VERSION ""

NS_ :

BS_:

BU_: ETH

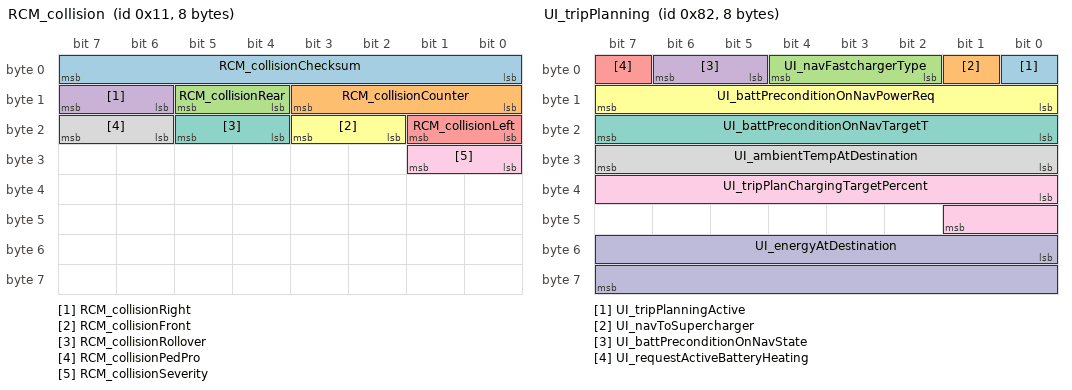
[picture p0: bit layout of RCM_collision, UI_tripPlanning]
BO_ 17 RCM_collision: 8 Vector__XXX
 SG_ RCM_collisionChecksum : 0|8@1+ (1,0) [0|0] "" Vector__XXX
 SG_ RCM_collisionCounter : 8|4@1+ (1,0) [0|0] "" Vector__XXX
 SG_ RCM_collisionRear : 12|2@1+ (1,0) [0|0] "" Vector__XXX
 SG_ RCM_collisionRight : 14|2@1+ (1,0) [0|0] "" Vector__XXX
 SG_ RCM_collisionLeft : 16|2@1+ (1,0) [0|0] "" Vector__XXX
 SG_ RCM_collisionFront : 18|2@1+ (1,0) [0|0] "" Vector__XXX
 SG_ RCM_collisionRollover : 20|2@1+ (1,0) [0|0] "" Vector__XXX
 SG_ RCM_collisionPedPro : 22|2@1+ (1,0) [0|0] "" Vector__XXX
 SG_ RCM_collisionSeverity : 24|2@1+ (1,0) [0|0] "" Vector__XXX

BO_ 79 UI_locationStatus: 8 Vector__XXX
 SG_ UI_latitude : 0|28@1- (1e-06,0) [0|0] "" Vector__XXX
 SG_ UI_longitude : 28|29@1- (1e-06,0) [0|0] "" Vector__XXX
 SG_ UI_gpsAccuracy : 57|7@1+ (0.2,0) [0|0] "" Vector__XXX

BO_ 130 UI_tripPlanning: 8 Vector__XXX
 SG_ UI_tripPlanningActive : 0|1@1+ (1,0) [0|0] "" Vector__XXX
 SG_ UI_navToSupercharger : 1|1@1+ (1,0) [0|0] "" Vector__XXX
 SG_ UI_navFastchargerType : 2|3@1+ (1,0) [0|0] "" Vector__XXX
 SG_ UI_battPreconditionOnNavState : 5|2@1+ (1,0) [0|0] "" Vector__XXX
 SG_ UI_requestActiveBatteryHeating : 7|1@1+ (1,0) [0|0] "" Vector__XXX
 SG_ UI_battPreconditionOnNavPowerReq : 8|8@1- (125,0) [0|0] "" Vector__XXX
 SG_ UI_battPreconditionOnNavTargetT : 16|8@1+ (0.25,0) [0|0] "" Vector__XXX
 SG_ UI_ambientTempAtDestination : 24|8@1- (0.5,0) [0|0] "" Vector__XXX
 SG_ UI_tripPlanChargingTargetPercent : 32|10@1+ (0.1,0) [0|0] "" Vector__XXX
 SG_ UI_energyAtDestination : 48|16@1- (0.01,0) [0|0] "" Vector__XXX

BO_ 258 VCLEFT_doorStatus: 8 Vector__XXX
 SG_ VCLEFT_doorClosureStatusFront : 0|4@1+ (1,0) [0|0] "" Vector__XXX
 SG_ VCLEFT_doorClosureStatusRear : 4|4@1+ (1,0) [0|0] "" Vector__XXX
 SG_ VCLEFT_frontLatchSwitch : 8|1@1+ (1,0) [0|0] "" Vector__XXX
 SG_ VCLEFT_rearLatchSwitch : 9|1@1+ (1,0) [0|0] "" Vector__XXX
 SG_ VCLEFT_frontHandlePulled : 10|1@1+ (1,0) [0|0] "" Vector__XXX
 SG_ VCLEFT_rearHandlePulled : 11|1@1+ (1,0) [0|0] "" Vector__XXX
 SG_ VCLEFT_frontRelActuatorSwitch : 12|1@1+ (1,0) [0|0] "" Vector__XXX
 SG_ VCLEFT_rearRelActuatorSwitch : 13|1@1+ (1,0) [0|0] "" Vector__XXX
 SG_ VCLEFT_frontLatchStatus : 14|4@1+ (1,0) [0|0] "" Vector__XXX
 SG_ VCLEFT_rearLatchStatus : 18|4@1+ (1,0) [0|0] "" Vector__XXX
 SG_ VCLEFT_lastDoorReqSourceFront : 22|3@1+ (1,0) [0|0] "" Vector__XXX
 SG_ VCLEFT_lastDoorReqSourceRear : 25|3@1+ (1,0) [0|0] "" Vector__XXX
 SG_ VCLEFT_frontIntSwitchFaulted : 28|1@1+ (1,0) [0|0] "" Vector__XXX
 SG_ VCLEFT_rearIntSwitchFaulted : 29|1@1+ (1,0) [0|0] "" Vector__XXX
 SG_ VCLEFT_frontIntSwitchPressed : 31|1@1+ (1,0) [0|0] "" Vector__XXX
 SG_ VCLEFT_rearIntSwitchPressed : 32|1@1+ (1,0) [0|0] "" Vector__XXX
 SG_ VCLEFT_mirrorTiltXPosition : 33|8@1+ (0.02,0) [0|0] "" Vector__XXX
 SG_ VCLEFT_mirrorTiltYPosition : 41|8@1+ (0.02,0) [0|0] "" Vector__XXX
 SG_ VCLEFT_mirrorState : 49|3@1+ (1,0) [0|0] "" Vector__XXX
 SG_ VCLEFT_mirrorFoldState : 52|3@1+ (1,0) [0|0] "" Vector__XXX
 SG_ VCLEFT_mirrorRecallState : 55|3@1+ (1,0) [0|0] "" Vector__XXX
 SG_ VCLEFT_mirrorHeatState : 58|3@1+ (1,0) [0|0] "" Vector__XXX
 SG_ VCLEFT_rearHandlePulledPersist : 61|1@1+ (1,0) [0|0] "" Vector__XXX
 SG_ VCLEFT_frontHandlePulledPersist : 62|1@1+ (1,0) [0|0] "" Vector__XXX
 SG_ VCLEFT_mirrorDipped : 63|1@1+ (1,0) [0|0] "" Vector__XXX

BO_ 259 VCRIGHT_doorStatus: 8 Vector__XXX
 SG_ VCRIGHT_doorClosureStatusFront : 0|4@1+ (1,0) [0|0] "" Vector__XXX
 SG_ VCRIGHT_doorClosureStatusRear : 4|4@1+ (1,0) [0|0] "" Vector__XXX
 SG_ VCRIGHT_frontLatchSwitch : 8|1@1+ (1,0) [0|0] "" Vector__XXX
 SG_ VCRIGHT_rearLatchSwitch : 9|1@1+ (1,0) [0|0] "" Vector__XXX
 SG_ VCRIGHT_frontHandlePulled : 10|1@1+ (1,0) [0|0] "" Vector__XXX
 SG_ VCRIGHT_rearHandlePulled : 11|1@1+ (1,0) [0|0] "" Vector__XXX
 SG_ VCRIGHT_frontRelActuatorSwitch : 12|1@1+ (1,0) [0|0] "" Vector__XXX
 SG_ VCRIGHT_rearRelActuatorSwitch : 13|1@1+ (1,0) [0|0] "" Vector__XXX
 SG_ VCRIGHT_frontLatchStatus : 14|4@1+ (1,0) [0|0] "" Vector__XXX
 SG_ VCRIGHT_rearLatchStatus : 18|4@1+ (1,0) [0|0] "" Vector__XXX
 SG_ VCRIGHT_lastDoorReqSourceFront : 22|3@1+ (1,0) [0|0] "" Vector__XXX
 SG_ VCRIGHT_lastDoorReqSourceRear : 25|3@1+ (1,0) [0|0] "" Vector__XXX
 SG_ VCRIGHT_frontIntSwitchFaulted : 28|1@1+ (1,0) [0|0] "" Vector__XXX
 SG_ VCRIGHT_rearIntSwitchFaulted : 29|1@1+ (1,0) [0|0] "" Vector__XXX
 SG_ VCRIGHT_frontHandlePulledPersist : 30|1@1+ (1,0) [0|0] "" Vector__XXX
 SG_ VCRIGHT_frontIntSwitchPressed : 31|1@1+ (1,0) [0|0] "" Vector__XXX
 SG_ VCRIGHT_rearIntSwitchPressed : 32|1@1+ (1,0) [0|0] "" Vector__XXX
 SG_ VCRIGHT_mirrorTiltXPosition : 33|8@1+ (0.02,0) [0|0] "" Vector__XXX
 SG_ VCRIGHT_mirrorTiltYPosition : 41|8@1+ (0.02,0) [0|0] "" Vector__XXX
 SG_ VCRIGHT_mirrorState : 49|3@1+ (1,0) [0|0] "" Vector__XXX
 SG_ VCRIGHT_mirrorFoldState : 52|3@1+ (1,0) [0|0] "" Vector__XXX
 SG_ VCRIGHT_mirrorDipped : 55|1@1+ (1,0) [0|0] "" Vector__XXX
 SG_ VCRIGHT_trunkLatchStatus : 56|4@1+ (1,0) [0|0] "" Vector__XXX
 SG_ VCRIGHT_mirrorRecallState : 60|3@1+ (1,0) [0|0] "" Vector__XXX
 SG_ VCRIGHT_rearHandlePulledPersist : 63|1@1+ (1,0) [0|0] "" Vector__XXX

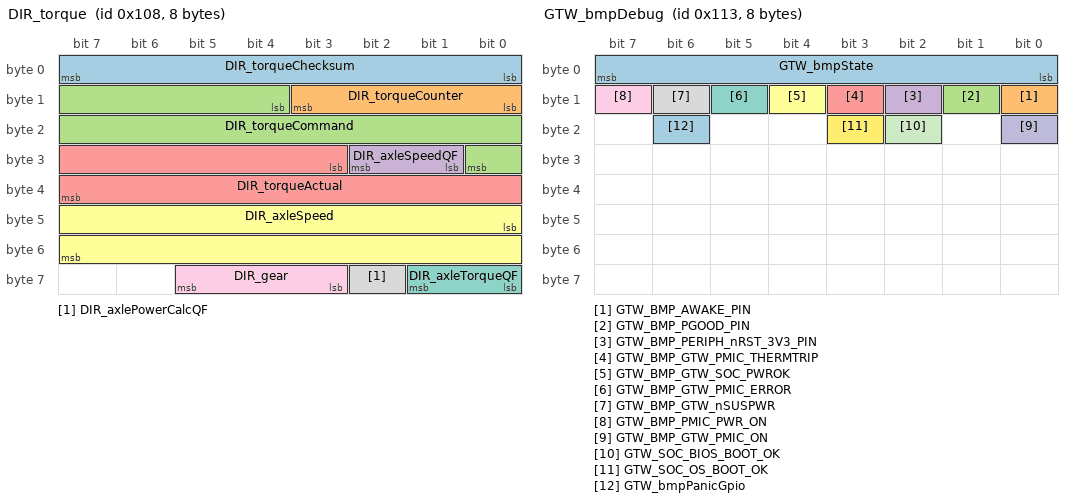
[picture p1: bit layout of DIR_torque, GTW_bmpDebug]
BO_ 264 DIR_torque: 8 Vector__XXX
 SG_ DIR_torqueChecksum : 0|8@1+ (1,0) [0|0] "" Vector__XXX
 SG_ DIR_torqueCounter : 8|4@1+ (1,0) [0|0] "" Vector__XXX
 SG_ DIR_torqueCommand : 12|13@1- (2,0) [0|0] "" Vector__XXX
 SG_ DIR_axleSpeedQF : 25|2@1+ (1,0) [0|0] "" Vector__XXX
 SG_ DIR_torqueActual : 27|13@1- (2,0) [0|0] "" Vector__XXX
 SG_ DIR_axleSpeed : 40|16@1- (0.1,0) [0|0] "" Vector__XXX
 SG_ DIR_axleTorqueQF : 56|2@1+ (1,0) [0|0] "" Vector__XXX
 SG_ DIR_axlePowerCalcQF : 58|1@1+ (1,0) [0|0] "" Vector__XXX
 SG_ DIR_gear : 59|3@1+ (1,0) [0|0] "" Vector__XXX

BO_ 275 GTW_bmpDebug: 8 Vector__XXX
 SG_ GTW_bmpState : 7|8@0+ (1,0) [0|0] "" Vector__XXX
 SG_ GTW_BMP_AWAKE_PIN : 8|1@1+ (1,0) [0|0] "" Vector__XXX
 SG_ GTW_BMP_PGOOD_PIN : 9|1@1+ (1,0) [0|0] "" Vector__XXX
 SG_ GTW_BMP_PERIPH_nRST_3V3_PIN : 10|1@1+ (1,0) [0|0] "" Vector__XXX
 SG_ GTW_BMP_GTW_PMIC_THERMTRIP : 11|1@1+ (1,0) [0|0] "" Vector__XXX
 SG_ GTW_BMP_GTW_SOC_PWROK : 12|1@1+ (1,0) [0|0] "" Vector__XXX
 SG_ GTW_BMP_GTW_PMIC_ERROR : 13|1@1+ (1,0) [0|0] "" Vector__XXX
 SG_ GTW_BMP_GTW_nSUSPWR : 14|1@1+ (1,0) [0|0] "" Vector__XXX
 SG_ GTW_BMP_PMIC_PWR_ON : 15|1@1+ (1,0) [0|0] "" Vector__XXX
 SG_ GTW_BMP_GTW_PMIC_ON : 16|1@1+ (1,0) [0|0] "" Vector__XXX
 SG_ GTW_SOC_BIOS_BOOT_OK : 18|1@1+ (1,0) [0|0] "" Vector__XXX
 SG_ GTW_SOC_OS_BOOT_OK : 19|1@1+ (1,0) [0|0] "" Vector__XXX
 SG_ GTW_bmpPanicGpio : 22|1@0+ (1,0) [0|0] "" Vector__XXX

BO_ 280 DI_systemStatus: 8 Vector__XXX
 SG_ DI_systemStatusChecksum : 0|8@1+ (1,0) [0|0] "" Vector__XXX
 SG_ DI_systemStatusCounter : 8|4@1+ (1,0) [0|0] "" Vector__XXX
 SG_ DI_immobilizerState : 13|3@1+ (1,0) [0|0] "" Vector__XXX
 SG_ DI_systemState : 16|3@1+ (1,0) [0|0] "" Vector__XXX
 SG_ DI_brakePedalState : 19|2@1+ (1,0) [0|0] "" Vector__XXX
 SG_ DI_gear : 21|3@1+ (1,0) [0|0] "" Vector__XXX
 SG_ DI_driveBlocked : 24|3@1+ (1,0) [0|0] "" Vector__XXX
 SG_ DI_hvilSystemStatus : 27|2@1+ (1,0) [0|0] "" Vector__XXX
 SG_ DI_accelPedalPos : 32|8@1+ (0.4,0) [0|0] "" Vector__XXX
 SG_ DI_tractionControlMode : 40|3@1+ (1,0) [0|0] "" Vector__XXX
 SG_ DI_dynoModeAvailable : 43|1@1+ (1,0) [0|0] "" Vector__XXX
 SG_ DI_epbRequest : 44|2@1+ (1,0) [0|0] "" Vector__XXX
 SG_ DI_eepDeliveryBitStatus : 46|1@1+ (1,0) [0|0] "" Vector__XXX
 SG_ DI_keepDrivePowerStateRequest : 47|1@1+ (1,0) [0|0] "" Vector__XXX
 SG_ DI_trackModeState : 48|2@1+ (1,0) [0|0] "" Vector__XXX
 SG_ DI_manualDrivingProhibited : 50|1@1+ (1,0) [0|0] "" Vector__XXX
 SG_ DI_regenLight : 51|1@1+ (1,0) [0|0] "" Vector__XXX
 SG_ DI_vehicleAcceleration : 52|12@1- (0.01,0) [0|0] "" Vector__XXX

BO_ 281 VCSEC_requests2: 8 Vector__XXX
 SG_ VCSEC_hvacRunScreenProtectOnly : 15|1@1+ (1,0) [0|0] "" Vector__XXX
 SG_ VCSEC_chargeHandleRequestModel : 16|4@1+ (1,0) [0|0] "" Vector__XXX
 SG_ VCSEC_recoveryModeRequested : 21|1@1+ (1,0) [0|0] "" Vector__XXX
 SG_ VCSEC_infotainmentResetRequested : 22|1@1+ (1,0) [0|0] "" Vector__XXX
 SG_ VCSEC_mobileToAPRequest : 23|3@1+ (1,0) [0|0] "" Vector__XXX
 SG_ VCSEC_riderKeyPresent : 26|1@1+ (1,0) [0|0] "" Vector__XXX

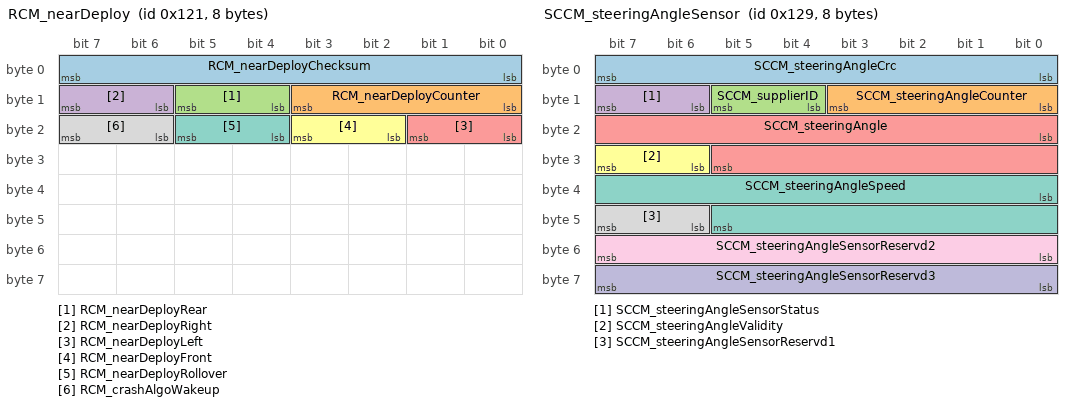
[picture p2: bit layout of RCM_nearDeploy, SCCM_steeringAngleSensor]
BO_ 289 RCM_nearDeploy: 8 Vector__XXX
 SG_ RCM_nearDeployChecksum : 0|8@1+ (1,0) [0|0] "" Vector__XXX
 SG_ RCM_nearDeployCounter : 8|4@1+ (1,0) [0|0] "" Vector__XXX
 SG_ RCM_nearDeployRear : 12|2@1+ (1,0) [0|0] "" Vector__XXX
 SG_ RCM_nearDeployRight : 14|2@1+ (1,0) [0|0] "" Vector__XXX
 SG_ RCM_nearDeployLeft : 16|2@1+ (1,0) [0|0] "" Vector__XXX
 SG_ RCM_nearDeployFront : 18|2@1+ (1,0) [0|0] "" Vector__XXX
 SG_ RCM_nearDeployRollover : 20|2@1+ (1,0) [0|0] "" Vector__XXX
 SG_ RCM_crashAlgoWakeup : 22|2@1+ (1,0) [0|0] "" Vector__XXX

BO_ 290 VCLEFT_doorStatus2: 8 Vector__XXX
 SG_ VCLEFT_doorStatus2Index M : 0|1@1+ (1,0) [0|0] "" Vector__XXX
 SG_ VCLEFT_frontLatchRelDuty m1 : 8|8@1+ (1,0) [0|0] "" Vector__XXX
 SG_ VCLEFT_rearLatchRelDuty m0 : 8|8@1+ (1,0) [0|0] "" Vector__XXX
 SG_ VCLEFT_BPillarCameraHeaterState m1 : 16|3@1+ (1,0) [0|0] "" Vector__XXX
 SG_ VCLEFT_vehicleInMotion m0 : 16|1@1+ (1,0) [0|0] "" Vector__XXX
 SG_ VCLEFT_frontDoorState m0 : 17|3@1+ (1,0) [0|0] "" Vector__XXX
 SG_ VCLEFT_rearDoorState m0 : 20|3@1+ (1,0) [0|0] "" Vector__XXX
 SG_ VCLEFT_frontHandleRawStatus m0 : 24|3@1+ (1,0) [0|0] "" Vector__XXX
 SG_ VCLEFT_rearHandleRawStatus m0 : 27|3@1+ (1,0) [0|0] "" Vector__XXX
 SG_ VCLEFT_mirrorFoldType m0 : 30|2@1+ (1,0) [0|0] "" Vector__XXX
 SG_ VCLEFT_frontHandleDebounceStatus m0 : 32|3@1+ (1,0) [0|0] "" Vector__XXX
 SG_ VCLEFT_rearHandleDebounceStatus m0 : 35|3@1+ (1,0) [0|0] "" Vector__XXX
 SG_ VCLEFT_frontHandle5vEnable m0 : 38|1@1+ (1,0) [0|0] "" Vector__XXX
 SG_ VCLEFT_rearHandle5vEnable m0 : 39|1@1+ (1,0) [0|0] "" Vector__XXX
 SG_ VCLEFT_BPillarCameraHeaterCurrent m1 : 40|6@1+ (0.02,0) [0|0] "" Vector__XXX
 SG_ VCLEFT_mirrorFoldCurrent m0 : 40|7@1- (0.05,0) [0|0] "" Vector__XXX
 SG_ VCLEFT_mirrorDimmed m0 : 47|1@1+ (1,0) [0|0] "" Vector__XXX
 SG_ VCLEFT_frontHandlePWM m0 : 48|7@1+ (1,0) [0|0] "" Vector__XXX
 SG_ VCLEFT_mirrorTiltXOffset m1 : 48|8@1- (0.02,0) [0|0] "" Vector__XXX
 SG_ VCLEFT_mirrorTiltYOffset m1 : 56|8@1- (0.02,0) [0|0] "" Vector__XXX
 SG_ VCLEFT_rearHandlePWM m0 : 56|7@1+ (1,0) [0|0] "" Vector__XXX

BO_ 291 VCRIGHT_doorStatus2: 8 Vector__XXX
 SG_ VCRIGHT_doorStatus2Index M : 0|1@1+ (1,0) [0|0] "" Vector__XXX
 SG_ VCRIGHT_frontLatchRelDuty m1 : 8|8@1+ (1,0) [0|0] "" Vector__XXX
 SG_ VCRIGHT_rearLatchRelDuty m0 : 8|8@1+ (1,0) [0|0] "" Vector__XXX
 SG_ VCRIGHT_BPillarCameraHeaterState m1 : 16|3@1+ (1,0) [0|0] "" Vector__XXX
 SG_ VCRIGHT_vehicleInMotion m0 : 16|1@1+ (1,0) [0|0] "" Vector__XXX
 SG_ VCRIGHT_frontDoorState m0 : 17|3@1+ (1,0) [0|0] "" Vector__XXX
 SG_ VCRIGHT_rearDoorState m0 : 20|3@1+ (1,0) [0|0] "" Vector__XXX
 SG_ VCRIGHT_mirrorDimmed m0 : 23|1@1+ (1,0) [0|0] "" Vector__XXX
 SG_ VCRIGHT_frontHandleRawStatus m0 : 24|3@1+ (1,0) [0|0] "" Vector__XXX
 SG_ VCRIGHT_rearHandleRawStatus m0 : 27|3@1+ (1,0) [0|0] "" Vector__XXX
 SG_ VCRIGHT_mirrorFoldType m0 : 30|2@1+ (1,0) [0|0] "" Vector__XXX
 SG_ VCRIGHT_frontHandleDebounceStatus m0 : 32|3@1+ (1,0) [0|0] "" Vector__XXX
 SG_ VCRIGHT_rearHandleDebounceStatus m0 : 35|3@1+ (1,0) [0|0] "" Vector__XXX
 SG_ VCRIGHT_frontHandle5vEnable m0 : 38|1@1+ (1,0) [0|0] "" Vector__XXX
 SG_ VCRIGHT_rearHandle5vEnable m0 : 39|1@1+ (1,0) [0|0] "" Vector__XXX
 SG_ VCRIGHT_BPillarCameraHeaterCurrent m1 : 40|6@1+ (0.02,0) [0|0] "" Vector__XXX
 SG_ VCRIGHT_mirrorFoldCurrent m0 : 40|7@1- (0.05,0) [0|0] "" Vector__XXX
 SG_ VCRIGHT_gloveboxOutput m0 : 47|1@1+ (1,0) [0|0] "" Vector__XXX
 SG_ VCRIGHT_mirrorTiltXOffset m1 : 48|8@1- (0.02,0) [0|0] "" Vector__XXX
 SG_ VCRIGHT_rearDefrostCurrentFiltered m0 : 48|7@1+ (1,0) [0|0] "" Vector__XXX
 SG_ VCRIGHT_mirrorTiltYOffset m1 : 56|8@1- (0.02,0) [0|0] "" Vector__XXX
 SG_ VCRIGHT_trunkRatchetSwitch m0 : 61|1@1+ (1,0) [0|0] "" Vector__XXX
 SG_ VCRIGHT_trunkPawlSwitch m0 : 62|1@1+ (1,0) [0|0] "" Vector__XXX
 SG_ VCRIGHT_trunkHomeSwitch m0 : 63|1@1+ (1,0) [0|0] "" Vector__XXX

BO_ 294 DIR_motorStatus: 8 Vector__XXX
 SG_ DIR_motorCurrent : 0|11@1+ (1,0) [0|0] "" Vector__XXX
 SG_ DIR_switchingFrequency : 11|11@1+ (0.01,0) [0|0] "" Vector__XXX
 SG_ DIR_targetFluxMode : 22|2@1+ (1,0) [0|0] "" Vector__XXX
 SG_ DIR_switchShortTestRetryCount : 24|2@1+ (1,0) [0|0] "" Vector__XXX
 SG_ DIR_keepAliveRequest : 26|1@1+ (1,0) [0|0] "" Vector__XXX
 SG_ DIR_motorStatusCounter : 27|4@1+ (1,0) [0|0] "" Vector__XXX
 SG_ DIR_motorStatusChecksum : 32|8@1+ (1,0) [0|0] "" Vector__XXX

BO_ 296 DI_systemLimits: 8 Vector__XXX
 SG_ DI_limitRegenPower : 0|1@1+ (1,0) [0|0] "" Vector__XXX
 SG_ DI_limitIBat : 1|1@1+ (1,0) [0|0] "" Vector__XXX
 SG_ DI_limitVBatLow : 2|1@1+ (1,0) [0|0] "" Vector__XXX
 SG_ DI_limitVBatHigh : 3|1@1+ (1,0) [0|0] "" Vector__XXX
 SG_ DI_limitObstacleDetection : 4|1@1+ (1,0) [0|0] "" Vector__XXX
 SG_ DI_limitSystemLimp : 5|1@1+ (1,0) [0|0] "" Vector__XXX
 SG_ DI_limitSystemGPO : 6|1@1+ (1,0) [0|0] "" Vector__XXX
 SG_ DI_limitShift : 7|1@1+ (1,0) [0|0] "" Vector__XXX
 SG_ DI_limitDriveTorque : 8|1@1+ (1,0) [0|0] "" Vector__XXX
 SG_ DI_limitRegenTorque : 9|1@1+ (1,0) [0|0] "" Vector__XXX
 SG_ DI_limitVehicleSpeed : 10|1@1+ (1,0) [0|0] "" Vector__XXX
 SG_ DI_limitBmsMiaFreeze : 11|1@1+ (1,0) [0|0] "" Vector__XXX
 SG_ DI_limitSystemSpinDownLearning : 12|1@1+ (1,0) [0|0] "" Vector__XXX
 SG_ DI_limitCdp : 13|1@1+ (1,0) [0|0] "" Vector__XXX
 SG_ DI_vehicleSpeedLimitType : 14|2@1+ (1,0) [0|0] "" Vector__XXX
 SG_ DI_vehicleSpeedLimit : 16|9@1+ (1,0) [0|0] "" Vector__XXX
 SG_ DI_vehicleSpeedLimitReason : 25|4@1+ (1,0) [0|0] "" Vector__XXX
 SG_ DI_limitClosureNotClosed : 29|1@1+ (1,0) [0|0] "" Vector__XXX
 SG_ DI_proximity : 30|1@1+ (1,0) [0|0] "" Vector__XXX
 SG_ DI_undersideAbuse : 31|1@1+ (1,0) [0|0] "" Vector__XXX

BO_ 297 SCCM_steeringAngleSensor: 8 Vector__XXX
 SG_ SCCM_steeringAngleCrc : 0|8@1+ (1,0) [0|0] "" Vector__XXX
 SG_ SCCM_steeringAngleCounter : 8|4@1+ (1,0) [0|0] "" Vector__XXX
 SG_ SCCM_supplierID : 12|2@1+ (1,0) [0|0] "" Vector__XXX
 SG_ SCCM_steeringAngleSensorStatus : 14|2@1+ (1,0) [0|0] "" Vector__XXX
 SG_ SCCM_steeringAngle : 16|14@1+ (0.1,-819.2) [0|0] "" Vector__XXX
 SG_ SCCM_steeringAngleValidity : 30|2@1+ (1,0) [0|0] "" Vector__XXX
 SG_ SCCM_steeringAngleSpeed : 32|14@1+ (0.5,-4096) [0|0] "" Vector__XXX
 SG_ SCCM_steeringAngleSensorReservd1 : 46|2@1+ (1,0) [0|0] "" Vector__XXX
 SG_ SCCM_steeringAngleSensorReservd2 : 48|8@1+ (1,0) [0|0] "" Vector__XXX
 SG_ SCCM_steeringAngleSensorReservd3 : 56|8@1+ (1,0) [0|0] "" Vector__XXX

BO_ 306 BMS_hvBusStatus: 8 Vector__XXX
 SG_ BMS_dcLinkVoltage : 0|16@1+ (0.01,0) [0|0] "" Vector__XXX
 SG_ BMS_packCurrent : 16|16@1- (0.1,0) [0|0] "" Vector__XXX
 SG_ BMS_currentUnfiltered : 32|16@1- (0.05,-822) [0|0] "" Vector__XXX

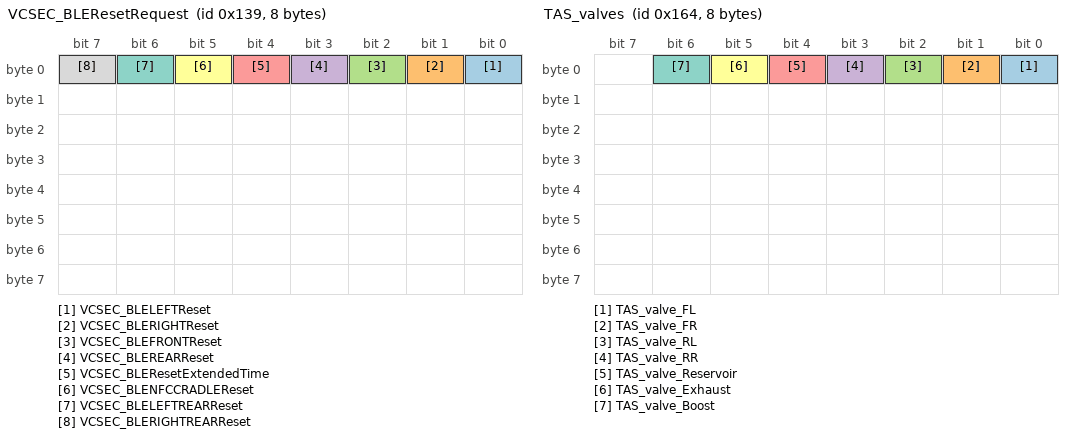
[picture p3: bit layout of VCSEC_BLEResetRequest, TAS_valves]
BO_ 313 VCSEC_BLEResetRequest: 8 Vector__XXX
 SG_ VCSEC_BLELEFTReset : 0|1@1+ (1,0) [0|0] "" Vector__XXX
 SG_ VCSEC_BLERIGHTReset : 1|1@1+ (1,0) [0|0] "" Vector__XXX
 SG_ VCSEC_BLEFRONTReset : 2|1@1+ (1,0) [0|0] "" Vector__XXX
 SG_ VCSEC_BLEREARReset : 3|1@1+ (1,0) [0|0] "" Vector__XXX
 SG_ VCSEC_BLEResetExtendedTime : 4|1@1+ (1,0) [0|0] "" Vector__XXX
 SG_ VCSEC_BLENFCCRADLEReset : 5|1@1+ (1,0) [0|0] "" Vector__XXX
 SG_ VCSEC_BLELEFTREARReset : 6|1@1+ (1,0) [0|0] "" Vector__XXX
 SG_ VCSEC_BLERIGHTREARReset : 7|1@1+ (1,0) [0|0] "" Vector__XXX

BO_ 322 VCLEFT_liftgateStatus: 8 Vector__XXX
 SG_ VCLEFT_liftgateStatusIndex M : 0|2@1+ (1,0) [0|0] "" Vector__XXX
 SG_ VCLEFT_liftgateState m0 : 3|4@1+ (1,0) [0|0] "" Vector__XXX
 SG_ VCLEFT_liftgateStrutDutyCycle m1 : 3|8@1- (1,0) [0|0] "" Vector__XXX
 SG_ VCLEFT_liftgateStoppingCondition m0 : 10|4@1+ (1,0) [0|0] "" Vector__XXX
 SG_ VCLEFT_liftgateStrutCurrent m1 : 11|10@1- (0.1,0) [0|0] "" Vector__XXX
 SG_ VCLEFT_liftgateMvmntNotAllowedCondition m0 : 14|3@1+ (1,0) [0|0] "" Vector__XXX
 SG_ VCLEFT_liftgatePositionCalibrated m0 : 17|1@1+ (1,0) [0|0] "" Vector__XXX
 SG_ VCLEFT_liftgateUIChimeRequest m0 : 18|3@1+ (1,0) [0|0] "" Vector__XXX
 SG_ VCLEFT_liftgatePhysicalChimeRequest m0 : 21|3@1+ (1,0) [0|0] "" Vector__XXX
 SG_ VCLEFT_liftgatePosition m1 : 21|7@1- (1,46) [0|0] "" Vector__XXX
 SG_ VCLEFT_liftgateEstimatedStrutTemp m0 : 24|8@1+ (1,-60) [0|0] "" Vector__XXX
 SG_ VCLEFT_liftgateSpeed m1 : 28|10@1- (0.1,0) [0|0] "" Vector__XXX
 SG_ VCLEFT_liftgateStaticStrutMode m0 : 32|3@1+ (1,0) [0|0] "" Vector__XXX
 SG_ VCLEFT_liftgateRequestSource m0 : 35|4@1+ (1,0) [0|0] "" Vector__XXX
 SG_ VCLEFT_liftgateHeight m1 : 38|8@1+ (1,0) [0|0] "" Vector__XXX
 SG_ VCLEFT_liftgateNewHeightNudge m0 : 39|1@1+ (1,0) [0|0] "" Vector__XXX
 SG_ VCLEFT_liftgateNewSaveHeight m0 : 40|8@1+ (1,0) [0|0] "" Vector__XXX
 SG_ VCLEFT_liftgateGeofenceState m0 : 48|2@1+ (1,0) [0|0] "" Vector__XXX
 SG_ VCLEFT_liftgateAboveCrossoverAngle m0 : 59|1@1+ (1,0) [0|0] "" Vector__XXX
 SG_ VCLEFT_liftgateLatchRequest m0 : 61|3@1+ (1,0) [0|0] "" Vector__XXX

BO_ 356 TAS_valves: 8 Vector__XXX
 SG_ TAS_valve_FL : 0|1@1+ (1,0) [0|0] "" Vector__XXX
 SG_ TAS_valve_FR : 1|1@1+ (1,0) [0|0] "" Vector__XXX
 SG_ TAS_valve_RL : 2|1@1+ (1,0) [0|0] "" Vector__XXX
 SG_ TAS_valve_RR : 3|1@1+ (1,0) [0|0] "" Vector__XXX
 SG_ TAS_valve_Reservoir : 4|1@1+ (1,0) [0|0] "" Vector__XXX
 SG_ TAS_valve_Exhaust : 5|1@1+ (1,0) [0|0] "" Vector__XXX
 SG_ TAS_valve_Boost : 6|1@1+ (1,0) [0|0] "" Vector__XXX

BO_ 357 TAS_voltages: 8 Vector__XXX
 SG_ TAS_12V_supply : 0|8@1+ (0.075,0) [0|0] "" Vector__XXX
 SG_ TAS_12V_switched : 8|8@1+ (0.075,0) [0|0] "" Vector__XXX
 SG_ TAS_5V_heightSensors : 16|8@1+ (0.025,0) [0|0] "" Vector__XXX
 SG_ TAS_5V_analogSensors : 24|8@1+ (0.025,0) [0|0] "" Vector__XXX
 SG_ TAS_5V_onboard : 32|8@1+ (0.025,0) [0|0] "" Vector__XXX

BO_ 358 TAS_temperatures: 8 Vector__XXX
 SG_ TAS_tempIndex M : 0|2@1+ (1,0) [0|0] "" Vector__XXX
 SG_ TAS_temp_FL_C m0 : 8|8@1+ (1,-40) [0|0] "" Vector__XXX
 SG_ TAS_temp_K_HSD m2 : 8|8@1+ (1,-40) [0|0] "" Vector__XXX
 SG_ TAS_temp_RL_C m1 : 8|8@1+ (1,-40) [0|0] "" Vector__XXX
 SG_ TAS_temp_FL_R m0 : 16|8@1+ (1,-40) [0|0] "" Vector__XXX
 SG_ TAS_temp_RL_R m1 : 16|8@1+ (1,-40) [0|0] "" Vector__XXX
 SG_ TAS_temp_VBAT_SW m2 : 16|8@1+ (1,-40) [0|0] "" Vector__XXX
 SG_ TAS_temp_FL_K m0 : 24|8@1+ (1,-40) [0|0] "" Vector__XXX
 SG_ TAS_temp_RL_K m1 : 24|8@1+ (1,-40) [0|0] "" Vector__XXX
 SG_ TAS_temp_FR_C m0 : 32|8@1+ (1,-40) [0|0] "" Vector__XXX
 SG_ TAS_temp_RR_C m1 : 32|8@1+ (1,-40) [0|0] "" Vector__XXX
 SG_ TAS_temp_FR_R m0 : 40|8@1+ (1,-40) [0|0] "" Vector__XXX
 SG_ TAS_temp_RR_R m1 : 40|8@1+ (1,-40) [0|0] "" Vector__XXX
 SG_ TAS_temp_FR_K m0 : 48|8@1+ (1,-40) [0|0] "" Vector__XXX
 SG_ TAS_temp_RR_K m1 : 48|8@1+ (1,-40) [0|0] "" Vector__XXX
 SG_ TAS_temp_F_CR_HSD m0 : 56|8@1+ (1,-40) [0|0] "" Vector__XXX
 SG_ TAS_temp_R_CR_HSD m1 : 56|8@1+ (1,-40) [0|0] "" Vector__XXX

BO_ 359 TAS_currentsSpring: 8 Vector__XXX
 SG_ TAS_current_FL_K : 0|8@1+ (0.01,0) [0|0] "" Vector__XXX
 SG_ TAS_current_FR_K : 8|8@1+ (0.01,0) [0|0] "" Vector__XXX
 SG_ TAS_current_RL_K : 16|8@1+ (0.01,0) [0|0] "" Vector__XXX
 SG_ TAS_current_RR_K : 24|8@1+ (0.01,0) [0|0] "" Vector__XXX

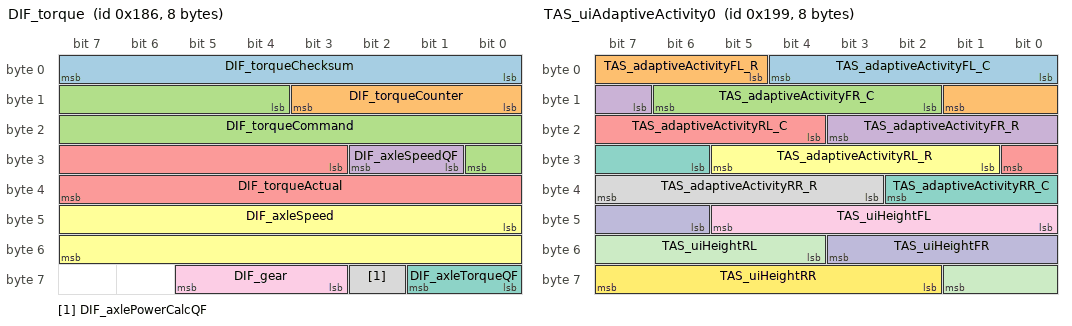
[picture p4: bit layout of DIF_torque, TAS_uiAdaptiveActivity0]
BO_ 390 DIF_torque: 8 Vector__XXX
 SG_ DIF_torqueChecksum : 0|8@1+ (1,0) [0|0] "" Vector__XXX
 SG_ DIF_torqueCounter : 8|4@1+ (1,0) [0|0] "" Vector__XXX
 SG_ DIF_torqueCommand : 12|13@1- (2,0) [0|0] "" Vector__XXX
 SG_ DIF_axleSpeedQF : 25|2@1+ (1,0) [0|0] "" Vector__XXX
 SG_ DIF_torqueActual : 27|13@1- (2,0) [0|0] "" Vector__XXX
 SG_ DIF_axleSpeed : 40|16@1- (0.1,0) [0|0] "" Vector__XXX
 SG_ DIF_axleTorqueQF : 56|2@1+ (1,0) [0|0] "" Vector__XXX
 SG_ DIF_axlePowerCalcQF : 58|1@1+ (1,0) [0|0] "" Vector__XXX
 SG_ DIF_gear : 59|3@1+ (1,0) [0|0] "" Vector__XXX

BO_ 405 DIF_limits: 8 Vector__XXX
 SG_ DIF_limitPCBTemp : 0|1@1+ (1,0) [0|0] "" Vector__XXX
 SG_ DIF_limitInverterTemp : 1|1@1+ (1,0) [0|0] "" Vector__XXX
 SG_ DIF_limitStatorTemp : 2|1@1+ (1,0) [0|0] "" Vector__XXX
 SG_ DIF_limitPoleTemp : 3|1@1+ (1,0) [0|0] "" Vector__XXX
 SG_ DIF_limitUnitLimp : 4|1@1+ (1,0) [0|0] "" Vector__XXX
 SG_ DIF_limitDeltaFluidTemp : 5|1@1+ (1,0) [0|0] "" Vector__XXX
 SG_ DIF_limitDischargePower : 6|1@1+ (1,0) [0|0] "" Vector__XXX
 SG_ DIF_limitMotorCurrent : 7|1@1+ (1,0) [0|0] "" Vector__XXX
 SG_ DIF_limitMotorVoltage : 8|1@1+ (1,0) [0|0] "" Vector__XXX
 SG_ DIF_limitTCDrive : 9|1@1+ (1,0) [0|0] "" Vector__XXX
 SG_ DIF_limitTCRegen : 10|1@1+ (1,0) [0|0] "" Vector__XXX
 SG_ DIF_limitBaseSpeed : 11|1@1+ (1,0) [0|0] "" Vector__XXX
 SG_ DIF_limitDcCapTemp : 12|1@1+ (1,0) [0|0] "" Vector__XXX
 SG_ DIF_limitMotorSpeed : 13|1@1+ (1,0) [0|0] "" Vector__XXX
 SG_ DIF_limitDiff : 14|1@1+ (1,0) [0|0] "" Vector__XXX
 SG_ DIF_limitUnitGPO : 15|1@1+ (1,0) [0|0] "" Vector__XXX
 SG_ DIF_limitShockTorque : 16|1@1+ (1,0) [0|0] "" Vector__XXX
 SG_ DIF_limitOilPumpFluidTemp : 17|1@1+ (1,0) [0|0] "" Vector__XXX
 SG_ DIF_limitStatorFrequency : 18|1@1+ (1,0) [0|0] "" Vector__XXX
 SG_ DIF_limitClutch : 19|1@1+ (1,0) [0|0] "" Vector__XXX
 SG_ DIF_limitphaseOutBusbarTemp : 20|1@1+ (1,0) [0|0] "" Vector__XXX
 SG_ DIF_limitphaseOutBusBarWeldTemp : 21|1@1+ (1,0) [0|0] "" Vector__XXX
 SG_ DIF_limitphaseOutLugTemp : 22|1@1+ (1,0) [0|0] "" Vector__XXX
 SG_ DIF_limitdcLinkCapTemp : 23|1@1+ (1,0) [0|0] "" Vector__XXX
 SG_ DIF_limitnegDcBusbarTemp : 24|1@1+ (1,0) [0|0] "" Vector__XXX
 SG_ DIF_limitposDcBusbarTemp : 25|1@1+ (1,0) [0|0] "" Vector__XXX
 SG_ DIF_limitRotorTemp : 26|1@1+ (1,0) [0|0] "" Vector__XXX
 SG_ DIF_limithvDcCableTemp : 27|1@1+ (1,0) [0|0] "" Vector__XXX
 SG_ DIF_limitUnitSpinDownLearning : 28|1@1+ (1,0) [0|0] "" Vector__XXX
 SG_ DIF_limitStatorHousingTemp : 29|1@1+ (1,0) [0|0] "" Vector__XXX
 SG_ DIF_statorTempFromResist : 30|8@1+ (1,-40) [0|0] "" Vector__XXX
 SG_ DIF_magnetFluxError : 38|8@1- (8e-05,0) [0|0] "" Vector__XXX
 SG_ DIF_currentLimit : 46|16@1+ (0.1,0) [0|0] "" Vector__XXX
 SG_ DIF_pstgDisableHW3PS : 62|1@1+ (1,0) [0|0] "" Vector__XXX
 SG_ DIF_pstgDisableSW3PS : 63|1@1+ (1,0) [0|0] "" Vector__XXX

BO_ 409 TAS_uiAdaptiveActivity0: 8 Vector__XXX
 SG_ TAS_adaptiveActivityFL_C : 0|5@1+ (0.04,0) [0|0] "" Vector__XXX
 SG_ TAS_adaptiveActivityFL_R : 5|5@1+ (0.04,0) [0|0] "" Vector__XXX
 SG_ TAS_adaptiveActivityFR_C : 10|5@1+ (0.04,0) [0|0] "" Vector__XXX
 SG_ TAS_adaptiveActivityFR_R : 15|5@1+ (0.04,0) [0|0] "" Vector__XXX
 SG_ TAS_adaptiveActivityRL_C : 20|5@1+ (0.04,0) [0|0] "" Vector__XXX
 SG_ TAS_adaptiveActivityRL_R : 25|5@1+ (0.04,0) [0|0] "" Vector__XXX
 SG_ TAS_adaptiveActivityRR_C : 30|5@1+ (0.04,0) [0|0] "" Vector__XXX
 SG_ TAS_adaptiveActivityRR_R : 35|5@1+ (0.04,0) [0|0] "" Vector__XXX
 SG_ TAS_uiHeightFL : 40|6@1+ (4,-128) [0|0] "" Vector__XXX
 SG_ TAS_uiHeightFR : 46|6@1+ (4,-128) [0|0] "" Vector__XXX
 SG_ TAS_uiHeightRL : 52|6@1+ (4,-128) [0|0] "" Vector__XXX
 SG_ TAS_uiHeightRR : 58|6@1+ (4,-128) [0|0] "" Vector__XXX

BO_ 410 TAS_uiAdaptiveActivity1: 8 Vector__XXX
 SG_ TAS_bodyAccelFL : 0|8@1+ (0.05,-5) [0|0] "" Vector__XXX
 SG_ TAS_bodyAccelFR : 8|8@1+ (0.05,-5) [0|0] "" Vector__XXX
 SG_ TAS_bodyAccelRL : 16|8@1+ (0.05,-5) [0|0] "" Vector__XXX
 SG_ TAS_bodyAccelRR : 24|8@1+ (0.05,-5) [0|0] "" Vector__XXX

BO_ 421 DIF_motorStatus: 8 Vector__XXX
 SG_ DIF_motorCurrent : 0|11@1+ (1,0) [0|0] "" Vector__XXX
 SG_ DIF_switchingFrequency : 11|11@1+ (0.01,0) [0|0] "" Vector__XXX
 SG_ DIF_targetFluxMode : 22|2@1+ (1,0) [0|0] "" Vector__XXX
 SG_ DIF_switchShortTestRetryCount : 24|2@1+ (1,0) [0|0] "" Vector__XXX
 SG_ DIF_keepAliveRequest : 26|1@1+ (1,0) [0|0] "" Vector__XXX
 SG_ DIF_motorStatusCounter : 27|4@1+ (1,0) [0|0] "" Vector__XXX
 SG_ DIF_motorStatusChecksum : 32|8@1+ (1,0) [0|0] "" Vector__XXX

BO_ 443 UI_peripheralPowerRequests: 8 Vector__XXX
 SG_ UI_usbFrontHubPowerStateRequest : 0|2@1+ (1,0) [0|0] "" Vector__XXX

BO_ 455 TASDBG_currentsDamper: 8 Vector__XXX
 SG_ TASDBG_current_FL_C : 0|8@1+ (0.0075,0) [0|0] "" Vector__XXX
 SG_ TASDBG_current_FL_R : 8|8@1+ (0.0075,0) [0|0] "" Vector__XXX
 SG_ TASDBG_current_FR_C : 16|8@1+ (0.0075,0) [0|0] "" Vector__XXX
 SG_ TASDBG_current_FR_R : 24|8@1+ (0.0075,0) [0|0] "" Vector__XXX
 SG_ TASDBG_current_RL_C : 32|8@1+ (0.0075,0) [0|0] "" Vector__XXX
 SG_ TASDBG_current_RL_R : 40|8@1+ (0.0075,0) [0|0] "" Vector__XXX
 SG_ TASDBG_current_RR_C : 48|8@1+ (0.0075,0) [0|0] "" Vector__XXX
 SG_ TASDBG_current_RR_R : 56|8@1+ (0.0075,0) [0|0] "" Vector__XXX

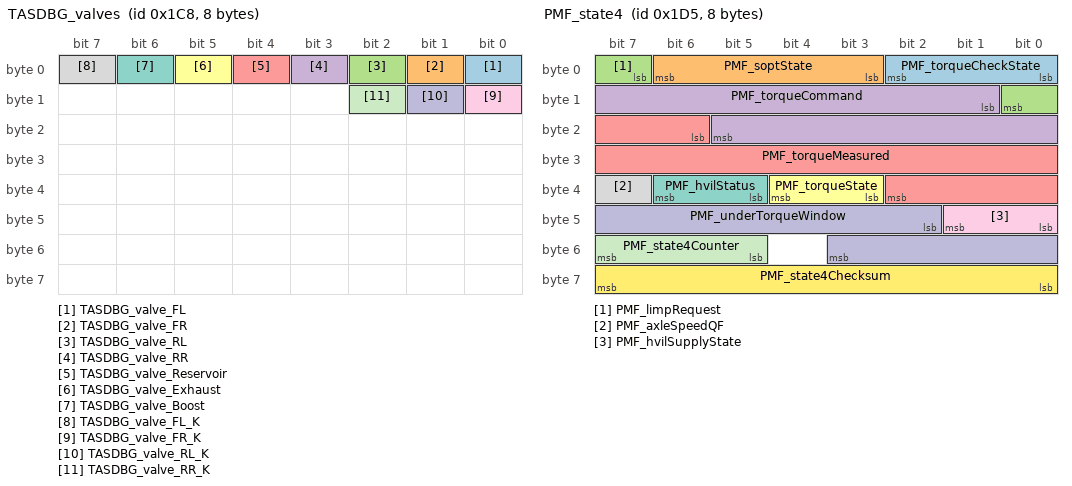
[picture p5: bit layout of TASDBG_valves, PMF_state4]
BO_ 456 TASDBG_valves: 8 Vector__XXX
 SG_ TASDBG_valve_FL : 0|1@1+ (1,0) [0|0] "" Vector__XXX
 SG_ TASDBG_valve_FR : 1|1@1+ (1,0) [0|0] "" Vector__XXX
 SG_ TASDBG_valve_RL : 2|1@1+ (1,0) [0|0] "" Vector__XXX
 SG_ TASDBG_valve_RR : 3|1@1+ (1,0) [0|0] "" Vector__XXX
 SG_ TASDBG_valve_Reservoir : 4|1@1+ (1,0) [0|0] "" Vector__XXX
 SG_ TASDBG_valve_Exhaust : 5|1@1+ (1,0) [0|0] "" Vector__XXX
 SG_ TASDBG_valve_Boost : 6|1@1+ (1,0) [0|0] "" Vector__XXX
 SG_ TASDBG_valve_FL_K : 7|1@1+ (1,0) [0|0] "" Vector__XXX
 SG_ TASDBG_valve_FR_K : 8|1@1+ (1,0) [0|0] "" Vector__XXX
 SG_ TASDBG_valve_RL_K : 9|1@1+ (1,0) [0|0] "" Vector__XXX
 SG_ TASDBG_valve_RR_K : 10|1@1+ (1,0) [0|0] "" Vector__XXX

BO_ 469 PMF_state4: 8 Vector__XXX
 SG_ PMF_torqueCheckState : 0|3@1+ (1,0) [0|0] "" Vector__XXX
 SG_ PMF_soptState : 3|4@1+ (1,0) [0|0] "" Vector__XXX
 SG_ PMF_limpRequest : 7|2@1+ (1,0) [0|0] "" Vector__XXX
 SG_ PMF_torqueCommand : 9|13@1- (2,0) [0|0] "" Vector__XXX
 SG_ PMF_torqueMeasured : 22|13@1- (2,0) [0|0] "" Vector__XXX
 SG_ PMF_torqueState : 35|2@1+ (1,0) [0|0] "" Vector__XXX
 SG_ PMF_hvilStatus : 37|2@1+ (1,0) [0|0] "" Vector__XXX
 SG_ PMF_axleSpeedQF : 39|1@1+ (1,0) [0|0] "" Vector__XXX
 SG_ PMF_hvilSupplyState : 40|2@1+ (1,0) [0|0] "" Vector__XXX
 SG_ PMF_underTorqueWindow : 42|10@1+ (0.005,0) [0|0] "" Vector__XXX
 SG_ PMF_state4Counter : 53|3@1+ (1,0) [0|0] "" Vector__XXX
 SG_ PMF_state4Checksum : 56|8@1+ (1,0) [0|0] "" Vector__XXX

BO_ 470 DIR_limits: 8 Vector__XXX
 SG_ DIR_limitPCBTemp : 0|1@1+ (1,0) [0|0] "" Vector__XXX
 SG_ DIR_limitInverterTemp : 1|1@1+ (1,0) [0|0] "" Vector__XXX
 SG_ DIR_limitStatorTemp : 2|1@1+ (1,0) [0|0] "" Vector__XXX
 SG_ DIR_limitPoleTemp : 3|1@1+ (1,0) [0|0] "" Vector__XXX
 SG_ DIR_limitUnitLimp : 4|1@1+ (1,0) [0|0] "" Vector__XXX
 SG_ DIR_limitDeltaFluidTemp : 5|1@1+ (1,0) [0|0] "" Vector__XXX
 SG_ DIR_limitDischargePower : 6|1@1+ (1,0) [0|0] "" Vector__XXX
 SG_ DIR_limitMotorCurrent : 7|1@1+ (1,0) [0|0] "" Vector__XXX
 SG_ DIR_limitMotorVoltage : 8|1@1+ (1,0) [0|0] "" Vector__XXX
 SG_ DIR_limitTCDrive : 9|1@1+ (1,0) [0|0] "" Vector__XXX
 SG_ DIR_limitTCRegen : 10|1@1+ (1,0) [0|0] "" Vector__XXX
 SG_ DIR_limitBaseSpeed : 11|1@1+ (1,0) [0|0] "" Vector__XXX
 SG_ DIR_limitDcCapTemp : 12|1@1+ (1,0) [0|0] "" Vector__XXX
 SG_ DIR_limitMotorSpeed : 13|1@1+ (1,0) [0|0] "" Vector__XXX
 SG_ DIR_limitDiff : 14|1@1+ (1,0) [0|0] "" Vector__XXX
 SG_ DIR_limitUnitGPO : 15|1@1+ (1,0) [0|0] "" Vector__XXX
 SG_ DIR_limitShockTorque : 16|1@1+ (1,0) [0|0] "" Vector__XXX
 SG_ DIR_limitOilPumpFluidTemp : 17|1@1+ (1,0) [0|0] "" Vector__XXX
 SG_ DIR_limitStatorFrequency : 18|1@1+ (1,0) [0|0] "" Vector__XXX
 SG_ DIR_limitClutch : 19|1@1+ (1,0) [0|0] "" Vector__XXX
 SG_ DIR_limitphaseOutBusbarTemp : 20|1@1+ (1,0) [0|0] "" Vector__XXX
 SG_ DIR_limitphaseOutBusBarWeldTemp : 21|1@1+ (1,0) [0|0] "" Vector__XXX
 SG_ DIR_limitphaseOutLugTemp : 22|1@1+ (1,0) [0|0] "" Vector__XXX
 SG_ DIR_limitdcLinkCapTemp : 23|1@1+ (1,0) [0|0] "" Vector__XXX
 SG_ DIR_limitnegDcBusbarTemp : 24|1@1+ (1,0) [0|0] "" Vector__XXX
 SG_ DIR_limitposDcBusbarTemp : 25|1@1+ (1,0) [0|0] "" Vector__XXX
 SG_ DIR_limitRotorTemp : 26|1@1+ (1,0) [0|0] "" Vector__XXX
 SG_ DIR_limithvDcCableTemp : 27|1@1+ (1,0) [0|0] "" Vector__XXX
 SG_ DIR_limitUnitSpinDownLearning : 28|1@1+ (1,0) [0|0] "" Vector__XXX
 SG_ DIR_limitStatorHousingTemp : 29|1@1+ (1,0) [0|0] "" Vector__XXX
 SG_ DIR_statorTempFromResist : 30|8@1+ (1,-40) [0|0] "" Vector__XXX
 SG_ DIR_magnetFluxError : 38|8@1- (8e-05,0) [0|0] "" Vector__XXX
 SG_ DIR_currentLimit : 46|16@1+ (0.1,0) [0|0] "" Vector__XXX
 SG_ DIR_pstgDisableHW3PS : 62|1@1+ (1,0) [0|0] "" Vector__XXX
 SG_ DIR_pstgDisableSW3PS : 63|1@1+ (1,0) [0|0] "" Vector__XXX

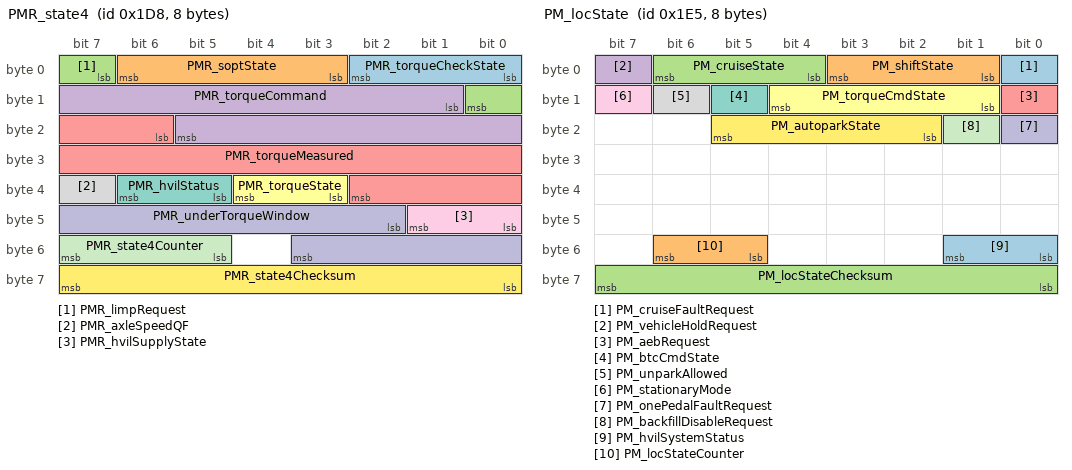
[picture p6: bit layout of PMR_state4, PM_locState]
BO_ 472 PMR_state4: 8 Vector__XXX
 SG_ PMR_torqueCheckState : 0|3@1+ (1,0) [0|0] "" Vector__XXX
 SG_ PMR_soptState : 3|4@1+ (1,0) [0|0] "" Vector__XXX
 SG_ PMR_limpRequest : 7|2@1+ (1,0) [0|0] "" Vector__XXX
 SG_ PMR_torqueCommand : 9|13@1- (2,0) [0|0] "" Vector__XXX
 SG_ PMR_torqueMeasured : 22|13@1- (2,0) [0|0] "" Vector__XXX
 SG_ PMR_torqueState : 35|2@1+ (1,0) [0|0] "" Vector__XXX
 SG_ PMR_hvilStatus : 37|2@1+ (1,0) [0|0] "" Vector__XXX
 SG_ PMR_axleSpeedQF : 39|1@1+ (1,0) [0|0] "" Vector__XXX
 SG_ PMR_hvilSupplyState : 40|2@1+ (1,0) [0|0] "" Vector__XXX
 SG_ PMR_underTorqueWindow : 42|10@1+ (0.005,0) [0|0] "" Vector__XXX
 SG_ PMR_state4Counter : 53|3@1+ (1,0) [0|0] "" Vector__XXX
 SG_ PMR_state4Checksum : 56|8@1+ (1,0) [0|0] "" Vector__XXX

BO_ 473 VCSEC_IsoTpUDPPipeUI: 8 Vector__XXX
 SG_ VCSEC_IsoTpUDPPipeUI0 : 0|8@1+ (1,0) [0|0] "" Vector__XXX
 SG_ VCSEC_IsoTpUDPPipeUI1 : 8|8@1+ (1,0) [0|0] "" Vector__XXX
 SG_ VCSEC_IsoTpUDPPipeUI2 : 16|8@1+ (1,0) [0|0] "" Vector__XXX
 SG_ VCSEC_IsoTpUDPPipeUI3 : 24|8@1+ (1,0) [0|0] "" Vector__XXX
 SG_ VCSEC_IsoTpUDPPipeUI4 : 32|8@1+ (1,0) [0|0] "" Vector__XXX
 SG_ VCSEC_IsoTpUDPPipeUI5 : 40|8@1+ (1,0) [0|0] "" Vector__XXX
 SG_ VCSEC_IsoTpUDPPipeUI6 : 48|8@1+ (1,0) [0|0] "" Vector__XXX
 SG_ VCSEC_IsoTpUDPPipeUI7 : 56|8@1+ (1,0) [0|0] "" Vector__XXX

BO_ 474 VCSEC_IsoTpPipeRemoteUI: 8 Vector__XXX
 SG_ VCSEC_IsoTpRemoteUI0 : 0|8@1+ (1,0) [0|0] "" Vector__XXX
 SG_ VCSEC_IsoTpRemoteUI1 : 8|8@1+ (1,0) [0|0] "" Vector__XXX
 SG_ VCSEC_IsoTpRemoteUI2 : 16|8@1+ (1,0) [0|0] "" Vector__XXX
 SG_ VCSEC_IsoTpRemoteUI3 : 24|8@1+ (1,0) [0|0] "" Vector__XXX
 SG_ VCSEC_IsoTpRemoteUI4 : 32|8@1+ (1,0) [0|0] "" Vector__XXX
 SG_ VCSEC_IsoTpRemoteUI5 : 40|8@1+ (1,0) [0|0] "" Vector__XXX
 SG_ VCSEC_IsoTpRemoteUI6 : 48|8@1+ (1,0) [0|0] "" Vector__XXX
 SG_ VCSEC_IsoTpRemoteUI7 : 56|8@1+ (1,0) [0|0] "" Vector__XXX

BO_ 485 PM_locState: 8 Vector__XXX
 SG_ PM_cruiseFaultRequest : 0|1@1+ (1,0) [0|0] "" Vector__XXX
 SG_ PM_shiftState : 1|3@1+ (1,0) [0|0] "" Vector__XXX
 SG_ PM_cruiseState : 4|3@1+ (1,0) [0|0] "" Vector__XXX
 SG_ PM_vehicleHoldRequest : 7|1@1+ (1,0) [0|0] "" Vector__XXX
 SG_ PM_aebRequest : 8|1@1+ (1,0) [0|0] "" Vector__XXX
 SG_ PM_torqueCmdState : 9|4@1+ (1,0) [0|0] "" Vector__XXX
 SG_ PM_btcCmdState : 13|1@1+ (1,0) [0|0] "" Vector__XXX
 SG_ PM_unparkAllowed : 14|1@1+ (1,0) [0|0] "" Vector__XXX
 SG_ PM_stationaryMode : 15|1@1+ (1,0) [0|0] "" Vector__XXX
 SG_ PM_onePedalFaultRequest : 16|1@1+ (1,0) [0|0] "" Vector__XXX
 SG_ PM_backfillDisableRequest : 17|1@1+ (1,0) [0|0] "" Vector__XXX
 SG_ PM_autoparkState : 18|4@1+ (1,0) [0|0] "" Vector__XXX
 SG_ PM_hvilSystemStatus : 48|2@1+ (1,0) [0|0] "" Vector__XXX
 SG_ PM_locStateCounter : 53|2@1+ (1,0) [0|0] "" Vector__XXX
 SG_ PM_locStateChecksum : 56|8@1+ (1,0) [0|0] "" Vector__XXX

BO_ 504 VCLEFT_intrusionSensorStatus: 8 Vector__XXX
 SG_ VCLEFT_DBG_System_Status : 0|3@1+ (1,0) [0|0] "" Vector__XXX
 SG_ VCLEFT_DBG_Air_Cond_Status : 3|1@1+ (1,0) [0|0] "" Vector__XXX
 SG_ VCLEFT_DBG_Heater_Status : 4|1@1+ (1,0) [0|0] "" Vector__XXX
 SG_ VCLEFT_DBG_Window_Status : 5|1@1+ (1,0) [0|0] "" Vector__XXX
 SG_ VCLEFT_DBG_Suspensions_Status : 6|1@1+ (1,0) [0|0] "" Vector__XXX
 SG_ VCLEFT_DBG_SelfTest_Status : 7|1@1+ (1,0) [0|0] "" Vector__XXX
 SG_ VCLEFT_DBG_Veh_Settings_Status : 8|4@1+ (1,0) [0|0] "" Vector__XXX
 SG_ VCLEFT_DBG_USS_Alarm_Status : 12|1@1+ (1,0) [0|0] "" Vector__XXX
 SG_ VCLEFT_DBG_LM_Alarm_Status : 13|1@1+ (1,0) [0|0] "" Vector__XXX
 SG_ VCLEFT_DBG_Siren_ST_Status : 14|1@1+ (1,0) [0|0] "" Vector__XXX
 SG_ VCLEFT_DBG_Siren_Int_Trigger : 15|1@1+ (1,0) [0|0] "" Vector__XXX
 SG_ VCLEFT_DBG_Invalid_Parameter : 16|1@1+ (1,0) [0|0] "" Vector__XXX
 SG_ VCLEFT_DBG_Siren_is_sounding : 17|1@1+ (1,0) [0|0] "" Vector__XXX
 SG_ VCLEFT_DBG_Reserved_07 : 18|1@1+ (1,0) [0|0] "" Vector__XXX
 SG_ VCLEFT_DBG_Reserved_08 : 19|1@1+ (1,0) [0|0] "" Vector__XXX
 SG_ VCLEFT_DBG_Eeprom_ST_Status : 20|1@1+ (1,0) [0|0] "" Vector__XXX
 SG_ VCLEFT_DBG_USS_SelfTest_Status : 21|1@1+ (1,0) [0|0] "" Vector__XXX
 SG_ VCLEFT_DBG_LM_SelfTest_Status : 22|1@1+ (1,0) [0|0] "" Vector__XXX
 SG_ VCLEFT_DBG_System_Error : 23|1@1+ (1,0) [0|0] "" Vector__XXX
 SG_ VCLEFT_sirenMIA : 24|1@1+ (1,0) [0|0] "" Vector__XXX
 SG_ VCLEFT_intrusionTiltTripped : 25|1@1+ (1,0) [0|0] "" Vector__XXX
 SG_ VCLEFT_intrusionUltraTripped : 26|1@1+ (1,0) [0|0] "" Vector__XXX

BO_ 505 VCSEC_requests: 8 Vector__XXX
 SG_ VCSEC_chargePortRequest : 0|2@1+ (1,0) [0|0] "" Vector__XXX
 SG_ VCSEC_presentHandles : 4|1@1+ (1,0) [0|0] "" Vector__XXX
 SG_ VCSEC_frontLeftClosureRequest : 5|3@1+ (1,0) [0|0] "" Vector__XXX
 SG_ VCSEC_frontRightClosureRequest : 8|3@1+ (1,0) [0|0] "" Vector__XXX
 SG_ VCSEC_rearLeftClosureRequest : 11|3@1+ (1,0) [0|0] "" Vector__XXX
 SG_ VCSEC_rearRightClosureRequest : 14|3@1+ (1,0) [0|0] "" Vector__XXX
 SG_ VCSEC_rearTrunkClosureRequest : 17|3@1+ (1,0) [0|0] "" Vector__XXX
 SG_ VCSEC_frontLeftRequestReason : 20|3@1+ (1,0) [0|0] "" Vector__XXX
 SG_ VCSEC_frontRightRequestReason : 23|3@1+ (1,0) [0|0] "" Vector__XXX
 SG_ VCSEC_rearLeftRequestReason : 26|3@1+ (1,0) [0|0] "" Vector__XXX
 SG_ VCSEC_rearRightRequestReason : 29|3@1+ (1,0) [0|0] "" Vector__XXX
 SG_ VCSEC_rearTrunkRequestReason : 32|3@1+ (1,0) [0|0] "" Vector__XXX
 SG_ VCSEC_rdMapDumpRequested : 35|1@1+ (1,0) [0|0] "" Vector__XXX
 SG_ VCSEC_driveAttemptedWithoutAuth : 36|4@1+ (1,0) [0|0] "" Vector__XXX
 SG_ VCSEC_closeAllStatus : 41|2@1+ (1,0) [0|0] "" Vector__XXX
 SG_ VCSEC_snapshotRequested : 43|4@1+ (1,0) [0|0] "" Vector__XXX
 SG_ VCSEC_chargeportRequestReason : 47|3@1+ (1,0) [0|0] "" Vector__XXX
 SG_ VCSEC_frontTrunkClosureRequest : 51|3@1+ (1,0) [0|0] "" Vector__XXX
 SG_ VCSEC_frontTrunkRequestReason : 54|3@1+ (1,0) [0|0] "" Vector__XXX

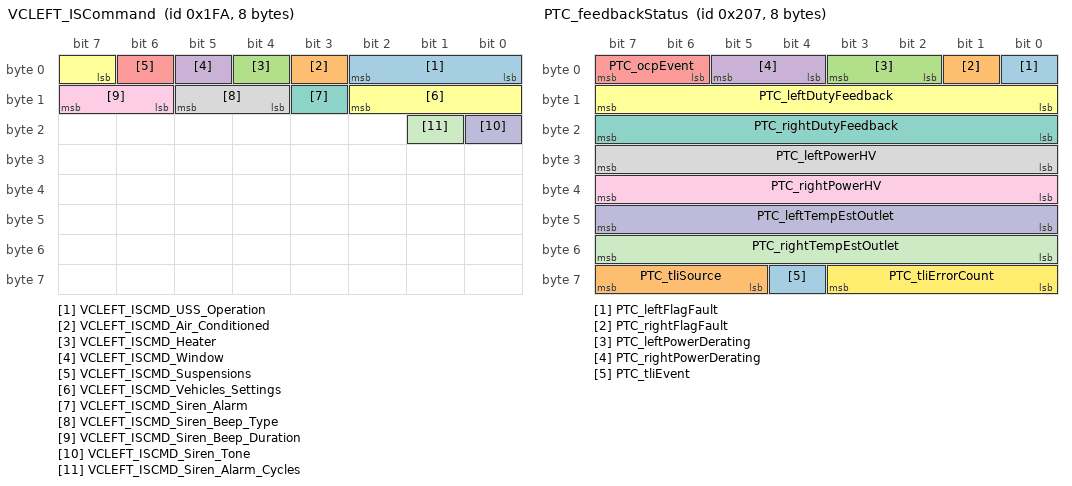
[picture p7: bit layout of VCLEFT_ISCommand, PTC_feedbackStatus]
BO_ 506 VCLEFT_ISCommand: 8 Vector__XXX
 SG_ VCLEFT_ISCMD_USS_Operation : 0|3@1+ (1,0) [0|0] "" Vector__XXX
 SG_ VCLEFT_ISCMD_Air_Conditioned : 3|1@1+ (1,0) [0|0] "" Vector__XXX
 SG_ VCLEFT_ISCMD_Heater : 4|1@1+ (1,0) [0|0] "" Vector__XXX
 SG_ VCLEFT_ISCMD_Window : 5|1@1+ (1,0) [0|0] "" Vector__XXX
 SG_ VCLEFT_ISCMD_Suspensions : 6|1@1+ (1,0) [0|0] "" Vector__XXX
 SG_ VCLEFT_ISCMD_Vehicles_Settings : 7|4@1+ (1,0) [0|0] "" Vector__XXX
 SG_ VCLEFT_ISCMD_Siren_Alarm : 11|1@1+ (1,0) [0|0] "" Vector__XXX
 SG_ VCLEFT_ISCMD_Siren_Beep_Type : 12|2@1+ (1,0) [0|0] "" Vector__XXX
 SG_ VCLEFT_ISCMD_Siren_Beep_Duration : 14|2@1+ (1,0) [0|0] "" Vector__XXX
 SG_ VCLEFT_ISCMD_Siren_Tone : 16|1@1+ (1,0) [0|0] "" Vector__XXX
 SG_ VCLEFT_ISCMD_Siren_Alarm_Cycles : 17|1@1+ (1,0) [0|0] "" Vector__XXX

BO_ 507 VCLEFT_TLCStatus: 8 Vector__XXX
 SG_ VCLEFT_TLCStatusIndex M : 0|2@1+ (1,0) [0|0] "" Vector__XXX
 SG_ VCLEFT_TLCTemperature m1 : 2|8@1- (1,68) [0|0] "" Vector__XXX
 SG_ VCLEFT_TLCLeftTurnCurrent m0 : 8|8@1+ (0.1,0) [0|0] "" Vector__XXX
 SG_ VCLEFT_TLCLeftTurnVoltage m1 : 10|8@1+ (0.1,0) [0|0] "" Vector__XXX
 SG_ VCLEFT_TLCRightTurnCurrent m0 : 16|8@1+ (0.1,0) [0|0] "" Vector__XXX
 SG_ VCLEFT_TLCRightTurnVoltage m1 : 18|8@1+ (0.1,0) [0|0] "" Vector__XXX
 SG_ VCLEFT_TLCTailCurrent m0 : 24|8@1+ (0.1,0) [0|0] "" Vector__XXX
 SG_ VCLEFT_TLCState_LeftTurn m1 : 26|3@1+ (1,0) [0|0] "" Vector__XXX
 SG_ VCLEFT_TLCState_RightTurn m1 : 29|3@1+ (1,0) [0|0] "" Vector__XXX
 SG_ VCLEFT_TLCState_Tail m1 : 32|3@1+ (1,0) [0|0] "" Vector__XXX
 SG_ VCLEFT_TLCStopCurrent m0 : 32|8@1+ (0.1,0) [0|0] "" Vector__XXX
 SG_ VCLEFT_TLCState_Stop m1 : 35|3@1+ (1,0) [0|0] "" Vector__XXX
 SG_ VCLEFT_TLCState_Fog m1 : 38|3@1+ (1,0) [0|0] "" Vector__XXX
 SG_ VCLEFT_TLCFogCurrent m0 : 40|8@1+ (0.1,0) [0|0] "" Vector__XXX
 SG_ VCLEFT_TLCState_Reverse m1 : 41|3@1+ (1,0) [0|0] "" Vector__XXX
 SG_ VCLEFT_TLCReverseCurrent m0 : 48|8@1+ (0.1,0) [0|0] "" Vector__XXX
 SG_ VCLEFT_TLCTotalCurrent m0 : 56|8@1+ (0.1,0) [0|0] "" Vector__XXX

BO_ 508 APP_roadDisturbance: 8 Vector__XXX
 SG_ APP_roadDisturbanceIndex : 0|2@1+ (1,0) [0|0] "" Vector__XXX
 SG_ APP_roadDisturbanceHeight : 2|6@1+ (0.02,-0.64) [0|0] "" Vector__XXX
 SG_ APP_roadDisturbanceX0 : 8|8@1+ (0.5,0) [0|0] "" Vector__XXX
 SG_ APP_roadDisturbanceX1 : 16|8@1+ (0.5,0) [0|0] "" Vector__XXX
 SG_ APP_roadDisturbanceY0 : 24|8@1+ (0.1,-12.8) [0|0] "" Vector__XXX
 SG_ APP_roadDisturbanceY1 : 32|8@1+ (0.1,-12.8) [0|0] "" Vector__XXX
 SG_ APP_suspensionLevelRequest : 40|4@1+ (1,0) [0|0] "" Vector__XXX

BO_ 513 VCFRONT_loggingAndVitals10Hz: 8 Vector__XXX
 SG_ VCFRONT_loggingAndVitals10HzIndex M : 0|3@1+ (1,0) [0|0] "" Vector__XXX
 SG_ VCFRONT_chillerExvFlow m2 : 3|8@1+ (0.5,0) [0|0] "" Vector__XXX
 SG_ VCFRONT_chillerExvFlowTarget m3 : 3|8@1+ (0.5,0) [0|0] "" Vector__XXX
 SG_ VCFRONT_fanDemand m1 : 3|7@1+ (1,0) [0|0] "" Vector__XXX
 SG_ VCFRONT_pumpBatteryRPMActual m0 : 8|8@1+ (30,0) [0|0] "" Vector__XXX
 SG_ VCFRONT_compressorState m1 : 10|2@1+ (1,0) [0|0] "" Vector__XXX
 SG_ VCFRONT_evapExvFlow m2 : 11|8@1+ (0.5,0) [0|0] "" Vector__XXX
 SG_ VCFRONT_evapExvFlowTarget m3 : 11|8@1+ (0.5,0) [0|0] "" Vector__XXX
 SG_ VCFRONT_compDemandEvap m1 : 12|7@1+ (1,0) [0|0] "" Vector__XXX
 SG_ VCFRONT_pumpPowertrainRPMActual m0 : 16|8@1+ (30,0) [0|0] "" Vector__XXX
 SG_ VCFRONT_exvState m1 : 19|4@1+ (1,0) [0|0] "" Vector__XXX
 SG_ VCFRONT_recircExvFlow m2 : 19|8@1+ (0.5,0) [0|0] "" Vector__XXX
 SG_ VCFRONT_recircExvFlowTarget m3 : 19|8@1+ (0.5,0) [0|0] "" Vector__XXX
 SG_ VCFRONT_solenoidEvapState m1 : 23|2@1+ (1,0) [0|0] "" Vector__XXX
 SG_ VCFRONT_radiatorFanRPMActual m0 : 24|8@1+ (40,0) [0|0] "" Vector__XXX
 SG_ VCFRONT_compDemandChiller m1 : 25|7@1+ (1,0) [0|0] "" Vector__XXX
 SG_ VCFRONT_lccExvFlow m2 : 27|8@1+ (0.5,0) [0|0] "" Vector__XXX
 SG_ VCFRONT_lccExvFlowTarget m3 : 27|8@1+ (0.5,0) [0|0] "" Vector__XXX
 SG_ VCFRONT_coolantValveMode m1 : 32|2@1+ (1,0) [0|0] "" Vector__XXX
 SG_ VCFRONT_exvFlowTarget m0 : 32|8@1+ (0.5,0) [0|0] "" Vector__XXX
 SG_ VCFRONT_compFaultSeverity m1 : 34|2@1+ (1,0) [0|0] "" Vector__XXX
 SG_ VCFRONT_cclExvFlow m2 : 35|8@1+ (0.5,0) [0|0] "" Vector__XXX
 SG_ VCFRONT_cclExvFlowTarget m3 : 35|8@1+ (0.5,0) [0|0] "" Vector__XXX
 SG_ VCFRONT_solenoidEngaged m1 : 36|1@1+ (1,0) [0|0] "" Vector__XXX
 SG_ VCFRONT_hpHighSideHX m1 : 37|2@1+ (1,0) [0|0] "" Vector__XXX
 SG_ VCFRONT_hpLowSideHX m1 : 39|2@1+ (1,0) [0|0] "" Vector__XXX
 SG_ VCFRONT_activeLouverOpenPosTarg m0 : 40|7@1+ (1,0) [0|0] "" Vector__XXX
 SG_ VCFRONT_hpDominantLoad m1 : 41|3@1+ (1,0) [0|0] "" Vector__XXX
 SG_ VCFRONT_ccrExvFlow m2 : 43|8@1+ (0.5,0) [0|0] "" Vector__XXX
 SG_ VCFRONT_ccrExvFlowTarget m3 : 43|8@1+ (0.5,0) [0|0] "" Vector__XXX
 SG_ VCFRONT_hpBlendType m1 : 44|2@1+ (1,0) [0|0] "" Vector__XXX
 SG_ VCFRONT_hpQuietModeEnabled m1 : 46|1@1+ (1,0) [0|0] "" Vector__XXX
 SG_ VCFRONT_hpCabinLoadType m1 : 47|2@1+ (1,0) [0|0] "" Vector__XXX
 SG_ VCFRONT_pressureRefrigLiquid m0 : 47|9@1+ (0.08,0) [0|0] "" Vector__XXX
 SG_ VCFRONT_hpBatteryLoadType m1 : 49|2@1+ (1,0) [0|0] "" Vector__XXX
 SG_ VCFRONT_chillerExvState m2 : 51|4@1+ (1,0) [0|0] "" Vector__XXX
 SG_ VCFRONT_hpReqCoolantMode m1 : 51|3@1+ (1,0) [0|0] "" Vector__XXX
 SG_ VCFRONT_lccExvState m3 : 51|4@1+ (1,0) [0|0] "" Vector__XXX
 SG_ VCFRONT_hpReqTransScavenge m1 : 54|1@1+ (1,0) [0|0] "" Vector__XXX
 SG_ VCFRONT_cclExvState m3 : 55|4@1+ (1,0) [0|0] "" Vector__XXX
 SG_ VCFRONT_compLiqPumpOutState m1 : 55|3@1+ (1,0) [0|0] "" Vector__XXX
 SG_ VCFRONT_evapExvState m2 : 55|4@1+ (1,0) [0|0] "" Vector__XXX
 SG_ VCFRONT_compSleepRequest m0 : 56|1@1+ (1,0) [0|0] "" Vector__XXX
 SG_ VCFRONT_thermalHvPowerBudget m0 : 57|7@1+ (0.2,0) [0|0] "" Vector__XXX
 SG_ VCFRONT_frunkStateDBG m1 : 58|4@1+ (1,0) [0|0] "" Vector__XXX
 SG_ VCFRONT_ccrExvState m3 : 59|4@1+ (1,0) [0|0] "" Vector__XXX
 SG_ VCFRONT_recircExvState m2 : 59|4@1+ (1,0) [0|0] "" Vector__XXX
 SG_ VCFRONT_frunkSwitchGroupState m1 : 62|2@1+ (1,0) [0|0] "" Vector__XXX

BO_ 516 PCS_chgStatus: 8 Vector__XXX
 SG_ PCS_chgMainState : 0|4@1+ (1,0) [0|0] "" Vector__XXX
 SG_ PCS_powerTransferStatus : 4|2@1+ (1,0) [0|0] "" Vector__XXX
 SG_ PCS_gridConfig : 6|2@1+ (1,0) [0|0] "" Vector__XXX
 SG_ PCS_chgPHAEnable : 8|1@1+ (1,0) [0|0] "" Vector__XXX
 SG_ PCS_chgPHBEnable : 9|1@1+ (1,0) [0|0] "" Vector__XXX
 SG_ PCS_hvInletConductorEnergizedAc : 10|1@1+ (1,0) [0|0] "" Vector__XXX
 SG_ PCS_chgHighPowerActive : 11|1@1+ (1,0) [0|0] "" Vector__XXX
 SG_ PCS_chgPHCEnable : 12|1@1+ (1,0) [0|0] "" Vector__XXX
 SG_ PCS_chgInstantAcPowerAvailable : 16|8@1+ (0.1,0) [0|0] "" Vector__XXX
 SG_ PCS_chgMaxAcPowerAvailable : 24|8@1+ (0.1,0) [0|0] "" Vector__XXX
 SG_ PCS_chgPHALineCurrentRequest : 32|8@1+ (0.1,0) [0|0] "" Vector__XXX
 SG_ PCS_chgPHBLineCurrentRequest : 40|8@1+ (0.1,0) [0|0] "" Vector__XXX
 SG_ PCS_chgPHCLineCurrentRequest : 48|8@1+ (0.1,0) [0|0] "" Vector__XXX
 SG_ PCS_chgPwmEnableLine : 56|1@1+ (1,0) [0|0] "" Vector__XXX
 SG_ PCS_powerTransferShutdownRequest : 57|2@1+ (1,0) [0|0] "" Vector__XXX
 SG_ PCS_hwVariantType : 59|2@1+ (1,0) [0|0] "" Vector__XXX
 SG_ PCS_dcacBidirectionalAllowed : 61|1@1+ (1,0) [0|0] "" Vector__XXX

BO_ 519 PTC_feedbackStatus: 8 Vector__XXX
 SG_ PTC_leftFlagFault : 0|1@1+ (1,0) [0|0] "" Vector__XXX
 SG_ PTC_rightFlagFault : 1|1@1+ (1,0) [0|0] "" Vector__XXX
 SG_ PTC_leftPowerDerating : 2|2@1+ (1,0) [0|0] "" Vector__XXX
 SG_ PTC_rightPowerDerating : 4|2@1+ (1,0) [0|0] "" Vector__XXX
 SG_ PTC_ocpEvent : 6|2@1+ (1,0) [0|0] "" Vector__XXX
 SG_ PTC_leftDutyFeedback : 8|8@1+ (0.5,0) [0|0] "" Vector__XXX
 SG_ PTC_rightDutyFeedback : 16|8@1+ (0.5,0) [0|0] "" Vector__XXX
 SG_ PTC_leftPowerHV : 24|8@1+ (30,0) [0|0] "" Vector__XXX
 SG_ PTC_rightPowerHV : 32|8@1+ (30,0) [0|0] "" Vector__XXX
 SG_ PTC_leftTempEstOutlet : 40|8@1+ (1,-40) [0|0] "" Vector__XXX
 SG_ PTC_rightTempEstOutlet : 48|8@1+ (1,-40) [0|0] "" Vector__XXX
 SG_ PTC_tliErrorCount : 56|4@1+ (1,0) [0|0] "" Vector__XXX
 SG_ PTC_tliEvent : 60|1@1+ (1,0) [0|0] "" Vector__XXX
 SG_ PTC_tliSource : 61|3@1+ (1,0) [0|0] "" Vector__XXX

BO_ 522 HVP_contactorState: 8 Vector__XXX
 SG_ HVP_packContNegativeState : 0|3@1+ (1,0) [0|0] "" Vector__XXX
 SG_ HVP_packContPositiveState : 3|3@1+ (1,0) [0|0] "" Vector__XXX
 SG_ HVP_fcContPositiveAuxOpen : 6|1@1+ (1,0) [0|0] "" Vector__XXX
 SG_ HVP_fcContNegativeAuxOpen : 7|1@1+ (1,0) [0|0] "" Vector__XXX
 SG_ HVP_packContactorSetState : 8|4@1+ (1,0) [0|0] "" Vector__XXX
 SG_ HVP_fcContNegativeState : 12|3@1+ (1,0) [0|0] "" Vector__XXX
 SG_ HVP_contactorsBlocked : 15|1@1+ (1,0) [0|0] "" Vector__XXX
 SG_ HVP_fcContPositiveState : 16|3@1+ (1,0) [0|0] "" Vector__XXX
 SG_ HVP_fcContactorSetState : 19|4@1+ (1,0) [0|0] "" Vector__XXX
 SG_ HVP_fcCtrsRequestStatus : 24|2@1+ (1,0) [0|0] "" Vector__XXX
 SG_ HVP_fcCtrsResetRequestRequired : 26|1@1+ (1,0) [0|0] "" Vector__XXX
 SG_ HVP_fcCtrsOpenNowRequested : 27|1@1+ (1,0) [0|0] "" Vector__XXX
 SG_ HVP_fcCtrsOpenRequested : 28|1@1+ (1,0) [0|0] "" Vector__XXX
 SG_ HVP_fcCtrsClosingAllowed : 29|1@1+ (1,0) [0|0] "" Vector__XXX
 SG_ HVP_packCtrsRequestStatus : 30|2@1+ (1,0) [0|0] "" Vector__XXX
 SG_ HVP_packCtrsResetRequestRequired : 32|1@1+ (1,0) [0|0] "" Vector__XXX
 SG_ HVP_packCtrsOpenNowRequested : 33|1@1+ (1,0) [0|0] "" Vector__XXX
 SG_ HVP_packCtrsOpenRequested : 34|1@1+ (1,0) [0|0] "" Vector__XXX
 SG_ HVP_packCtrsClosingAllowed : 35|1@1+ (1,0) [0|0] "" Vector__XXX
 SG_ HVP_dcLinkAllowedToEnergize : 36|1@1+ (1,0) [0|0] "" Vector__XXX
 SG_ HVP_pyroTestInProgress : 37|1@1+ (1,0) [0|0] "" Vector__XXX
 SG_ HVP_hvilDiag : 40|4@1+ (1,0) [0|0] "" Vector__XXX
 SG_ HVP_fcLinkAllowedToEnergize : 44|2@1+ (1,0) [0|0] "" Vector__XXX

BO_ 523 TAS_axleData: 8 Vector__XXX
 SG_ TAS_axleIndex M : 0|1@1+ (1,0) [0|0] "" Vector__XXX
 SG_ TAS_rawHeightFL m0 : 4|10@1+ (1,-512) [0|0] "" Vector__XXX
 SG_ TAS_rawHeightRL m1 : 4|10@1+ (1,-512) [0|0] "" Vector__XXX
 SG_ TAS_staticHeightEstimateFL m0 : 14|10@1+ (1,-512) [0|0] "" Vector__XXX
 SG_ TAS_staticHeightEstimateRL m1 : 14|10@1+ (1,-512) [0|0] "" Vector__XXX
 SG_ TAS_componentPressureFL m0 : 24|8@1+ (0.1,0) [0|0] "" Vector__XXX
 SG_ TAS_componentPressureRL m1 : 24|8@1+ (0.1,0) [0|0] "" Vector__XXX
 SG_ TAS_rawHeightFR m0 : 32|10@1+ (1,-512) [0|0] "" Vector__XXX
 SG_ TAS_rawHeightRR m1 : 32|10@1+ (1,-512) [0|0] "" Vector__XXX
 SG_ TAS_staticHeightEstimateFR m0 : 42|10@1+ (1,-512) [0|0] "" Vector__XXX
 SG_ TAS_staticHeightEstimateRR m1 : 42|10@1+ (1,-512) [0|0] "" Vector__XXX
 SG_ TAS_componentPressureFR m0 : 52|8@1+ (0.1,0) [0|0] "" Vector__XXX
 SG_ TAS_componentPressureRR m1 : 52|8@1+ (0.1,0) [0|0] "" Vector__XXX

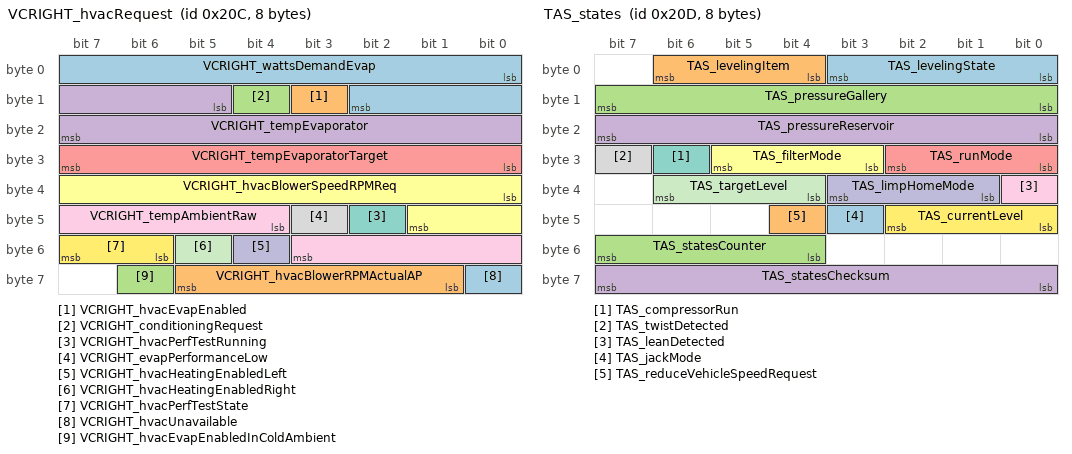
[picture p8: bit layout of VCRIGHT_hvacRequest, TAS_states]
BO_ 524 VCRIGHT_hvacRequest: 8 Vector__XXX
 SG_ VCRIGHT_wattsDemandEvap : 0|11@1+ (5,0) [0|0] "" Vector__XXX
 SG_ VCRIGHT_hvacEvapEnabled : 11|1@1+ (1,0) [0|0] "" Vector__XXX
 SG_ VCRIGHT_conditioningRequest : 12|1@1+ (1,0) [0|0] "" Vector__XXX
 SG_ VCRIGHT_tempEvaporator : 13|11@1+ (0.1,-40) [0|0] "" Vector__XXX
 SG_ VCRIGHT_tempEvaporatorTarget : 24|8@1+ (0.2,0) [0|0] "" Vector__XXX
 SG_ VCRIGHT_hvacBlowerSpeedRPMReq : 32|10@1+ (5,0) [0|0] "" Vector__XXX
 SG_ VCRIGHT_hvacPerfTestRunning : 42|1@1+ (1,0) [0|0] "" Vector__XXX
 SG_ VCRIGHT_evapPerformanceLow : 43|1@1+ (1,0) [0|0] "" Vector__XXX
 SG_ VCRIGHT_tempAmbientRaw : 44|8@1+ (0.5,-40) [0|0] "" Vector__XXX
 SG_ VCRIGHT_hvacHeatingEnabledLeft : 52|1@1+ (1,0) [0|0] "" Vector__XXX
 SG_ VCRIGHT_hvacHeatingEnabledRight : 53|1@1+ (1,0) [0|0] "" Vector__XXX
 SG_ VCRIGHT_hvacPerfTestState : 54|2@1+ (1,0) [0|0] "" Vector__XXX
 SG_ VCRIGHT_hvacUnavailable : 56|1@1+ (1,0) [0|0] "" Vector__XXX
 SG_ VCRIGHT_hvacBlowerRPMActualAP : 57|5@1+ (200,0) [0|0] "" Vector__XXX
 SG_ VCRIGHT_hvacEvapEnabledInColdAmbient : 62|1@1+ (1,0) [0|0] "" Vector__XXX

BO_ 525 TAS_states: 8 Vector__XXX
 SG_ TAS_levelingState : 0|4@1+ (1,0) [0|0] "" Vector__XXX
 SG_ TAS_levelingItem : 4|3@1+ (1,0) [0|0] "" Vector__XXX
 SG_ TAS_pressureGallery : 8|8@1+ (0.1,0) [0|0] "" Vector__XXX
 SG_ TAS_pressureReservoir : 16|8@1+ (0.1,0) [0|0] "" Vector__XXX
 SG_ TAS_runMode : 24|3@1+ (1,0) [0|0] "" Vector__XXX
 SG_ TAS_filterMode : 27|3@1+ (1,0) [0|0] "" Vector__XXX
 SG_ TAS_compressorRun : 30|1@1+ (1,0) [0|0] "" Vector__XXX
 SG_ TAS_twistDetected : 31|1@1+ (1,0) [0|0] "" Vector__XXX
 SG_ TAS_leanDetected : 32|1@1+ (1,0) [0|0] "" Vector__XXX
 SG_ TAS_limpHomeMode : 33|3@1+ (1,0) [0|0] "" Vector__XXX
 SG_ TAS_targetLevel : 36|3@1+ (1,0) [0|0] "" Vector__XXX
 SG_ TAS_currentLevel : 40|3@1+ (1,0) [0|0] "" Vector__XXX
 SG_ TAS_jackMode : 43|1@1+ (1,0) [0|0] "" Vector__XXX
 SG_ TAS_reduceVehicleSpeedRequest : 44|1@1+ (1,0) [0|0] "" Vector__XXX
 SG_ TAS_statesCounter : 52|4@1+ (1,0) [0|0] "" Vector__XXX
 SG_ TAS_statesChecksum : 56|8@1+ (1,0) [0|0] "" Vector__XXX

BO_ 526 DAS_autonomyControl: 8 Vector__XXX
 SG_ DAS_autonomyControlChecksum : 0|8@1+ (1,0) [0|0] "" Vector__XXX
 SG_ DAS_autonomyControlCounter : 8|3@1+ (1,0) [0|0] "" Vector__XXX
 SG_ DAS_manualDrivingProhibited : 11|1@1+ (1,0) [0|0] "" Vector__XXX
 SG_ DAS_autonomyControlActive : 12|1@1+ (1,0) [0|0] "" Vector__XXX
 SG_ DAS_autonomyBehavior : 13|2@1+ (1,0) [0|0] "" Vector__XXX

BO_ 529 RCM_status: 8 Vector__XXX
 SG_ RCM_statusChecksum : 0|8@1+ (1,0) [0|0] "" Vector__XXX
 SG_ RCM_statusCounter : 8|4@1+ (1,0) [0|0] "" Vector__XXX
 SG_ RCM_armStatus : 12|2@1+ (1,0) [0|0] "" Vector__XXX
 SG_ RCM_warningIndicatorState : 14|2@1+ (1,0) [0|0] "" Vector__XXX
 SG_ RCM_passAirbagIndicatorRequest : 16|2@1+ (1,0) [0|0] "" Vector__XXX
 SG_ RCM_airbagCutoffStatus : 18|2@1+ (1,0) [0|0] "" Vector__XXX
 SG_ RCM_alrSwitchStatus : 20|2@1+ (1,0) [0|0] "" Vector__XXX
 SG_ RCM_vinLearnFlag : 22|2@1+ (1,0) [0|0] "" Vector__XXX
 SG_ RCM_seatTrackPositionDrvr : 24|2@1+ (1,0) [0|0] "" Vector__XXX
 SG_ RCM_seatTrackPositionPass : 26|2@1+ (1,0) [0|0] "" Vector__XXX
 SG_ RCM_edr1State : 28|2@1+ (1,0) [0|0] "" Vector__XXX
 SG_ RCM_edr2State : 30|2@1+ (1,0) [0|0] "" Vector__XXX
 SG_ RCM_keepPowerReason : 32|4@1+ (1,0) [0|0] "" Vector__XXX
 SG_ RCM_imuOffsetLearnState : 36|2@1+ (1,0) [0|0] "" Vector__XXX
 SG_ RCM_edr3State : 38|2@1+ (1,0) [0|0] "" Vector__XXX
 SG_ RCM_driverOrientationInitStatus : 40|3@1+ (1,0) [0|0] "" Vector__XXX
 SG_ RCM_occupantClassificationSource : 43|1@1+ (1,0) [0|0] "" Vector__XXX
 SG_ RCM_pedProEDR1State : 44|2@1+ (1,0) [0|0] "" Vector__XXX
 SG_ RCM_pedProEDR2State : 46|2@1+ (1,0) [0|0] "" Vector__XXX

BO_ 530 BMS_status: 8 Vector__XXX
 SG_ BMS_hvacPowerRequest : 0|1@1+ (1,0) [0|0] "" Vector__XXX
 SG_ BMS_notEnoughPowerForDrive : 1|1@1+ (1,0) [0|0] "" Vector__XXX
 SG_ BMS_notEnoughPowerForSupport : 2|1@1+ (1,0) [0|0] "" Vector__XXX
 SG_ BMS_preconditionAllowed : 3|1@1+ (1,0) [0|0] "" Vector__XXX
 SG_ BMS_updateAllowed : 4|1@1+ (1,0) [0|0] "" Vector__XXX
 SG_ BMS_cpMiaOnHvs : 5|1@1+ (1,0) [0|0] "" Vector__XXX
 SG_ BMS_pcsPwmEnabled : 6|1@1+ (1,0) [0|0] "" Vector__XXX
 SG_ BMS_contactorState : 8|3@1+ (1,0) [0|0] "" Vector__XXX
 SG_ BMS_userChargeStatus : 11|3@1+ (1,0) [0|0] "" Vector__XXX
 SG_ BMS_batteryInputPower : 14|16@1+ (0.05,0) [0|0] "" Vector__XXX
 SG_ BMS_chargeRequest : 30|1@1+ (1,0) [0|0] "" Vector__XXX
 SG_ BMS_state : 32|4@1+ (1,0) [0|0] "" Vector__XXX
 SG_ BMS_diLimpRequest : 36|1@1+ (1,0) [0|0] "" Vector__XXX
 SG_ BMS_okToShipByAir : 37|1@1+ (1,0) [0|0] "" Vector__XXX
 SG_ BMS_okToShipByLand : 38|1@1+ (1,0) [0|0] "" Vector__XXX
 SG_ BMS_chgPowerAvailable : 39|12@1+ (0.125,0) [0|0] "" Vector__XXX
 SG_ BMS_chargeRetryCount : 52|3@1+ (1,0) [0|0] "" Vector__XXX
 SG_ BMS_conditioningRequest : 55|1@1+ (1,0) [0|0] "" Vector__XXX
 SG_ BMS_smStateRequest : 56|4@1+ (1,0) [0|0] "" Vector__XXX
 SG_ BMS_hvState : 60|3@1+ (1,0) [0|0] "" Vector__XXX

BO_ 531 UI_cruiseControl: 8 Vector__XXX
 SG_ UI_cruiseSpeedCommand : 0|3@1+ (1,0) [0|0] "" Vector__XXX
 SG_ UI_smartSummonRequest : 3|1@1+ (1,0) [0|0] "" Vector__XXX
 SG_ UI_cruiseControlCounter : 4|4@1+ (1,0) [0|0] "" Vector__XXX
 SG_ UI_cruiseControlChecksum : 8|8@1+ (1,0) [0|0] "" Vector__XXX

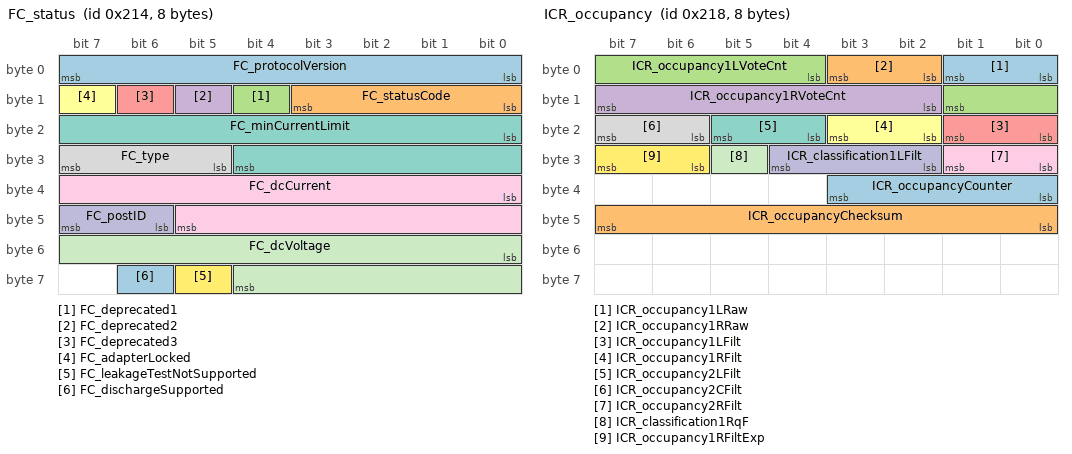
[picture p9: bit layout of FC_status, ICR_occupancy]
BO_ 532 FC_status: 8 Vector__XXX
 SG_ FC_protocolVersion : 0|8@1+ (1,0) [0|0] "" Vector__XXX
 SG_ FC_statusCode : 8|4@1+ (1,0) [0|0] "" Vector__XXX
 SG_ FC_deprecated1 : 12|1@1+ (1,0) [0|0] "" Vector__XXX
 SG_ FC_deprecated2 : 13|1@1+ (1,0) [0|0] "" Vector__XXX
 SG_ FC_deprecated3 : 14|1@1+ (1,0) [0|0] "" Vector__XXX
 SG_ FC_adapterLocked : 15|1@1+ (1,0) [0|0] "" Vector__XXX
 SG_ FC_minCurrentLimit : 16|13@1+ (0.1,0) [0|0] "" Vector__XXX
 SG_ FC_type : 29|3@1+ (1,0) [0|0] "" Vector__XXX
 SG_ FC_dcCurrent : 32|14@1- (0.0732421875,0) [0|0] "" Vector__XXX
 SG_ FC_postID : 46|2@1+ (1,0) [0|0] "" Vector__XXX
 SG_ FC_dcVoltage : 48|13@1+ (0.07324218755,0) [0|0] "" Vector__XXX
 SG_ FC_leakageTestNotSupported : 61|1@1+ (1,0) [0|0] "" Vector__XXX
 SG_ FC_dischargeSupported : 62|1@1+ (1,0) [0|0] "" Vector__XXX

BO_ 533 FC_status2: 8 Vector__XXX
 SG_ FC_externalIsolationResistance : 0|8@1+ (40,0) [0|0] "" Vector__XXX

BO_ 535 FC_status3: 8 Vector__XXX
 SG_ FC_status3DataSelect M : 0|7@1+ (1,0) [0|0] "" Vector__XXX
 SG_ FC_status3DummySig : 7|1@1+ (1,0) [0|0] "" Vector__XXX
 SG_ FC_billingEnergy m1 : 8|16@1+ (0.0152590219,0) [0|0] "" Vector__XXX
 SG_ FC_class m0 : 8|8@1+ (1,0) [0|0] "" Vector__XXX
 SG_ FC_brand m0 : 16|4@1+ (1,0) [0|0] "" Vector__XXX
 SG_ FC_coolingType m0 : 20|4@1+ (1,0) [0|0] "" Vector__XXX
 SG_ FC_uiStopType m0 : 24|4@1+ (1,0) [0|0] "" Vector__XXX
 SG_ FC_emergencyShutdownSupported m0 : 28|1@1+ (1,0) [0|0] "" Vector__XXX
 SG_ FC_generation m0 : 32|8@1+ (1,0) [0|0] "" Vector__XXX

BO_ 536 ICR_occupancy: 8 Vector__XXX
 SG_ ICR_occupancy1LRaw : 0|2@1+ (1,0) [0|0] "" Vector__XXX
 SG_ ICR_occupancy1RRaw : 2|2@1+ (1,0) [0|0] "" Vector__XXX
 SG_ ICR_occupancy1LVoteCnt : 4|6@1- (1,0) [0|0] "" Vector__XXX
 SG_ ICR_occupancy1RVoteCnt : 10|6@1- (1,0) [0|0] "" Vector__XXX
 SG_ ICR_occupancy1LFilt : 16|2@1+ (1,0) [0|0] "" Vector__XXX
 SG_ ICR_occupancy1RFilt : 18|2@1+ (1,0) [0|0] "" Vector__XXX
 SG_ ICR_occupancy2LFilt : 20|2@1+ (1,0) [0|0] "" Vector__XXX
 SG_ ICR_occupancy2CFilt : 22|2@1+ (1,0) [0|0] "" Vector__XXX
 SG_ ICR_occupancy2RFilt : 24|2@1+ (1,0) [0|0] "" Vector__XXX
 SG_ ICR_classification1LFilt : 26|3@1+ (1,0) [0|0] "" Vector__XXX
 SG_ ICR_classification1RqF : 29|1@1+ (1,0) [0|0] "" Vector__XXX
 SG_ ICR_occupancy1RFiltExp : 30|2@1+ (1,0) [0|0] "" Vector__XXX
 SG_ ICR_occupancyCounter : 32|4@1+ (1,0) [0|0] "" Vector__XXX
 SG_ ICR_occupancyChecksum : 40|8@1+ (1,0) [0|0] "" Vector__XXX

BO_ 537 VCSEC_TPMSData: 8 Vector__XXX
 SG_ VCSEC_TPMSDataIndex M : 0|3@1+ (1,0) [0|0] "" Vector__XXX
 SG_ VCSEC_TPMSAutonomyStatus m5 : 3|2@1+ (1,0) [0|0] "" Vector__XXX
 SG_ VCSEC_TPMSCapabilityPressureInAdv0 m0 : 3|1@1+ (1,0) [0|0] "" Vector__XXX
 SG_ VCSEC_TPMSCapabilityPressureInAdv1 m1 : 3|1@1+ (1,0) [0|0] "" Vector__XXX
 SG_ VCSEC_TPMSCapabilityPressureInAdv2 m2 : 3|1@1+ (1,0) [0|0] "" Vector__XXX
 SG_ VCSEC_TPMSCapabilityPressureInAdv3 m3 : 3|1@1+ (1,0) [0|0] "" Vector__XXX
 SG_ VCSEC_TPMSCapabilityConfigurablePressure0 m0 : 4|1@1+ (1,0) [0|0] "" Vector__XXX
 SG_ VCSEC_TPMSCapabilityConfigurablePressure1 m1 : 4|1@1+ (1,0) [0|0] "" Vector__XXX
 SG_ VCSEC_TPMSCapabilityConfigurablePressure2 m2 : 4|1@1+ (1,0) [0|0] "" Vector__XXX
 SG_ VCSEC_TPMSCapabilityConfigurablePressure3 m3 : 4|1@1+ (1,0) [0|0] "" Vector__XXX
 SG_ VCSEC_TPMSAutonomyStatusMIATimeS m5 : 5|9@1+ (1,0) [0|0] "" Vector__XXX
 SG_ VCSEC_TPMSPressureRateOfChange0 m0 : 5|10@1- (0.02,0) [0|0] "" Vector__XXX
 SG_ VCSEC_TPMSPressureRateOfChange1 m1 : 5|10@1- (0.02,0) [0|0] "" Vector__XXX
 SG_ VCSEC_TPMSPressureRateOfChange2 m2 : 5|10@1- (0.02,0) [0|0] "" Vector__XXX
 SG_ VCSEC_TPMSPressureRateOfChange3 m3 : 5|10@1- (0.02,0) [0|0] "" Vector__XXX
 SG_ VCSEC_TPMSRecommendedColdPressureFront m4 : 8|8@1+ (0.025,0) [0|0] "" Vector__XXX
 SG_ VCSEC_TPMSPressure0 m0 : 15|9@1+ (0.025,0) [0|0] "" Vector__XXX
 SG_ VCSEC_TPMSPressure1 m1 : 15|9@1+ (0.025,0) [0|0] "" Vector__XXX
 SG_ VCSEC_TPMSPressure2 m2 : 15|9@1+ (0.025,0) [0|0] "" Vector__XXX
 SG_ VCSEC_TPMSPressure3 m3 : 15|9@1+ (0.025,0) [0|0] "" Vector__XXX
 SG_ VCSEC_TPMSLastKnownPressureFL m5 : 16|8@1+ (0.025,0) [0|0] "" Vector__XXX
 SG_ VCSEC_TPMSRecommendedColdPressureRear m4 : 16|8@1+ (0.025,0) [0|0] "" Vector__XXX
 SG_ VCSEC_TPMSFeature0 m4 : 24|3@1+ (1,0) [0|0] "" Vector__XXX
 SG_ VCSEC_TPMSLastKnownPressureFR m5 : 24|8@1+ (0.025,0) [0|0] "" Vector__XXX
 SG_ VCSEC_TPMSTemperature0 m0 : 24|8@1+ (1,-40) [0|0] "" Vector__XXX
 SG_ VCSEC_TPMSTemperature1 m1 : 24|8@1+ (1,-40) [0|0] "" Vector__XXX
 SG_ VCSEC_TPMSTemperature2 m2 : 24|8@1+ (1,-40) [0|0] "" Vector__XXX
 SG_ VCSEC_TPMSTemperature3 m3 : 24|8@1+ (1,-40) [0|0] "" Vector__XXX
 SG_ VCSEC_TPMSFeature1 m4 : 27|3@1+ (1,0) [0|0] "" Vector__XXX
 SG_ VCSEC_TPMSBatVoltage0 m0 : 32|8@1+ (0.01,1.5) [0|0] "" Vector__XXX
 SG_ VCSEC_TPMSBatVoltage1 m1 : 32|8@1+ (0.01,1.5) [0|0] "" Vector__XXX
 SG_ VCSEC_TPMSBatVoltage2 m2 : 32|8@1+ (0.01,1.5) [0|0] "" Vector__XXX
 SG_ VCSEC_TPMSBatVoltage3 m3 : 32|8@1+ (0.01,1.5) [0|0] "" Vector__XXX
 SG_ VCSEC_TPMSFeature0Count m4 : 32|4@1+ (1,0) [0|0] "" Vector__XXX
 SG_ VCSEC_TPMSLastKnownPressureRL m5 : 32|8@1+ (0.025,0) [0|0] "" Vector__XXX
 SG_ VCSEC_TPMSFeature0TimeS m4 : 36|11@1+ (1,0) [0|0] "" Vector__XXX
 SG_ VCSEC_TPMSLastKnownPressureRR m5 : 40|8@1+ (0.025,0) [0|0] "" Vector__XXX
 SG_ VCSEC_TPMSLocation0 m0 : 40|3@1+ (1,0) [0|0] "" Vector__XXX
 SG_ VCSEC_TPMSLocation1 m1 : 40|3@1+ (1,0) [0|0] "" Vector__XXX
 SG_ VCSEC_TPMSLocation2 m2 : 40|3@1+ (1,0) [0|0] "" Vector__XXX
 SG_ VCSEC_TPMSLocation3 m3 : 40|3@1+ (1,0) [0|0] "" Vector__XXX
 SG_ VCSEC_TPMSTemperatureCompensatedPressure0 m0 : 43|9@1+ (0.025,0) [0|0] "" Vector__XXX
 SG_ VCSEC_TPMSTemperatureCompensatedPressure1 m1 : 43|9@1+ (0.025,0) [0|0] "" Vector__XXX
 SG_ VCSEC_TPMSTemperatureCompensatedPressure2 m2 : 43|9@1+ (0.025,0) [0|0] "" Vector__XXX
 SG_ VCSEC_TPMSTemperatureCompensatedPressure3 m3 : 43|9@1+ (0.025,0) [0|0] "" Vector__XXX

BO_ 538 TAS_uiControl: 8 Vector__XXX
 SG_ TAS_yellowWarningLamp : 0|1@1+ (1,0) [0|0] "" Vector__XXX
 SG_ TAS_redWarningLamp : 1|1@1+ (1,0) [0|0] "" Vector__XXX
 SG_ TAS_veryLowAllowed : 2|1@1+ (1,0) [0|0] "" Vector__XXX
 SG_ TAS_lowAllowed : 3|1@1+ (1,0) [0|0] "" Vector__XXX
 SG_ TAS_standardAllowed : 4|1@1+ (1,0) [0|0] "" Vector__XXX
 SG_ TAS_highAllowed : 5|1@1+ (1,0) [0|0] "" Vector__XXX
 SG_ TAS_veryHighAllowed : 6|1@1+ (1,0) [0|0] "" Vector__XXX
 SG_ TAS_extractAllowed : 7|1@1+ (1,0) [0|0] "" Vector__XXX
 SG_ TAS_showSpinner : 9|1@1+ (1,0) [0|0] "" Vector__XXX
 SG_ TAS_adaptiveRideModeOverride : 10|2@1+ (1,0) [0|0] "" Vector__XXX
 SG_ TAS_levelSelectEnabled : 12|1@1+ (1,0) [0|0] "" Vector__XXX
 SG_ TAS_jackModeToggleEnabled : 13|1@1+ (1,0) [0|0] "" Vector__XXX
 SG_ TAS_adaptiveRideSelectEnabled : 14|1@1+ (1,0) [0|0] "" Vector__XXX
 SG_ TAS_launchModeState : 16|3@1+ (1,0) [0|0] "" Vector__XXX
 SG_ TAS_restrictUpLevelingFalcons : 19|1@1+ (1,0) [0|0] "" Vector__XXX
 SG_ TAS_restrictUpLevelingTrunk : 20|1@1+ (1,0) [0|0] "" Vector__XXX
 SG_ TAS_restrictDownLevelingDoors : 21|1@1+ (1,0) [0|0] "" Vector__XXX
 SG_ TAS_restrictLevelingChargeCable : 22|1@1+ (1,0) [0|0] "" Vector__XXX
 SG_ TAS_restrictLevelingSystemCheck : 23|1@1+ (1,0) [0|0] "" Vector__XXX
 SG_ TAS_restrictLevelingTransport : 24|1@1+ (1,0) [0|0] "" Vector__XXX
 SG_ TAS_restrictLevelingShowroom : 25|1@1+ (1,0) [0|0] "" Vector__XXX
 SG_ TAS_uiControlCounter : 28|4@1+ (1,0) [0|0] "" Vector__XXX
 SG_ TAS_uiControlChecksum : 32|8@1+ (1,0) [0|0] "" Vector__XXX

BO_ 541 CP_evseStatus: 8 Vector__XXX
 SG_ CP_evseAccept : 0|1@1+ (1,0) [0|0] "" Vector__XXX
 SG_ CP_evseRequest : 1|1@1+ (1,0) [0|0] "" Vector__XXX
 SG_ CP_proximity : 2|2@1+ (1,0) [0|0] "" Vector__XXX
 SG_ CP_pilot : 4|3@1+ (1,0) [0|0] "" Vector__XXX
 SG_ CP_digitalCommsEstablished : 7|1@1+ (1,0) [0|0] "" Vector__XXX
 SG_ CP_pilotCurrent : 8|8@1+ (0.5,0) [0|0] "" Vector__XXX
 SG_ CP_cableType : 16|3@1+ (1,0) [0|0] "" Vector__XXX
 SG_ CP_iecPilotState : 19|4@1+ (1,0) [0|0] "" Vector__XXX
 SG_ CP_plcSupported : 23|1@1+ (1,0) [0|0] "" Vector__XXX
 SG_ CP_cableCurrentLimit : 24|7@1+ (1,0) [0|0] "" Vector__XXX
 SG_ CP_teslaSwcanState : 34|4@1+ (1,0) [0|0] "" Vector__XXX
 SG_ CP_evseChargeType_UI : 38|2@1+ (1,0) [0|0] "" Vector__XXX
 SG_ CP_gbState : 40|4@1+ (1,0) [0|0] "" Vector__XXX
 SG_ CP_gbdcStopChargeReason : 44|4@1+ (1,0) [0|0] "" Vector__XXX
 SG_ CP_gbdcFailureReason : 48|2@1+ (1,0) [0|0] "" Vector__XXX
 SG_ CP_gbdcChargeAttempts : 50|2@1+ (1,0) [0|0] "" Vector__XXX
 SG_ CP_acChargeState : 52|3@1+ (1,0) [0|0] "" Vector__XXX
 SG_ CP_acChargeType : 56|2@1+ (1,0) [0|0] "" Vector__XXX
 SG_ CP_teslaDcState : 58|4@1+ (1,0) [0|0] "" Vector__XXX

BO_ 545 VCFRONT_LVPowerState: 8 Vector__XXX
 SG_ VCFRONT_LVPowerStateIndex M : 0|5@1+ (1,0) [0|0] "" Vector__XXX
 SG_ VCFRONT_vehiclePowerState : 5|2@1+ (1,0) [0|0] "" Vector__XXX
 SG_ VCFRONT_cpLVRequest m1 : 8|2@1+ (1,0) [0|0] "" Vector__XXX
 SG_ VCFRONT_parkLVState m0 : 8|2@1+ (1,0) [0|0] "" Vector__XXX
 SG_ VCFRONT_epasLVState m1 : 10|2@1+ (1,0) [0|0] "" Vector__XXX
 SG_ VCFRONT_espLVState m0 : 10|2@1+ (1,0) [0|0] "" Vector__XXX
 SG_ VCFRONT_hvcLVRequest m1 : 12|2@1+ (1,0) [0|0] "" Vector__XXX
 SG_ VCFRONT_radcLVState m0 : 12|2@1+ (1,0) [0|0] "" Vector__XXX
 SG_ VCFRONT_hvacCompLVState m0 : 14|2@1+ (1,0) [0|0] "" Vector__XXX
 SG_ VCFRONT_tasLVState m1 : 14|2@1+ (1,0) [0|0] "" Vector__XXX
 SG_ VCFRONT_pcsLVState m1 : 16|2@1+ (1,0) [0|0] "" Vector__XXX
 SG_ VCFRONT_ptcLVRequest m0 : 16|2@1+ (1,0) [0|0] "" Vector__XXX
 SG_ VCFRONT_CMPDLVState m1 : 18|2@1+ (1,0) [0|0] "" Vector__XXX
 SG_ VCFRONT_sccmLVRequest m0 : 18|2@1+ (1,0) [0|0] "" Vector__XXX
 SG_ VCFRONT_hcmlLVState m1 : 20|2@1+ (1,0) [0|0] "" Vector__XXX
 SG_ VCFRONT_tpmsLVRequest m0 : 20|2@1+ (1,0) [0|0] "" Vector__XXX
 SG_ VCFRONT_hcmrLVState m1 : 22|2@1+ (1,0) [0|0] "" Vector__XXX
 SG_ VCFRONT_rcmLVRequest m0 : 22|2@1+ (1,0) [0|0] "" Vector__XXX
 SG_ VCFRONT_MCUAudioLVState m1 : 24|2@1+ (1,0) [0|0] "" Vector__XXX
 SG_ VCFRONT_iBoosterLVState m0 : 24|2@1+ (1,0) [0|0] "" Vector__XXX
 SG_ VCFRONT_espValveLVState m1 : 26|2@1+ (1,0) [0|0] "" Vector__XXX
 SG_ VCFRONT_tunerLVRequest m0 : 26|2@1+ (1,0) [0|0] "" Vector__XXX
 SG_ VCFRONT_MCUGraphicsLVState m1 : 28|2@1+ (1,0) [0|0] "" Vector__XXX
 SG_ VCFRONT_amplifierLVRequest m0 : 28|2@1+ (1,0) [0|0] "" Vector__XXX
 SG_ VCFRONT_das1HighCurrentLVState m0 : 30|2@1+ (1,0) [0|0] "" Vector__XXX
 SG_ VC_dcdcSupportRequest m1 : 30|1@1+ (1,0) [0|0] "" Vector__XXX
 SG_ VC_hvStateRequest m1 : 31|3@1+ (1,0) [0|0] "" Vector__XXX
 SG_ VCFRONT_das2HighCurrentLVState m0 : 32|2@1+ (1,0) [0|0] "" Vector__XXX
 SG_ VCFRONT_dirLVRequest m0 : 34|2@1+ (1,0) [0|0] "" Vector__XXX
 SG_ VCFRONT_difLVState m0 : 36|2@1+ (1,0) [0|0] "" Vector__XXX
 SG_ VCFRONT_oilPumpFrontLVState m0 : 38|2@1+ (1,0) [0|0] "" Vector__XXX
 SG_ VC_persistAccPowerRequestOverridden m1 : 39|1@1+ (1,0) [0|0] "" Vector__XXX
 SG_ VCFRONT_oilPumpRearLVRequest m0 : 40|2@1+ (1,0) [0|0] "" Vector__XXX
 SG_ VC_accPortPowerRequest m1 : 40|1@1+ (1,0) [0|0] "" Vector__XXX
 SG_ VC_persistAccPortPowerState m1 : 41|3@1+ (1,0) [0|0] "" Vector__XXX
 SG_ VCFRONT_ocsLVRequest m0 : 42|2@1+ (1,0) [0|0] "" Vector__XXX
 SG_ VCFRONT_vcleftHiCurrentLVState m0 : 44|2@1+ (1,0) [0|0] "" Vector__XXX
 SG_ VCFRONT_vcrightHiCurrentLVState m0 : 46|2@1+ (1,0) [0|0] "" Vector__XXX
 SG_ VC_noAccDeviceDetectedWhileIdle m1 : 46|1@1+ (1,0) [0|0] "" Vector__XXX
 SG_ VCFRONT_uiHiCurrentLVState m0 : 48|2@1+ (1,0) [0|0] "" Vector__XXX
 SG_ VCFRONT_inAccessoryPlus : 50|1@1+ (1,0) [0|0] "" Vector__XXX
 SG_ VCFRONT_LVShuttingDown : 51|1@1+ (1,0) [0|0] "" Vector__XXX
 SG_ VCFRONT_LVPowerStateCounter : 52|4@1+ (1,0) [0|0] "" Vector__XXX
 SG_ VCFRONT_LVPowerStateChecksum : 56|8@1+ (1,0) [0|0] "" Vector__XXX

BO_ 546 TAS_compTemp: 8 Vector__XXX
 SG_ TAS_compTempSensor : 0|8@1+ (1,-40) [0|0] "" Vector__XXX
 SG_ TAS_compTempModel : 8|8@1+ (1,-40) [0|0] "" Vector__XXX

BO_ 548 PCS_dcdcStatus: 8 Vector__XXX
 SG_ PCS_dcdcPrechargeStatus : 0|2@1+ (1,0) [0|0] "" Vector__XXX
 SG_ PCS_dcdcLvSupportStatus : 2|2@1+ (1,0) [0|0] "" Vector__XXX
 SG_ PCS_dcdcHvBusDischargeStatus : 4|2@1+ (1,0) [0|0] "" Vector__XXX
 SG_ PCS_coldSleepAllowed : 8|1@1+ (1,0) [0|0] "" Vector__XXX
 SG_ PCS_dcdcPchgHVBusLowRDetected : 9|1@1+ (1,0) [0|0] "" Vector__XXX
 SG_ PCS_dcdcSubState : 10|5@1+ (1,0) [0|0] "" Vector__XXX
 SG_ PCS_dcdcFaulted : 15|1@1+ (1,0) [0|0] "" Vector__XXX
 SG_ PCS_okToBePowerCycled : 27|1@1+ (1,0) [0|0] "" Vector__XXX
 SG_ PCS_dcdcOutputIsLimited : 28|1@1+ (1,0) [0|0] "" Vector__XXX
 SG_ PCS_dcdcMaxOutputCurrentAllowed : 29|12@1+ (0.1,0) [0|0] "" Vector__XXX
 SG_ PCS_dcdcPrechargeRtyCnt : 41|3@1+ (1,0) [0|0] "" Vector__XXX
 SG_ PCS_dcdcLvSupportRtyCnt : 44|4@1+ (1,0) [0|0] "" Vector__XXX
 SG_ PCS_dcdcDischargeRtyCnt : 48|4@1+ (1,0) [0|0] "" Vector__XXX
 SG_ PCS_dcdcPwmEnableLine : 52|1@1+ (1,0) [0|0] "" Vector__XXX
 SG_ PCS_dcdcSupportingFixedLvTarget : 53|1@1+ (1,0) [0|0] "" Vector__XXX
 SG_ PCS_ecuLogUploadRequest : 54|2@1+ (1,0) [0|0] "" Vector__XXX
 SG_ PCS_dcdcPrechargeRestartCnt : 56|3@1+ (1,0) [0|0] "" Vector__XXX
 SG_ PCS_dcdcInitialPrechargeSubState : 59|5@1+ (1,0) [0|0] "" Vector__XXX

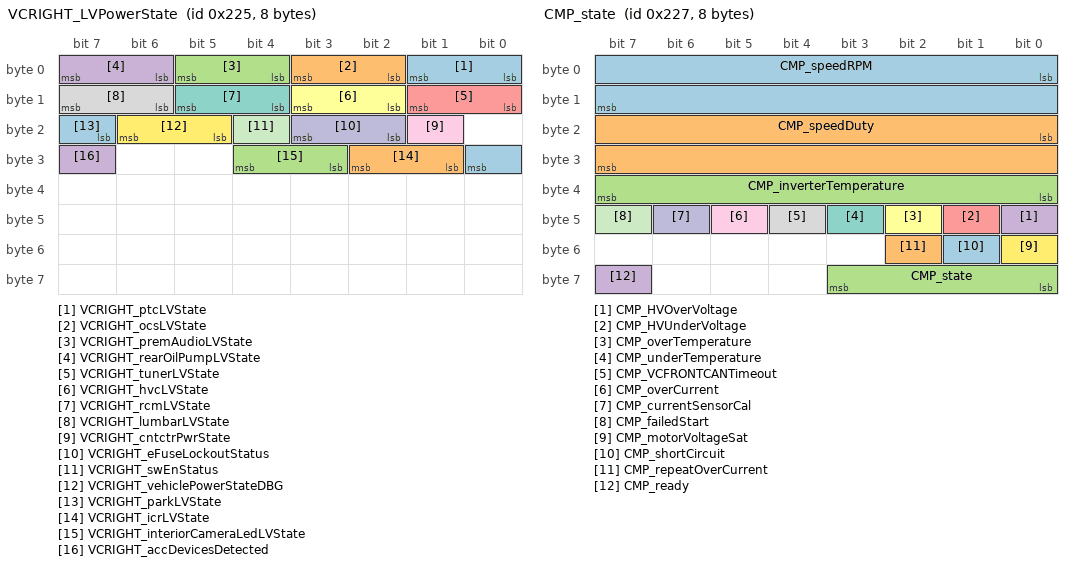
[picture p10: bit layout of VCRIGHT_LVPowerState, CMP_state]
BO_ 549 VCRIGHT_LVPowerState: 8 Vector__XXX
 SG_ VCRIGHT_ptcLVState : 0|2@1+ (1,0) [0|0] "" Vector__XXX
 SG_ VCRIGHT_ocsLVState : 2|2@1+ (1,0) [0|0] "" Vector__XXX
 SG_ VCRIGHT_premAudioLVState : 4|2@1+ (1,0) [0|0] "" Vector__XXX
 SG_ VCRIGHT_rearOilPumpLVState : 6|2@1+ (1,0) [0|0] "" Vector__XXX
 SG_ VCRIGHT_tunerLVState : 8|2@1+ (1,0) [0|0] "" Vector__XXX
 SG_ VCRIGHT_hvcLVState : 10|2@1+ (1,0) [0|0] "" Vector__XXX
 SG_ VCRIGHT_rcmLVState : 12|2@1+ (1,0) [0|0] "" Vector__XXX
 SG_ VCRIGHT_lumbarLVState : 14|2@1+ (1,0) [0|0] "" Vector__XXX
 SG_ VCRIGHT_cntctrPwrState : 17|1@1+ (1,0) [0|0] "" Vector__XXX
 SG_ VCRIGHT_eFuseLockoutStatus : 18|2@1+ (1,0) [0|0] "" Vector__XXX
 SG_ VCRIGHT_swEnStatus : 20|1@1+ (1,0) [0|0] "" Vector__XXX
 SG_ VCRIGHT_vehiclePowerStateDBG : 21|2@1+ (1,0) [0|0] "" Vector__XXX
 SG_ VCRIGHT_parkLVState : 23|2@1+ (1,0) [0|0] "" Vector__XXX
 SG_ VCRIGHT_icrLVState : 25|2@1+ (1,0) [0|0] "" Vector__XXX
 SG_ VCRIGHT_interiorCameraLedLVState : 27|2@1+ (1,0) [0|0] "" Vector__XXX
 SG_ VCRIGHT_accDevicesDetected : 31|1@1+ (1,0) [0|0] "" Vector__XXX

BO_ 551 CMP_state: 8 Vector__XXX
 SG_ CMP_speedRPM : 0|16@1+ (1,0) [0|0] "" Vector__XXX
 SG_ CMP_speedDuty : 16|16@1+ (0.1,0) [0|0] "" Vector__XXX
 SG_ CMP_inverterTemperature : 32|8@1+ (1,-40) [0|0] "" Vector__XXX
 SG_ CMP_HVOverVoltage : 40|1@1+ (1,0) [0|0] "" Vector__XXX
 SG_ CMP_HVUnderVoltage : 41|1@1+ (1,0) [0|0] "" Vector__XXX
 SG_ CMP_overTemperature : 42|1@1+ (1,0) [0|0] "" Vector__XXX
 SG_ CMP_underTemperature : 43|1@1+ (1,0) [0|0] "" Vector__XXX
 SG_ CMP_VCFRONTCANTimeout : 44|1@1+ (1,0) [0|0] "" Vector__XXX
 SG_ CMP_overCurrent : 45|1@1+ (1,0) [0|0] "" Vector__XXX
 SG_ CMP_currentSensorCal : 46|1@1+ (1,0) [0|0] "" Vector__XXX
 SG_ CMP_failedStart : 47|1@1+ (1,0) [0|0] "" Vector__XXX
 SG_ CMP_motorVoltageSat : 48|1@1+ (1,0) [0|0] "" Vector__XXX
 SG_ CMP_shortCircuit : 49|1@1+ (1,0) [0|0] "" Vector__XXX
 SG_ CMP_repeatOverCurrent : 50|1@1+ (1,0) [0|0] "" Vector__XXX
 SG_ CMP_state : 56|4@1+ (1,0) [0|0] "" Vector__XXX
 SG_ CMP_ready : 63|1@1+ (1,0) [0|0] "" Vector__XXX

BO_ 552 EPBR_internalStatus: 8 Vector__XXX
 SG_ EPBR_unitStatus : 0|5@1+ (1,0) [0|0] "" Vector__XXX
 SG_ EPBR_unitFaultStatus : 5|2@1+ (1,0) [0|0] "" Vector__XXX
 SG_ EPBR_summonState : 8|3@1+ (1,0) [0|0] "" Vector__XXX
 SG_ EPBR_disconnected : 11|1@1+ (1,0) [0|0] "" Vector__XXX
 SG_ EPBR_pistonTouchingRotor : 12|1@1+ (1,0) [0|0] "" Vector__XXX
 SG_ EPBR_csmFaultReason : 13|5@1+ (1,0) [0|0] "" Vector__XXX
 SG_ EPBR_esmOperationTrigger : 18|6@1+ (1,0) [0|0] "" Vector__XXX
 SG_ EPBR_summonFaultReason : 24|5@1+ (1,0) [0|0] "" Vector__XXX
 SG_ EPBR_localServiceModeActive : 29|1@1+ (1,0) [0|0] "" Vector__XXX
 SG_ EPBR_localCdpState : 30|2@1+ (1,0) [0|0] "" Vector__XXX
 SG_ EPBR_chimeRequestLocal : 33|3@1+ (1,0) [0|0] "" Vector__XXX
 SG_ EPBR_telltaleLocal : 39|3@1+ (1,0) [0|0] "" Vector__XXX
 SG_ EPBR_driverIsLeavingLocal : 42|1@1+ (1,0) [0|0] "" Vector__XXX
 SG_ EPBR_driverIsLeavingAnySpeedLocal : 43|1@1+ (1,0) [0|0] "" Vector__XXX
 SG_ EPBR_internalCDPRequest : 44|1@1+ (1,0) [0|0] "" Vector__XXX
 SG_ EPBR_esmSpeedClass : 45|3@1+ (1,0) [0|0] "" Vector__XXX
 SG_ EPBR_learnedEpbConfig : 48|4@1+ (1,0) [0|0] "" Vector__XXX
 SG_ EPBR_internalStatusCounter : 52|4@1+ (1,0) [0|0] "" Vector__XXX
 SG_ EPBR_internalStatusChecksum : 56|8@1+ (1,0) [0|0] "" Vector__XXX

BO_ 553 SCCM_rightStalk: 8 Vector__XXX
 SG_ SCCM_rightStalkCrc : 0|8@1+ (1,0) [0|0] "" Vector__XXX
 SG_ SCCM_rightStalkCounter : 8|4@1+ (1,0) [0|0] "" Vector__XXX
 SG_ SCCM_rightStalkStatus : 12|3@1+ (1,0) [0|0] "" Vector__XXX
 SG_ SCCM_rightStalkReserved1 : 15|1@1+ (1,0) [0|0] "" Vector__XXX
 SG_ SCCM_parkButtonStatus : 16|2@1+ (1,0) [0|0] "" Vector__XXX
 SG_ SCCM_rightStalkReserved2 : 18|6@1+ (1,0) [0|0] "" Vector__XXX

BO_ 554 HVP_hvsControl: 8 Vector__XXX
 SG_ HVP_dcLinkVoltageRequest : 0|16@1- (0.1,0) [0|0] "" Vector__XXX
 SG_ HVP_pcsControlRequest : 16|2@1+ (1,0) [0|0] "" Vector__XXX
 SG_ HVP_pcsChargeHwEnabled : 18|1@1+ (1,0) [0|0] "" Vector__XXX
 SG_ HVP_pcsDcdcHwEnabled : 19|1@1+ (1,0) [0|0] "" Vector__XXX
 SG_ HVP_dcLinkVoltageFiltered : 20|11@1- (1,0) [0|0] "" Vector__XXX

BO_ 555 DAS_matrixHighBeamRequest: 8 Vector__XXX
 SG_ DAS_azimuthSegmentLightRequests : 0|64@1+ (1,0) [0|0] "" Vector__XXX

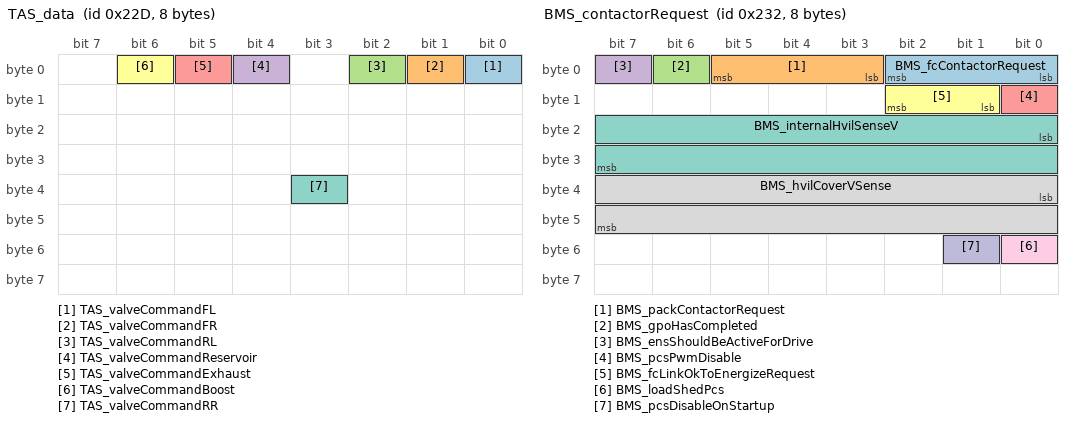
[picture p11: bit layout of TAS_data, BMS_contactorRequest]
BO_ 557 TAS_data: 8 Vector__XXX
 SG_ TAS_valveCommandFL : 0|1@1+ (1,0) [0|0] "" Vector__XXX
 SG_ TAS_valveCommandFR : 1|1@1+ (1,0) [0|0] "" Vector__XXX
 SG_ TAS_valveCommandRL : 2|1@1+ (1,0) [0|0] "" Vector__XXX
 SG_ TAS_valveCommandReservoir : 4|1@1+ (1,0) [0|0] "" Vector__XXX
 SG_ TAS_valveCommandExhaust : 5|1@1+ (1,0) [0|0] "" Vector__XXX
 SG_ TAS_valveCommandBoost : 6|1@1+ (1,0) [0|0] "" Vector__XXX
 SG_ TAS_valveCommandRR : 35|1@1+ (1,0) [0|0] "" Vector__XXX

BO_ 562 BMS_contactorRequest: 8 Vector__XXX
 SG_ BMS_fcContactorRequest : 0|3@1+ (1,0) [0|0] "" Vector__XXX
 SG_ BMS_packContactorRequest : 3|3@1+ (1,0) [0|0] "" Vector__XXX
 SG_ BMS_gpoHasCompleted : 6|1@1+ (1,0) [0|0] "" Vector__XXX
 SG_ BMS_ensShouldBeActiveForDrive : 7|1@1+ (1,0) [0|0] "" Vector__XXX
 SG_ BMS_pcsPwmDisable : 8|1@1+ (1,0) [0|0] "" Vector__XXX
 SG_ BMS_fcLinkOkToEnergizeRequest : 9|2@1+ (1,0) [0|0] "" Vector__XXX
 SG_ BMS_internalHvilSenseV : 16|16@1+ (0.001,0) [0|0] "" Vector__XXX
 SG_ BMS_hvilCoverVSense : 32|16@1+ (0.001,0) [0|0] "" Vector__XXX
 SG_ BMS_loadShedPcs : 48|1@1+ (1,0) [0|0] "" Vector__XXX
 SG_ BMS_pcsDisableOnStartup : 49|1@1+ (1,0) [0|0] "" Vector__XXX

BO_ 564 DCDC_power: 8 Vector__XXX
 SG_ DCDC_instantLvOutputPowerEstimated m0 : 0|12@1- (10,0) [0|0] "" Vector__XXX
 SG_ DCDC_transientLvOutputPowerLimit m1 : 0|10@1+ (10,0) [0|0] "" Vector__XXX
 SG_ DCDC_severeUvLvOutputPowerLimit m1 : 10|10@1+ (10,0) [0|0] "" Vector__XXX
 SG_ DCDC_filteredLvOutputPowerEstimated m0 : 12|12@1- (10,0) [0|0] "" Vector__XXX
 SG_ DCDC_severeOvLvInputPowerLimit m1 : 20|10@1+ (10,0) [0|0] "" Vector__XXX
 SG_ DCDC_continuousLvOutputPowerLimit m0 : 24|10@1+ (10,0) [0|0] "" Vector__XXX
 SG_ DCDC_minTargetContLvOutputPowerLimit m1 : 30|10@1+ (10,0) [0|0] "" Vector__XXX
 SG_ DCDC_instantLvOutputPowerLimit m0 : 34|10@1+ (10,0) [0|0] "" Vector__XXX
 SG_ DCDC_packSideContLvOutputPowerLimit m1 : 40|10@1+ (10,0) [0|0] "" Vector__XXX
 SG_ DCDC_auxiliaryStageSaturationWarning m0 : 44|1@1+ (1,0) [0|0] "" Vector__XXX
 SG_ DCDC_type m0 : 45|2@1+ (1,0) [0|0] "" Vector__XXX
 SG_ DCDC_powerMuxIndex M : 50|2@1+ (1,0) [0|0] "" Vector__XXX
 SG_ DCDC_powerCounter : 52|4@1+ (1,0) [0|0] "" Vector__XXX
 SG_ DCDC_powerChecksum : 56|8@1+ (1,0) [0|0] "" Vector__XXX

BO_ 568 UI_driverAssistMapData: 8 Vector__XXX
 SG_ UI_mapSpeedLimitDependency : 0|3@1+ (1,0) [0|0] "" Vector__XXX
 SG_ UI_roadClass : 3|3@1+ (1,0) [0|0] "" Vector__XXX
 SG_ UI_inSuperchargerGeofence : 6|1@1+ (1,0) [0|0] "" Vector__XXX
 SG_ UI_mapSpeedUnits : 7|1@1+ (1,0) [0|0] "" Vector__XXX
 SG_ UI_mapSpeedLimit : 8|5@1+ (1,0) [0|0] "" Vector__XXX
 SG_ UI_mapSpeedLimitType : 13|3@1+ (1,0) [0|0] "" Vector__XXX
 SG_ UI_countryCode : 16|10@1+ (1,0) [0|0] "" Vector__XXX
 SG_ UI_streetCount : 26|2@1+ (1,0) [0|0] "" Vector__XXX
 SG_ UI_gpsRoadMatch : 28|1@1+ (1,0) [0|0] "" Vector__XXX
 SG_ UI_navRouteActive : 29|1@1+ (1,0) [0|0] "" Vector__XXX
 SG_ UI_parallelAutoparkEnabled : 30|1@1+ (1,0) [0|0] "" Vector__XXX
 SG_ UI_perpendicularAutoparkEnabled : 31|1@1+ (1,0) [0|0] "" Vector__XXX
 SG_ UI_nextBranchDist : 32|5@1+ (10,0) [0|0] "" Vector__XXX
 SG_ UI_controlledAccess : 37|1@1+ (1,0) [0|0] "" Vector__XXX
 SG_ UI_nextBranchLeftOffRamp : 38|1@1+ (1,0) [0|0] "" Vector__XXX
 SG_ UI_nextBranchRightOffRamp : 39|1@1+ (1,0) [0|0] "" Vector__XXX
 SG_ UI_rejectLeftLane : 40|1@1+ (1,0) [0|0] "" Vector__XXX
 SG_ UI_rejectRightLane : 41|1@1+ (1,0) [0|0] "" Vector__XXX
 SG_ UI_rejectHPP : 42|1@1+ (1,0) [0|0] "" Vector__XXX
 SG_ UI_rejectNav : 43|1@1+ (1,0) [0|0] "" Vector__XXX
 SG_ UI_rejectLeftFreeSpace : 44|1@1+ (1,0) [0|0] "" Vector__XXX
 SG_ UI_rejectRightFreeSpace : 45|1@1+ (1,0) [0|0] "" Vector__XXX
 SG_ UI_rejectAutosteer : 46|1@1+ (1,0) [0|0] "" Vector__XXX
 SG_ UI_rejectHandsOn : 47|1@1+ (1,0) [0|0] "" Vector__XXX
 SG_ UI_acceptBottsDots : 48|1@1+ (1,0) [0|0] "" Vector__XXX
 SG_ UI_autosteerRestricted : 49|1@1+ (1,0) [0|0] "" Vector__XXX
 SG_ UI_pmmEnabled : 50|1@1+ (1,0) [0|0] "" Vector__XXX
 SG_ UI_scaEnabled : 51|1@1+ (1,0) [0|0] "" Vector__XXX
 SG_ UI_mapDataCounter : 52|4@1+ (1,0) [0|0] "" Vector__XXX
 SG_ UI_mapDataChecksum : 56|8@1+ (1,0) [0|0] "" Vector__XXX

BO_ 570 VCSEC_TPMSStatus: 8 Vector__XXX
 SG_ VCSEC_TPMSStatusIndex M : 0|5@1+ (1,0) [0|0] "" Vector__XXX
 SG_ VCSEC_TPMSSystemState : 5|1@1+ (1,0) [0|0] "" Vector__XXX
 SG_ VCSEC_BLESuccessfulConnEventCount0 m4 : 6|15@1+ (1,0) [0|0] "" Vector__XXX
 SG_ VCSEC_BLESuccessfulConnEventCount1 m5 : 6|15@1+ (1,0) [0|0] "" Vector__XXX
 SG_ VCSEC_BLESuccessfulConnEventCount2 m6 : 6|15@1+ (1,0) [0|0] "" Vector__XXX
 SG_ VCSEC_BLESuccessfulConnEventCount3 m7 : 6|15@1+ (1,0) [0|0] "" Vector__XXX
 SG_ VCSEC_TPMSSensorParameterState m28 : 6|2@1+ (1,0) [0|0] "" Vector__XXX
 SG_ VCSEC_TPMSLastLocationSensor0 m31 : 8|3@1+ (1,0) [0|0] "" Vector__XXX
 SG_ VCSEC_TPMSSensor0Hash m29 : 8|28@1+ (1,0) [0|0] "" Vector__XXX
 SG_ VCSEC_TPMSSensor2Hash m30 : 8|28@1+ (1,0) [0|0] "" Vector__XXX
 SG_ VCSEC_TPMSSensorMACAddress0 m0 : 8|48@1+ (1,0) [0|0] "" Vector__XXX
 SG_ VCSEC_TPMSSensorMACAddress1 m1 : 8|48@1+ (1,0) [0|0] "" Vector__XXX
 SG_ VCSEC_TPMSSensorMACAddress2 m2 : 8|48@1+ (1,0) [0|0] "" Vector__XXX
 SG_ VCSEC_TPMSSensorMACAddress3 m3 : 8|48@1+ (1,0) [0|0] "" Vector__XXX
 SG_ VCSEC_TPMSSensorTIAppCRC0 m8 : 8|32@1+ (1,0) [0|0] "" Vector__XXX
 SG_ VCSEC_TPMSSensorTIAppCRC1 m9 : 8|32@1+ (1,0) [0|0] "" Vector__XXX
 SG_ VCSEC_TPMSSensorTIAppCRC2 m10 : 8|32@1+ (1,0) [0|0] "" Vector__XXX
 SG_ VCSEC_TPMSSensorTIAppCRC3 m11 : 8|32@1+ (1,0) [0|0] "" Vector__XXX
 SG_ VCSEC_TPMSTotalResetsDueToPowerOn0 m20 : 8|8@1+ (1,0) [0|0] "" Vector__XXX
 SG_ VCSEC_TPMSTotalResetsDueToPowerOn1 m22 : 8|8@1+ (1,0) [0|0] "" Vector__XXX
 SG_ VCSEC_TPMSTotalResetsDueToPowerOn2 m24 : 8|8@1+ (1,0) [0|0] "" Vector__XXX
 SG_ VCSEC_TPMSTotalResetsDueToPowerOn3 m26 : 8|8@1+ (1,0) [0|0] "" Vector__XXX
 SG_ VCSEC_TPMSTotalResetsDueToWarmReset0 m21 : 8|8@1+ (1,0) [0|0] "" Vector__XXX
 SG_ VCSEC_TPMSTotalResetsDueToWarmReset1 m23 : 8|8@1+ (1,0) [0|0] "" Vector__XXX
 SG_ VCSEC_TPMSTotalResetsDueToWarmReset2 m25 : 8|8@1+ (1,0) [0|0] "" Vector__XXX
 SG_ VCSEC_TPMSTotalResetsDueToWarmReset3 m27 : 8|8@1+ (1,0) [0|0] "" Vector__XXX
 SG_ VCSEC_TPMStotalAwakeTime0 m16 : 8|32@1+ (1,0) [0|0] "" Vector__XXX
 SG_ VCSEC_TPMStotalAwakeTime1 m17 : 8|32@1+ (1,0) [0|0] "" Vector__XXX
 SG_ VCSEC_TPMStotalAwakeTime2 m18 : 8|32@1+ (1,0) [0|0] "" Vector__XXX
 SG_ VCSEC_TPMStotalAwakeTime3 m19 : 8|32@1+ (1,0) [0|0] "" Vector__XXX
 SG_ VCSEC_TPMStotalCPUTime0 m12 : 8|32@1+ (1,0) [0|0] "" Vector__XXX
 SG_ VCSEC_TPMStotalCPUTime1 m13 : 8|32@1+ (1,0) [0|0] "" Vector__XXX
 SG_ VCSEC_TPMStotalCPUTime2 m14 : 8|32@1+ (1,0) [0|0] "" Vector__XXX
 SG_ VCSEC_TPMStotalCPUTime3 m15 : 8|32@1+ (1,0) [0|0] "" Vector__XXX
 SG_ VCSEC_TPMSLastLocationSensor1 m31 : 11|3@1+ (1,0) [0|0] "" Vector__XXX
 SG_ VCSEC_TPMSLastLocationSensor2 m31 : 16|3@1+ (1,0) [0|0] "" Vector__XXX
 SG_ VCSEC_TPMSTotalResetsDueToPinReset0 m20 : 16|8@1+ (1,0) [0|0] "" Vector__XXX
 SG_ VCSEC_TPMSTotalResetsDueToPinReset1 m22 : 16|8@1+ (1,0) [0|0] "" Vector__XXX
 SG_ VCSEC_TPMSTotalResetsDueToPinReset2 m24 : 16|8@1+ (1,0) [0|0] "" Vector__XXX
 SG_ VCSEC_TPMSTotalResetsDueToPinReset3 m26 : 16|8@1+ (1,0) [0|0] "" Vector__XXX
 SG_ VCSEC_TPMSTotalResetsDueToWakeupFromShutdown0 m21 : 16|8@1+ (1,0) [0|0] "" Vector__XXX
 SG_ VCSEC_TPMSTotalResetsDueToWakeupFromShutdown1 m23 : 16|8@1+ (1,0) [0|0] "" Vector__XXX
 SG_ VCSEC_TPMSTotalResetsDueToWakeupFromShutdown2 m25 : 16|8@1+ (1,0) [0|0] "" Vector__XXX
 SG_ VCSEC_TPMSTotalResetsDueToWakeupFromShutdown3 m27 : 16|8@1+ (1,0) [0|0] "" Vector__XXX
 SG_ VCSEC_TPMSLastLocationSensor3 m31 : 19|3@1+ (1,0) [0|0] "" Vector__XXX
 SG_ VCSEC_BLEMissedConnEventCount0 m4 : 21|14@1+ (1,0) [0|0] "" Vector__XXX
 SG_ VCSEC_BLEMissedConnEventCount1 m5 : 21|14@1+ (1,0) [0|0] "" Vector__XXX
 SG_ VCSEC_BLEMissedConnEventCount2 m6 : 21|14@1+ (1,0) [0|0] "" Vector__XXX
 SG_ VCSEC_BLEMissedConnEventCount3 m7 : 21|14@1+ (1,0) [0|0] "" Vector__XXX
 SG_ VCSEC_TPMSTotalResetsDueToVDDSLoss0 m20 : 24|8@1+ (1,0) [0|0] "" Vector__XXX
 SG_ VCSEC_TPMSTotalResetsDueToVDDSLoss1 m22 : 24|8@1+ (1,0) [0|0] "" Vector__XXX
 SG_ VCSEC_TPMSTotalResetsDueToVDDSLoss2 m24 : 24|8@1+ (1,0) [0|0] "" Vector__XXX
 SG_ VCSEC_TPMSTotalResetsDueToVDDSLoss3 m26 : 24|8@1+ (1,0) [0|0] "" Vector__XXX
 SG_ VCSEC_TPMSTotalResetsDueToWakeupFromTCKNoise0 m21 : 24|8@1+ (1,0) [0|0] "" Vector__XXX
 SG_ VCSEC_TPMSTotalResetsDueToWakeupFromTCKNoise1 m23 : 24|8@1+ (1,0) [0|0] "" Vector__XXX
 SG_ VCSEC_TPMSTotalResetsDueToWakeupFromTCKNoise2 m25 : 24|8@1+ (1,0) [0|0] "" Vector__XXX
 SG_ VCSEC_TPMSTotalResetsDueToWakeupFromTCKNoise3 m27 : 24|8@1+ (1,0) [0|0] "" Vector__XXX
 SG_ VCSEC_TPMSTotalResetsDueToDCI0 m21 : 32|8@1+ (1,0) [0|0] "" Vector__XXX
 SG_ VCSEC_TPMSTotalResetsDueToDCI1 m23 : 32|8@1+ (1,0) [0|0] "" Vector__XXX
 SG_ VCSEC_TPMSTotalResetsDueToDCI2 m25 : 32|8@1+ (1,0) [0|0] "" Vector__XXX
 SG_ VCSEC_TPMSTotalResetsDueToDCI3 m27 : 32|8@1+ (1,0) [0|0] "" Vector__XXX
 SG_ VCSEC_TPMSTotalResetsDueToVDDLoss0 m20 : 32|8@1+ (1,0) [0|0] "" Vector__XXX
 SG_ VCSEC_TPMSTotalResetsDueToVDDLoss1 m22 : 32|8@1+ (1,0) [0|0] "" Vector__XXX
 SG_ VCSEC_TPMSTotalResetsDueToVDDLoss2 m24 : 32|8@1+ (1,0) [0|0] "" Vector__XXX
 SG_ VCSEC_TPMSTotalResetsDueToVDDLoss3 m26 : 32|8@1+ (1,0) [0|0] "" Vector__XXX
 SG_ VCSEC_BLECRCErrorConnEventCount0 m4 : 35|14@1+ (1,0) [0|0] "" Vector__XXX
 SG_ VCSEC_BLECRCErrorConnEventCount1 m5 : 35|14@1+ (1,0) [0|0] "" Vector__XXX
 SG_ VCSEC_BLECRCErrorConnEventCount2 m6 : 35|14@1+ (1,0) [0|0] "" Vector__XXX
 SG_ VCSEC_BLECRCErrorConnEventCount3 m7 : 35|14@1+ (1,0) [0|0] "" Vector__XXX
 SG_ VCSEC_TPMSSensor1Hash m29 : 36|28@1+ (1,0) [0|0] "" Vector__XXX
 SG_ VCSEC_TPMSSensor3Hash m30 : 36|28@1+ (1,0) [0|0] "" Vector__XXX
 SG_ VCSEC_TPMSAuthenticateSensorState0 m12 : 40|3@1+ (1,0) [0|0] "" Vector__XXX
 SG_ VCSEC_TPMSAuthenticateSensorState1 m13 : 40|3@1+ (1,0) [0|0] "" Vector__XXX
 SG_ VCSEC_TPMSAuthenticateSensorState2 m14 : 40|3@1+ (1,0) [0|0] "" Vector__XXX
 SG_ VCSEC_TPMSAuthenticateSensorState3 m15 : 40|3@1+ (1,0) [0|0] "" Vector__XXX
 SG_ VCSEC_TPMSSensorMLXAppCRC0 m8 : 40|24@1+ (1,0) [0|0] "" Vector__XXX
 SG_ VCSEC_TPMSSensorMLXAppCRC1 m9 : 40|24@1+ (1,0) [0|0] "" Vector__XXX
 SG_ VCSEC_TPMSSensorMLXAppCRC2 m10 : 40|24@1+ (1,0) [0|0] "" Vector__XXX
 SG_ VCSEC_TPMSSensorMLXAppCRC3 m11 : 40|24@1+ (1,0) [0|0] "" Vector__XXX
 SG_ VCSEC_TPMSTotalResetsDueToCoreLockup0 m21 : 40|8@1+ (1,0) [0|0] "" Vector__XXX
 SG_ VCSEC_TPMSTotalResetsDueToCoreLockup1 m23 : 40|8@1+ (1,0) [0|0] "" Vector__XXX
 SG_ VCSEC_TPMSTotalResetsDueToCoreLockup2 m25 : 40|8@1+ (1,0) [0|0] "" Vector__XXX
 SG_ VCSEC_TPMSTotalResetsDueToCoreLockup3 m27 : 40|8@1+ (1,0) [0|0] "" Vector__XXX
 SG_ VCSEC_TPMSTotalResetsDueToVDDRLoss0 m20 : 40|8@1+ (1,0) [0|0] "" Vector__XXX
 SG_ VCSEC_TPMSTotalResetsDueToVDDRLoss1 m22 : 40|8@1+ (1,0) [0|0] "" Vector__XXX
 SG_ VCSEC_TPMSTotalResetsDueToVDDRLoss2 m24 : 40|8@1+ (1,0) [0|0] "" Vector__XXX
 SG_ VCSEC_TPMSTotalResetsDueToVDDRLoss3 m26 : 40|8@1+ (1,0) [0|0] "" Vector__XXX
 SG_ VCSEC_TPMSTrimAdjusted0 m16 : 40|1@1+ (1,0) [0|0] "" Vector__XXX
 SG_ VCSEC_TPMSTrimAdjusted1 m17 : 40|1@1+ (1,0) [0|0] "" Vector__XXX
 SG_ VCSEC_TPMSTrimAdjusted2 m18 : 40|1@1+ (1,0) [0|0] "" Vector__XXX
 SG_ VCSEC_TPMSTrimAdjusted3 m19 : 40|1@1+ (1,0) [0|0] "" Vector__XXX
 SG_ VCSEC_TPMSGenealogySensorState0 m16 : 41|3@1+ (1,0) [0|0] "" Vector__XXX
 SG_ VCSEC_TPMSGenealogySensorState1 m17 : 41|3@1+ (1,0) [0|0] "" Vector__XXX
 SG_ VCSEC_TPMSGenealogySensorState2 m18 : 41|3@1+ (1,0) [0|0] "" Vector__XXX
 SG_ VCSEC_TPMSGenealogySensorState3 m19 : 41|3@1+ (1,0) [0|0] "" Vector__XXX
 SG_ VCSEC_TPMSAuthenticateFailureReason0 m12 : 43|3@1+ (1,0) [0|0] "" Vector__XXX
 SG_ VCSEC_TPMSAuthenticateFailureReason1 m13 : 43|3@1+ (1,0) [0|0] "" Vector__XXX
 SG_ VCSEC_TPMSAuthenticateFailureReason2 m14 : 43|3@1+ (1,0) [0|0] "" Vector__XXX
 SG_ VCSEC_TPMSAuthenticateFailureReason3 m15 : 43|3@1+ (1,0) [0|0] "" Vector__XXX
 SG_ VCSEC_TPMSSensorType0 m16 : 44|3@1+ (1,0) [0|0] "" Vector__XXX
 SG_ VCSEC_TPMSSensorType1 m17 : 44|3@1+ (1,0) [0|0] "" Vector__XXX
 SG_ VCSEC_TPMSSensorType2 m18 : 44|3@1+ (1,0) [0|0] "" Vector__XXX
 SG_ VCSEC_TPMSSensorType3 m19 : 44|3@1+ (1,0) [0|0] "" Vector__XXX
 SG_ VCSEC_TPMSDetailedAuthenticationStatus0 m12 : 48|4@1+ (1,0) [0|0] "" Vector__XXX
 SG_ VCSEC_TPMSDetailedAuthenticationStatus1 m13 : 48|4@1+ (1,0) [0|0] "" Vector__XXX
 SG_ VCSEC_TPMSDetailedAuthenticationStatus2 m14 : 48|4@1+ (1,0) [0|0] "" Vector__XXX
 SG_ VCSEC_TPMSDetailedAuthenticationStatus3 m15 : 48|4@1+ (1,0) [0|0] "" Vector__XXX
 SG_ VCSEC_TPMSTotalResetsDueToClockLoss0 m20 : 48|8@1+ (1,0) [0|0] "" Vector__XXX
 SG_ VCSEC_TPMSTotalResetsDueToClockLoss1 m22 : 48|8@1+ (1,0) [0|0] "" Vector__XXX
 SG_ VCSEC_TPMSTotalResetsDueToClockLoss2 m24 : 48|8@1+ (1,0) [0|0] "" Vector__XXX
 SG_ VCSEC_TPMSTotalResetsDueToClockLoss3 m26 : 48|8@1+ (1,0) [0|0] "" Vector__XXX
 SG_ VCSEC_TPMSTotalResetsDueToWatchdog0 m21 : 48|8@1+ (1,0) [0|0] "" Vector__XXX
 SG_ VCSEC_TPMSTotalResetsDueToWatchdog1 m23 : 48|8@1+ (1,0) [0|0] "" Vector__XXX
 SG_ VCSEC_TPMSTotalResetsDueToWatchdog2 m25 : 48|8@1+ (1,0) [0|0] "" Vector__XXX
 SG_ VCSEC_TPMSTotalResetsDueToWatchdog3 m27 : 48|8@1+ (1,0) [0|0] "" Vector__XXX
 SG_ VCSEC_BLEOtherFailuresCount0 m4 : 49|5@1+ (1,0) [0|0] "" Vector__XXX
 SG_ VCSEC_BLEOtherFailuresCount1 m5 : 49|5@1+ (1,0) [0|0] "" Vector__XXX
 SG_ VCSEC_BLEOtherFailuresCount2 m6 : 49|5@1+ (1,0) [0|0] "" Vector__XXX
 SG_ VCSEC_BLEOtherFailuresCount3 m7 : 49|5@1+ (1,0) [0|0] "" Vector__XXX
 SG_ VCSEC_BLEUnsuccessfulConnEventRate0 m4 : 54|10@1+ (0.08,0) [0|0] "" Vector__XXX
 SG_ VCSEC_BLEUnsuccessfulConnEventRate1 m5 : 54|10@1+ (0.08,0) [0|0] "" Vector__XXX
 SG_ VCSEC_BLEUnsuccessfulConnEventRate2 m6 : 54|10@1+ (0.08,0) [0|0] "" Vector__XXX
 SG_ VCSEC_BLEUnsuccessfulConnEventRate3 m7 : 54|10@1+ (0.08,0) [0|0] "" Vector__XXX
 SG_ VCSEC_TPMSTotalResetsDueToSystemReset0 m20 : 56|8@1+ (1,0) [0|0] "" Vector__XXX
 SG_ VCSEC_TPMSTotalResetsDueToSystemReset1 m22 : 56|8@1+ (1,0) [0|0] "" Vector__XXX
 SG_ VCSEC_TPMSTotalResetsDueToSystemReset2 m24 : 56|8@1+ (1,0) [0|0] "" Vector__XXX
 SG_ VCSEC_TPMSTotalResetsDueToSystemReset3 m26 : 56|8@1+ (1,0) [0|0] "" Vector__XXX
 SG_ VCSEC_TPMSTotalResetsDueToUnknown0 m21 : 56|8@1+ (1,0) [0|0] "" Vector__XXX
 SG_ VCSEC_TPMSTotalResetsDueToUnknown1 m23 : 56|8@1+ (1,0) [0|0] "" Vector__XXX
 SG_ VCSEC_TPMSTotalResetsDueToUnknown2 m25 : 56|8@1+ (1,0) [0|0] "" Vector__XXX
 SG_ VCSEC_TPMSTotalResetsDueToUnknown3 m27 : 56|8@1+ (1,0) [0|0] "" Vector__XXX

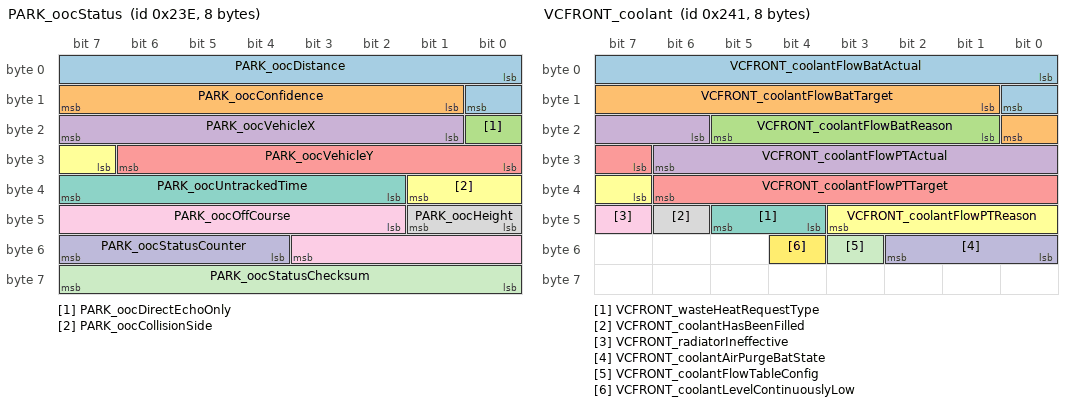
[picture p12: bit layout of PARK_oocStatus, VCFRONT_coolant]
BO_ 574 PARK_oocStatus: 8 Vector__XXX
 SG_ PARK_oocDistance : 0|9@1+ (1,0) [0|0] "" Vector__XXX
 SG_ PARK_oocConfidence : 9|7@1+ (1,0) [0|0] "" Vector__XXX
 SG_ PARK_oocDirectEchoOnly : 16|1@1+ (1,0) [0|0] "" Vector__XXX
 SG_ PARK_oocVehicleX : 17|7@1+ (4,-114) [0|0] "" Vector__XXX
 SG_ PARK_oocVehicleY : 24|7@1+ (2,-128) [0|0] "" Vector__XXX
 SG_ PARK_oocCollisionSide : 31|3@1+ (1,0) [0|0] "" Vector__XXX
 SG_ PARK_oocUntrackedTime : 34|6@1+ (0.1,0) [0|0] "" Vector__XXX
 SG_ PARK_oocHeight : 40|2@1+ (1,0) [0|0] "" Vector__XXX
 SG_ PARK_oocOffCourse : 42|10@1+ (1,-512) [0|0] "" Vector__XXX
 SG_ PARK_oocStatusCounter : 52|4@1+ (1,0) [0|0] "" Vector__XXX
 SG_ PARK_oocStatusChecksum : 56|8@1+ (1,0) [0|0] "" Vector__XXX

BO_ 577 VCFRONT_coolant: 8 Vector__XXX
 SG_ VCFRONT_coolantFlowBatActual : 0|9@1+ (0.1,0) [0|0] "" Vector__XXX
 SG_ VCFRONT_coolantFlowBatTarget : 9|8@1+ (0.2,0) [0|0] "" Vector__XXX
 SG_ VCFRONT_coolantFlowBatReason : 17|5@1+ (1,0) [0|0] "" Vector__XXX
 SG_ VCFRONT_coolantFlowPTActual : 22|9@1+ (0.1,0) [0|0] "" Vector__XXX
 SG_ VCFRONT_coolantFlowPTTarget : 31|8@1+ (0.2,0) [0|0] "" Vector__XXX
 SG_ VCFRONT_coolantFlowPTReason : 39|5@1+ (1,0) [0|0] "" Vector__XXX
 SG_ VCFRONT_wasteHeatRequestType : 44|2@1+ (1,0) [0|0] "" Vector__XXX
 SG_ VCFRONT_coolantHasBeenFilled : 46|1@1+ (1,0) [0|0] "" Vector__XXX
 SG_ VCFRONT_radiatorIneffective : 47|1@1+ (1,0) [0|0] "" Vector__XXX
 SG_ VCFRONT_coolantAirPurgeBatState : 48|3@1+ (1,0) [0|0] "" Vector__XXX
 SG_ VCFRONT_coolantFlowTableConfig : 51|1@1+ (1,0) [0|0] "" Vector__XXX
 SG_ VCFRONT_coolantLevelContinuouslyLow : 52|1@1+ (1,0) [0|0] "" Vector__XXX

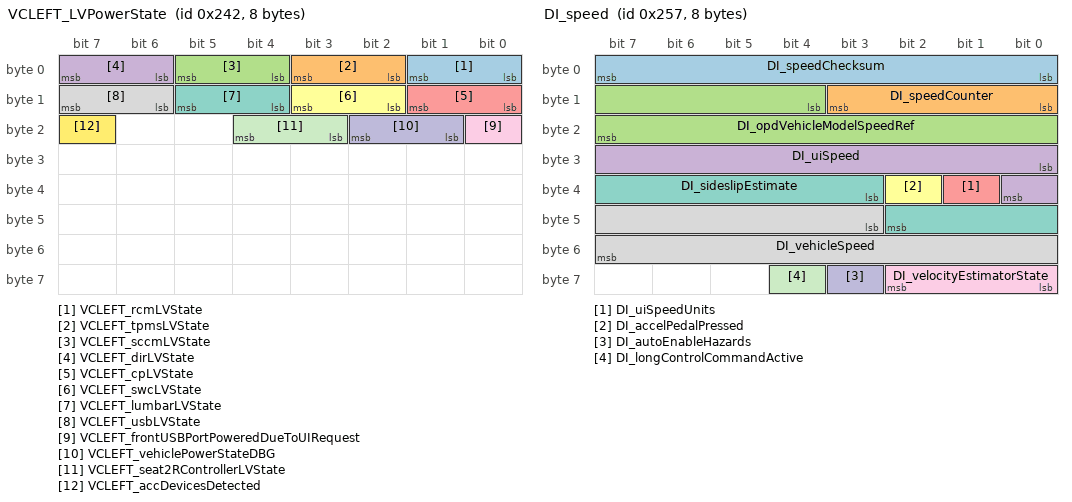
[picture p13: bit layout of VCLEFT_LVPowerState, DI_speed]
BO_ 578 VCLEFT_LVPowerState: 8 Vector__XXX
 SG_ VCLEFT_rcmLVState : 0|2@1+ (1,0) [0|0] "" Vector__XXX
 SG_ VCLEFT_tpmsLVState : 2|2@1+ (1,0) [0|0] "" Vector__XXX
 SG_ VCLEFT_sccmLVState : 4|2@1+ (1,0) [0|0] "" Vector__XXX
 SG_ VCLEFT_dirLVState : 6|2@1+ (1,0) [0|0] "" Vector__XXX
 SG_ VCLEFT_cpLVState : 8|2@1+ (1,0) [0|0] "" Vector__XXX
 SG_ VCLEFT_swcLVState : 10|2@1+ (1,0) [0|0] "" Vector__XXX
 SG_ VCLEFT_lumbarLVState : 12|2@1+ (1,0) [0|0] "" Vector__XXX
 SG_ VCLEFT_usbLVState : 14|2@1+ (1,0) [0|0] "" Vector__XXX
 SG_ VCLEFT_frontUSBPortPoweredDueToUIRequest : 16|1@1+ (1,0) [0|0] "" Vector__XXX
 SG_ VCLEFT_vehiclePowerStateDBG : 17|2@1+ (1,0) [0|0] "" Vector__XXX
 SG_ VCLEFT_seat2RControllerLVState : 19|2@1+ (1,0) [0|0] "" Vector__XXX
 SG_ VCLEFT_accDevicesDetected : 23|1@1+ (1,0) [0|0] "" Vector__XXX

BO_ 579 VCRIGHT_hvacStatus: 8 Vector__XXX
 SG_ VCRIGHT_hvacStatusIndex M : 0|3@1+ (1,0) [0|0] "" Vector__XXX
 SG_ VCRIGHT_hvacFrontRightSeatHeatStatus m3 : 4|2@1+ (1,0) [0|0] "" Vector__XXX
 SG_ VCRIGHT_hvacSeatFrontLeftTempTarget m3 : 6|8@1+ (0.5,-40) [0|0] "" Vector__XXX
 SG_ VCRIGHT_autoSwingAvailable m4 : 9|1@1+ (1,0) [0|0] "" Vector__XXX
 SG_ VCRIGHT_enableTripleCameraFanPowerInSleep m2 : 9|1@1+ (1,0) [0|0] "" Vector__XXX
 SG_ VCRIGHT_foggingControllerResetReason m5 : 9|15@1+ (1,0) [0|0] "" Vector__XXX
 SG_ VCRIGHT_hvacRecircDoorPercent m1 : 10|6@1+ (1.6,0) [0|0] "" Vector__XXX
 SG_ VCRIGHT_tempDuctLeftUpper m4 : 10|8@1+ (0.5,-22) [0|0] "" Vector__XXX
 SG_ VCRIGHT_tempDuctRightUpper m2 : 10|8@1+ (0.5,-22) [0|0] "" Vector__XXX
 SG_ VCRIGHT_warmingUpStatus m0 : 10|5@1+ (3,7) [0|0] "" Vector__XXX
 SG_ VCRIGHT_hvacManualToAutoNotify m3 : 14|3@1+ (1,0) [0|0] "" Vector__XXX
 SG_ VCRIGHT_coolingDownStatus m0 : 15|5@1+ (3,7) [0|0] "" Vector__XXX
 SG_ VCRIGHT_tempDuctLeft m1 : 16|8@1+ (0.5,-22) [0|0] "" Vector__XXX
 SG_ VCRIGHT_hvacRequestsFullAuto m3 : 17|3@1+ (1,0) [0|0] "" Vector__XXX
 SG_ VCRIGHT_hpSplitTempsEnabled m2 : 18|1@1+ (1,0) [0|0] "" Vector__XXX
 SG_ VCRIGHT_hvacFrontLeftSeatHeatStatus m4 : 18|2@1+ (1,0) [0|0] "" Vector__XXX
 SG_ VCRIGHT_hvacEvapInletTempEstimate m2 : 19|10@1+ (0.13,-40) [0|0] "" Vector__XXX
 SG_ VCRIGHT_childModeHVACState m0 : 20|2@1+ (1,0) [0|0] "" Vector__XXX
 SG_ VCRIGHT_hvacQdotLeft m4 : 20|14@1+ (1,-8191) [0|0] "" Vector__XXX
 SG_ VCRIGHT_passengerPresentHvacCycle m3 : 21|1@1+ (1,0) [0|0] "" Vector__XXX
 SG_ VCRIGHT_dogModeState m0 : 22|4@1+ (1,0) [0|0] "" Vector__XXX
 SG_ VCRIGHT_hvacRequestsAutoIntake m3 : 22|1@1+ (1,0) [0|0] "" Vector__XXX
 SG_ VCRIGHT_hvacMassflowRefrigSystem m1 : 24|8@1+ (1,0) [0|0] "" Vector__XXX
 SG_ VCRIGHT_steeringWheelHeatStatus m3 : 24|2@1+ (1,0) [0|0] "" Vector__XXX
 SG_ VCRIGHT_autoDefogStatus m3 : 26|2@1+ (1,0) [0|0] "" Vector__XXX
 SG_ VCRIGHT_hvacCabinTempEstValid m0 : 26|1@1+ (1,0) [0|0] "" Vector__XXX
 SG_ VCRIGHT_COPNotRunningReasonFiltered m0 : 27|3@1+ (1,0) [0|0] "" Vector__XXX
 SG_ VCRIGHT_tempMonitorNotNominal m2 : 29|1@1+ (1,0) [0|0] "" Vector__XXX
 SG_ VCRIGHT_hvacCabinAtTempTarget m2 : 30|1@1+ (1,0) [0|0] "" Vector__XXX
 SG_ VCRIGHT_hvacCabinTempEst m0 : 30|11@1+ (0.1,-40) [0|0] "" Vector__XXX
 SG_ VCRIGHT_solarElevation m3 : 31|9@1- (0.5,0) [0|0] "" Vector__XXX
 SG_ VCRIGHT_blowerTorqueIndex m5 : 32|7@1+ (1,0) [0|0] "" Vector__XXX
 SG_ VCRIGHT_hvacAirflowReason m2 : 32|5@1+ (1,0) [0|0] "" Vector__XXX
 SG_ VCRIGHT_tempDuctRight m1 : 32|8@1+ (0.5,-22) [0|0] "" Vector__XXX
 SG_ VCRIGHT_hvacQdotRight m4 : 34|14@1+ (1,-8191) [0|0] "" Vector__XXX
 SG_ VCRIGHT_autoHvacBlowerShouldLimit m2 : 37|1@1+ (1,0) [0|0] "" Vector__XXX
 SG_ VCRIGHT_minsToSunrise m3 : 40|8@1+ (10,0) [0|0] "" Vector__XXX
 SG_ VCRIGHT_solarLoadOnVehicle m2 : 40|8@1+ (4,0) [0|0] "" Vector__XXX
 SG_ VCRIGHT_hvacAirDistributionMode m0 : 41|3@1+ (1,0) [0|0] "" Vector__XXX
 SG_ VCRIGHT_hvacBlowerSegment m0 : 44|4@1+ (1,0) [0|0] "" Vector__XXX
 SG_ VCRIGHT_hvacDuctTargetLeft m1 : 48|8@1+ (0.5,-40) [0|0] "" Vector__XXX
 SG_ VCRIGHT_hvacRecirc m0 : 48|2@1+ (1,0) [0|0] "" Vector__XXX
 SG_ VCRIGHT_minsToSunset m3 : 48|8@1+ (10,0) [0|0] "" Vector__XXX
 SG_ VCRIGHT_refrigDistCommanded m2 : 48|1@1+ (1,0) [0|0] "" Vector__XXX
 SG_ VCRIGHT_tempDuctLeftLower m4 : 48|8@1+ (0.5,-22) [0|0] "" Vector__XXX
 SG_ VCRIGHT_hvacACRunning m0 : 50|1@1+ (1,0) [0|0] "" Vector__XXX
 SG_ VCRIGHT_hvacPowerState m0 : 51|3@1+ (1,0) [0|0] "" Vector__XXX
 SG_ VCRIGHT_hvacRefHighPowerRequest m2 : 53|1@1+ (1,0) [0|0] "" Vector__XXX
 SG_ VCRIGHT_hvacVentStatus m0 : 54|2@1+ (1,0) [0|0] "" Vector__XXX
 SG_ VCRIGHT_hvacDuctTargetRight m1 : 56|8@1+ (0.5,-40) [0|0] "" Vector__XXX
 SG_ VCRIGHT_hvacLimitedReasonRight m3 : 56|3@1+ (1,0) [0|0] "" Vector__XXX
 SG_ VCRIGHT_hvacSecondRowState m0 : 56|3@1+ (1,0) [0|0] "" Vector__XXX
 SG_ VCRIGHT_tempDuctRightLower m4 : 56|8@1+ (0.5,-22) [0|0] "" Vector__XXX
 SG_ VCRIGHT_hvacLimitedReasonLeft m3 : 59|3@1+ (1,0) [0|0] "" Vector__XXX
 SG_ VCRIGHT_hvacSystemNominal m0 : 59|1@1+ (1,0) [0|0] "" Vector__XXX
 SG_ VCRIGHT_hvacModelInitStatus m0 : 60|4@1+ (1,0) [0|0] "" Vector__XXX
 SG_ VCRIGHT_hvacOverheatProtActive m3 : 63|1@1+ (1,0) [0|0] "" Vector__XXX

BO_ 580 FC_limits: 8 Vector__XXX
 SG_ FC_powerLimit : 0|13@1+ (0.062255859376,0) [0|0] "" Vector__XXX
 SG_ FC_currentLimit : 16|13@1+ (0.0732421875,0) [0|0] "" Vector__XXX
 SG_ FC_maxVoltageLimit : 32|13@1+ (0.07324218755,0) [0|0] "" Vector__XXX
 SG_ FC_minVoltageLimit : 48|13@1+ (0.0732421875,0) [0|0] "" Vector__XXX

BO_ 583 CMP_HVStatus: 8 Vector__XXX
 SG_ CMP_inputHVVoltage : 0|16@1+ (0.1,0) [0|0] "" Vector__XXX
 SG_ CMP_inputLVVoltage : 16|8@1+ (0.1,0) [0|0] "" Vector__XXX
 SG_ CMP_inputHVCurrent : 24|16@1+ (0.1,0) [0|0] "" Vector__XXX
 SG_ CMP_inputHVPower : 40|16@1+ (1,0) [0|0] "" Vector__XXX

BO_ 585 SCCM_leftStalk: 8 Vector__XXX
 SG_ SCCM_leftStalkCrc : 0|8@1+ (1,0) [0|0] "" Vector__XXX
 SG_ SCCM_leftStalkCounter : 8|4@1+ (1,0) [0|0] "" Vector__XXX
 SG_ SCCM_highBeamStalkStatus : 12|2@1+ (1,0) [0|0] "" Vector__XXX
 SG_ SCCM_washWipeButtonStatus : 14|2@1+ (1,0) [0|0] "" Vector__XXX
 SG_ SCCM_turnIndicatorStalkStatus : 16|4@1+ (1,0) [0|0] "" Vector__XXX
 SG_ SCCM_turnIndicatorStalkAngle : 20|12@1+ (0.1,-180) [0|0] "" Vector__XXX

BO_ 586 HVP_cpControl: 8 Vector__XXX
 SG_ HVP_cpDoorDriveEnable : 0|1@1+ (1,0) [0|0] "" Vector__XXX
 SG_ HVP_cpLatchDriveHwEnabled : 1|1@1+ (1,0) [0|0] "" Vector__XXX
 SG_ HVP_cpFaultLine : 2|1@1+ (1,0) [0|0] "" Vector__XXX

BO_ 594 BMS_powerAvailable: 8 Vector__XXX
 SG_ BMS_maxRegenPower : 0|16@1+ (0.01,0) [0|0] "" Vector__XXX
 SG_ BMS_maxDischargePower : 16|16@1+ (0.013,0) [0|0] "" Vector__XXX
 SG_ BMS_maxStationaryHeatPower : 32|10@1+ (0.01,0) [0|0] "" Vector__XXX
 SG_ BMS_powerLimitsState : 42|1@1+ (1,0) [0|0] "" Vector__XXX
 SG_ BMS_totalHvPowerBudget : 43|9@1+ (0.1,0) [0|0] "" Vector__XXX
 SG_ BMS_notEnoughPowerForHeatPump : 52|1@1+ (1,0) [0|0] "" Vector__XXX

BO_ 595 UI_ventPanelControlRequest: 8 Vector__XXX
 SG_ UI_ventPanelControlRequestIndex M : 0|1@1+ (1,0) [0|0] "" Vector__XXX
 SG_ UI_ventPanelLeftPositionX m0 : 8|8@1+ (0.5,0) [0|0] "" Vector__XXX
 SG_ UI_ventPanelLeftPositionY m0 : 16|8@1+ (0.5,0) [0|0] "" Vector__XXX
 SG_ UI_ventPanelLeftLateralSplit m0 : 24|8@1+ (0.5,0) [0|0] "" Vector__XXX
 SG_ UI_ventPanelRightPositionX m0 : 32|8@1+ (0.5,0) [0|0] "" Vector__XXX
 SG_ UI_ventPanelRightPositionY m0 : 40|8@1+ (0.5,0) [0|0] "" Vector__XXX
 SG_ UI_ventPanelRightLateralSplit m0 : 48|8@1+ (0.5,0) [0|0] "" Vector__XXX
 SG_ UI_ventPanelLeftLateralMode m0 : 56|2@1+ (1,0) [0|0] "" Vector__XXX
 SG_ UI_ventPanelRightLateralMode m0 : 58|2@1+ (1,0) [0|0] "" Vector__XXX
 SG_ UI_hvacReqActiveVents m0 : 60|2@1+ (1,0) [0|0] "" Vector__XXX

BO_ 599 DI_speed: 8 Vector__XXX
 SG_ DI_speedChecksum : 0|8@1+ (1,0) [0|0] "" Vector__XXX
 SG_ DI_speedCounter : 8|4@1+ (1,0) [0|0] "" Vector__XXX
 SG_ DI_opdVehicleModelSpeedRef : 12|12@1+ (0.08,-40) [0|0] "" Vector__XXX
 SG_ DI_uiSpeed : 24|9@1+ (1,0) [0|0] "" Vector__XXX
 SG_ DI_uiSpeedUnits : 33|1@1+ (1,0) [0|0] "" Vector__XXX
 SG_ DI_accelPedalPressed : 34|1@1+ (1,0) [0|0] "" Vector__XXX
 SG_ DI_sideslipEstimate : 35|8@1- (0.0025,0) [0|0] "" Vector__XXX
 SG_ DI_vehicleSpeed : 43|13@1+ (0.08,-40) [0|0] "" Vector__XXX
 SG_ DI_velocityEstimatorState : 56|3@1+ (1,0) [0|0] "" Vector__XXX
 SG_ DI_autoEnableHazards : 59|1@1+ (1,0) [0|0] "" Vector__XXX
 SG_ DI_longControlCommandActive : 60|1@1+ (1,0) [0|0] "" Vector__XXX

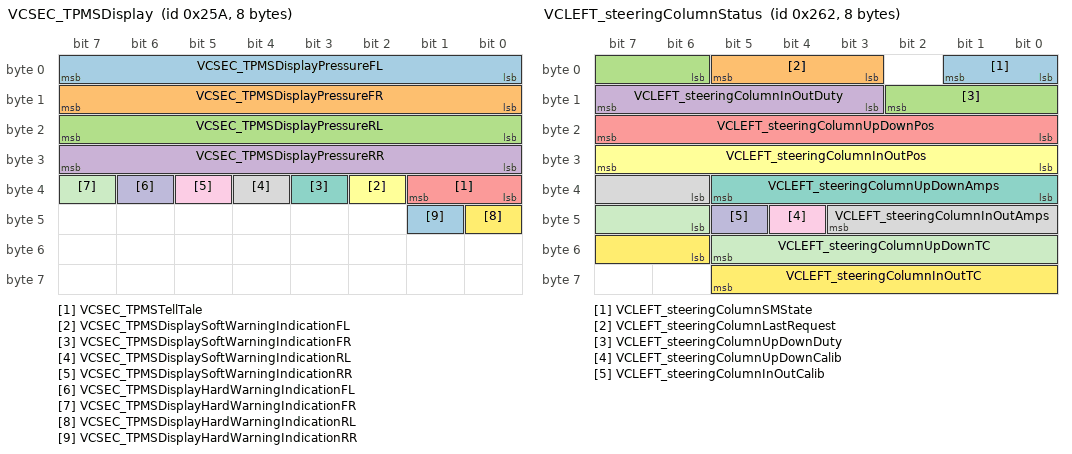
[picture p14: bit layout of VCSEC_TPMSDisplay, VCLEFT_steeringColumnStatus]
BO_ 602 VCSEC_TPMSDisplay: 8 Vector__XXX
 SG_ VCSEC_TPMSDisplayPressureFL : 0|8@1+ (0.025,0) [0|0] "" Vector__XXX
 SG_ VCSEC_TPMSDisplayPressureFR : 8|8@1+ (0.025,0) [0|0] "" Vector__XXX
 SG_ VCSEC_TPMSDisplayPressureRL : 16|8@1+ (0.025,0) [0|0] "" Vector__XXX
 SG_ VCSEC_TPMSDisplayPressureRR : 24|8@1+ (0.025,0) [0|0] "" Vector__XXX
 SG_ VCSEC_TPMSTellTale : 32|2@1+ (1,0) [0|0] "" Vector__XXX
 SG_ VCSEC_TPMSDisplaySoftWarningIndicationFL : 34|1@1+ (1,0) [0|0] "" Vector__XXX
 SG_ VCSEC_TPMSDisplaySoftWarningIndicationFR : 35|1@1+ (1,0) [0|0] "" Vector__XXX
 SG_ VCSEC_TPMSDisplaySoftWarningIndicationRL : 36|1@1+ (1,0) [0|0] "" Vector__XXX
 SG_ VCSEC_TPMSDisplaySoftWarningIndicationRR : 37|1@1+ (1,0) [0|0] "" Vector__XXX
 SG_ VCSEC_TPMSDisplayHardWarningIndicationFL : 38|1@1+ (1,0) [0|0] "" Vector__XXX
 SG_ VCSEC_TPMSDisplayHardWarningIndicationFR : 39|1@1+ (1,0) [0|0] "" Vector__XXX
 SG_ VCSEC_TPMSDisplayHardWarningIndicationRL : 40|1@1+ (1,0) [0|0] "" Vector__XXX
 SG_ VCSEC_TPMSDisplayHardWarningIndicationRR : 41|1@1+ (1,0) [0|0] "" Vector__XXX

BO_ 603 APP_status: 8 Vector__XXX
 SG_ APP_watchdogState : 0|3@1+ (1,0) [0|0] "" Vector__XXX
 SG_ APP_fusedState : 3|2@1+ (1,0) [0|0] "" Vector__XXX
 SG_ APP_cameraHeaterRequest : 5|1@1+ (1,0) [0|0] "" Vector__XXX
 SG_ APP_factorySummonStatus : 6|4@1+ (1,0) [0|0] "" Vector__XXX
 SG_ APP_clipRecordingStatus : 10|3@1+ (1,0) [0|0] "" Vector__XXX
 SG_ APP_allowApActivationWithBrake : 13|1@1+ (1,0) [0|0] "" Vector__XXX
 SG_ APP_summonUnavailableReason : 14|5@1+ (1,0) [0|0] "" Vector__XXX
 SG_ APP_fsdSuspendState : 19|2@1+ (1,0) [0|0] "" Vector__XXX
 SG_ APP_fsdRevokeStrikeoutCount : 21|3@1+ (1,0) [0|0] "" Vector__XXX
 SG_ APP_teslaVisionSupported : 24|2@1+ (1,0) [0|0] "" Vector__XXX
 SG_ APP_teslaVisionUnsupportedReason : 26|3@1+ (1,0) [0|0] "" Vector__XXX
 SG_ APP_fsdRevokeCount : 29|3@1+ (1,0) [0|0] "" Vector__XXX
 SG_ APP_excessiveAccelPedalWarning : 32|1@1+ (1,0) [0|0] "" Vector__XXX
 SG_ APP_unifiedObjectStackSupported : 33|2@1+ (1,0) [0|0] "" Vector__XXX
 SG_ APP_unifiedObjsUnsupportedReason : 35|3@1+ (1,0) [0|0] "" Vector__XXX
 SG_ APP_DDAWSystemStatus : 38|3@1+ (1,0) [0|0] "" Vector__XXX
 SG_ APP_socOperatingMode : 41|2@1+ (1,0) [0|0] "" Vector__XXX
 SG_ APP_summonVersionIdentifier : 43|1@1+ (1,0) [0|0] "" Vector__XXX
 SG_ APP_sentryState : 44|3@1+ (1,0) [0|0] "" Vector__XXX
 SG_ APP_autoparkVersionIdentifier : 47|2@1+ (1,0) [0|0] "" Vector__XXX
 SG_ APP_setSpeedMode : 49|2@1+ (1,0) [0|0] "" Vector__XXX
 SG_ APP_suspendResumeAvailable : 51|1@1+ (1,0) [0|0] "" Vector__XXX
 SG_ APP_statusCounter : 52|4@1+ (1,0) [0|0] "" Vector__XXX
 SG_ APP_statusChecksum : 56|8@1+ (1,0) [0|0] "" Vector__XXX

BO_ 605 CP_status: 8 Vector__XXX
 SG_ CP_type : 0|2@1+ (1,0) [0|0] "" Vector__XXX
 SG_ CP_insertEnableLine : 2|1@1+ (1,0) [0|0] "" Vector__XXX
 SG_ CP_latchState : 3|2@1+ (1,0) [0|0] "" Vector__XXX
 SG_ CP_permanentPowerRequest : 5|1@1+ (1,0) [0|0] "" Vector__XXX
 SG_ CP_chargeDoorOpen : 6|1@1+ (1,0) [0|0] "" Vector__XXX
 SG_ CP_doorControlState : 8|3@1+ (1,0) [0|0] "" Vector__XXX
 SG_ CP_doorButtonPressed : 11|1@1+ (1,0) [0|0] "" Vector__XXX
 SG_ CP_swcanRelayClosed : 12|1@1+ (1,0) [0|0] "" Vector__XXX
 SG_ CP_inhibitOta : 13|1@1+ (1,0) [0|0] "" Vector__XXX
 SG_ CP_chargeCableState : 14|2@1+ (1,0) [0|0] "" Vector__XXX
 SG_ CP_latchControlState : 16|3@1+ (1,0) [0|0] "" Vector__XXX
 SG_ CP_ledColor : 19|4@1+ (1,0) [0|0] "" Vector__XXX
 SG_ CP_UHF_handleFound : 23|1@1+ (1,0) [0|0] "" Vector__XXX
 SG_ CP_faultLineSensed : 24|1@1+ (1,0) [0|0] "" Vector__XXX
 SG_ CP_doorPresenceState : 25|3@1+ (1,0) [0|0] "" Vector__XXX
 SG_ CP_inductiveSensorState : 28|3@1+ (1,0) [0|0] "" Vector__XXX
 SG_ CP_chargeDoorOpenUI : 31|1@1+ (1,0) [0|0] "" Vector__XXX
 SG_ CP_vehicleUnlockRequest : 32|1@1+ (1,0) [0|0] "" Vector__XXX
 SG_ CP_coldWeatherMode : 33|1@1+ (1,0) [0|0] "" Vector__XXX
 SG_ CP_latchEngaged : 34|1@1+ (1,0) [0|0] "" Vector__XXX
 SG_ CP_inletHeaterUiState : 37|3@1+ (1,0) [0|0] "" Vector__XXX
 SG_ CP_userEvseModelType : 40|4@1+ (1,0) [0|0] "" Vector__XXX
 SG_ CP_evseGridFormHardwareType : 44|4@1+ (1,0) [0|0] "" Vector__XXX

BO_ 609 VCFRONT_12VBatteryStatus: 8 Vector__XXX
 SG_ VCFRONT_12VBatteryStatusIndex M : 0|3@1+ (1,0) [0|0] "" Vector__XXX
 SG_ VCFRONT_12VBatteryTargetVoltage m2 : 3|13@1+ (0.01,0) [0|0] "" Vector__XXX
 SG_ VCFRONT_IBSFault m0 : 3|1@1+ (1,0) [0|0] "" Vector__XXX
 SG_ VCFRONT_IBSVoltageFiltered m3 : 3|14@1+ (0.005443676098,0) [0|0] "" Vector__XXX
 SG_ VCFRONT_batterySupportRequest m1 : 3|1@1+ (1,0) [0|0] "" Vector__XXX
 SG_ VCFRONT_targetCurrent m5 : 3|11@1+ (0.125,-127) [0|0] "" Vector__XXX
 SG_ VCFRONT_voltageProfile m4 : 3|2@1+ (1,0) [0|0] "" Vector__XXX
 SG_ VCFRONT_12VOverchargeCounter m0 : 4|4@1+ (1,0) [0|0] "" Vector__XXX
 SG_ VCFRONT_batterySMState m1 : 4|4@1+ (1,0) [0|0] "" Vector__XXX
 SG_ VCFRONT_IBSAmpHours m4 : 5|14@1- (0.005,0) [0|0] "" Vector__XXX
 SG_ VCFRONT_eFuseRecoveryStateDBG m1 : 8|3@1+ (1,0) [0|0] "" Vector__XXX
 SG_ VCFRONT_voltageDropCounter m0 : 8|4@1+ (1,0) [0|0] "" Vector__XXX
 SG_ VCFRONT_batteryLINScheduleDBG m1 : 11|3@1+ (1,0) [0|0] "" Vector__XXX
 SG_ VCFRONT_isVehicleSupported m0 : 12|1@1+ (1,0) [0|0] "" Vector__XXX
 SG_ VCFRONT_shortedCellFaultCounter m0 : 13|3@1+ (1,0) [0|0] "" Vector__XXX
 SG_ VCFRONT_PCSMia m5 : 14|1@1+ (1,0) [0|0] "" Vector__XXX
 SG_ VCFRONT_resistanceEstimationTestCounter m1 : 14|2@1+ (1,0) [0|0] "" Vector__XXX
 SG_ VCFRONT_chargeNeeded m5 : 15|1@1+ (1,0) [0|0] "" Vector__XXX
 SG_ VCFRONT_IBSCurrent m1 : 16|16@1- (0.005,0) [0|0] "" Vector__XXX
 SG_ VCFRONT_IBSCurrentFiltered m0 : 16|16@1- (0.005,0) [0|0] "" Vector__XXX
 SG_ VCFRONT_IBSTemperature m2 : 16|11@1+ (0.1,-24) [0|0] "" Vector__XXX
 SG_ VCFRONT_voltageControlLoopIntegrationVal m5 : 16|14@1+ (0.006,0) [0|0] "" Vector__XXX
 SG_ VCFRONT_LVBMS_LVBusVoltageSourceDBG m3 : 17|2@1+ (1,0) [0|0] "" Vector__XXX
 SG_ VCFRONT_IBSVoltageRawDBG m4 : 19|14@1+ (0.005443676098,0) [0|0] "" Vector__XXX
 SG_ VCFRONT_LVBMS_LVPackCurrentSourceDBG m3 : 19|2@1+ (1,0) [0|0] "" Vector__XXX
 SG_ VCFRONT_LVBatterySupportRqrdTrigger m3 : 24|14@1+ (1,0) [0|0] "" Vector__XXX
 SG_ VCFRONT_currentSensorMismatchLeakyBktPctDBG m2 : 27|7@1+ (2,0) [0|0] "" Vector__XXX
 SG_ VCFRONT_currentControlLoopIntegrationVal m5 : 30|14@1+ (0.006,0) [0|0] "" Vector__XXX
 SG_ VCFRONT_IBSVoltage m1 : 32|14@1+ (0.005443676098,0) [0|0] "" Vector__XXX
 SG_ VCFRONT_silentWakeIBSCurrent m0 : 32|12@1+ (0.125,-511.875) [0|0] "" Vector__XXX
 SG_ VCFRONT_LVBatteryLINCommsDetectedDBG m4 : 33|1@1+ (1,0) [0|0] "" Vector__XXX
 SG_ VCFRONT_voltageSensorMismatchLeakyBktPctDBG m4 : 34|7@1+ (2,0) [0|0] "" Vector__XXX
 SG_ VCFRONT_LVBatteryEnergyRemainingPCT m2 : 37|7@1+ (1,0) [0|0] "" Vector__XXX
 SG_ VCFRONT_goodForPCSPowerCycleLeakyBktDBG m3 : 40|5@1+ (0.0005,0) [0|0] "" Vector__XXX
 SG_ VCFRONT_LVBusControlMode m4 : 41|4@1+ (1,0) [0|0] "" Vector__XXX
 SG_ VCFRONT_LVBatteryStatusForDrive m2 : 44|2@1+ (1,0) [0|0] "" Vector__XXX
 SG_ VCFRONT_firstChargeOTA m0 : 44|1@1+ (1,0) [0|0] "" Vector__XXX
 SG_ VCFRONT_LVBusControlsFutile m3 : 45|1@1+ (1,0) [0|0] "" Vector__XXX
 SG_ VCFRONT_firstChargePOR m0 : 45|1@1+ (1,0) [0|0] "" Vector__XXX
 SG_ VCFRONT_good12VforUpdate : 46|1@1+ (1,0) [0|0] "" Vector__XXX
 SG_ VCFRONT_LVLoadRequest : 47|1@1+ (1,0) [0|0] "" Vector__XXX
 SG_ VCFRONT_LVBatteryType m2 : 48|3@1+ (1,0) [0|0] "" Vector__XXX
 SG_ VCFRONT_resistanceEstimationTestValid m3 : 48|1@1+ (1,0) [0|0] "" Vector__XXX
 SG_ VCFRONT_reverseBatteryFault m1 : 48|1@1+ (1,0) [0|0] "" Vector__XXX
 SG_ VCFRONT_voltageFloorReachedCounter m0 : 48|4@1+ (1,0) [0|0] "" Vector__XXX
 SG_ VCFRONT_LVBatterySupported m1 : 49|1@1+ (1,0) [0|0] "" Vector__XXX
 SG_ VCFRONT_resistanceEstimationTestsExpended m3 : 49|1@1+ (1,0) [0|0] "" Vector__XXX
 SG_ VCFRONT_LVBatteryCannotSupportVehicle m1 : 50|1@1+ (1,0) [0|0] "" Vector__XXX
 SG_ VCFRONT_LVBatteryFctryLimOverrideOk m4 : 50|1@1+ (1,0) [0|0] "" Vector__XXX
 SG_ VCFRONT_goodLVChargeForUpdate m3 : 50|1@1+ (1,0) [0|0] "" Vector__XXX
 SG_ VCFRONT_LVBatterySPICommsDetectedDBG m4 : 51|1@1+ (1,0) [0|0] "" Vector__XXX
 SG_ VCFRONT_goodTemp12VforUpdate m1 : 51|1@1+ (1,0) [0|0] "" Vector__XXX
 SG_ VCFRONT_opportunisticDCRTestNeeded m3 : 51|1@1+ (1,0) [0|0] "" Vector__XXX
 SG_ VCFRONT_resistanceEstimationNeeded m2 : 51|1@1+ (1,0) [0|0] "" Vector__XXX
 SG_ VCFRONT_12VBatteryStatusCounter : 52|4@1+ (1,0) [0|0] "" Vector__XXX
 SG_ VCFRONT_12VBatteryStatusChecksum : 56|8@1+ (1,0) [0|0] "" Vector__XXX

BO_ 610 VCLEFT_steeringColumnStatus: 8 Vector__XXX
 SG_ VCLEFT_steeringColumnSMState : 0|2@1+ (1,0) [0|0] "" Vector__XXX
 SG_ VCLEFT_steeringColumnLastRequest : 3|3@1+ (1,0) [0|0] "" Vector__XXX
 SG_ VCLEFT_steeringColumnUpDownDuty : 6|5@1- (7,0) [0|0] "" Vector__XXX
 SG_ VCLEFT_steeringColumnInOutDuty : 11|5@1- (7,0) [0|0] "" Vector__XXX
 SG_ VCLEFT_steeringColumnUpDownPos : 16|8@1- (1,103) [0|0] "" Vector__XXX
 SG_ VCLEFT_steeringColumnInOutPos : 24|8@1- (1,103) [0|0] "" Vector__XXX
 SG_ VCLEFT_steeringColumnUpDownAmps : 32|6@1- (0.63,0) [0|0] "" Vector__XXX
 SG_ VCLEFT_steeringColumnInOutAmps : 38|6@1- (0.63,0) [0|0] "" Vector__XXX
 SG_ VCLEFT_steeringColumnUpDownCalib : 44|1@1+ (1,0) [0|0] "" Vector__XXX
 SG_ VCLEFT_steeringColumnInOutCalib : 45|1@1+ (1,0) [0|0] "" Vector__XXX
 SG_ VCLEFT_steeringColumnUpDownTC : 46|8@1+ (0.5,-10) [0|0] "" Vector__XXX
 SG_ VCLEFT_steeringColumnInOutTC : 54|8@1+ (0.5,-10) [0|0] "" Vector__XXX

BO_ 611 VCRIGHT_logging10Hz: 8 Vector__XXX
 SG_ VCRIGHT_logging10HzIndex M : 0|3@1+ (1,0) [0|0] "" Vector__XXX
 SG_ VCRIGHT_hvacLHBleedActuatorState m2 : 3|2@1+ (1,0) [0|0] "" Vector__XXX
 SG_ VCRIGHT_hvacLHBleedPosition m1 : 3|8@1+ (0.4,0) [0|0] "" Vector__XXX
 SG_ VCRIGHT_hvacLHBleedTarget m0 : 3|8@1+ (0.4,0) [0|0] "" Vector__XXX
 SG_ VCRIGHT_hvacRHBleedActuatorState m2 : 5|2@1+ (1,0) [0|0] "" Vector__XXX
 SG_ VCRIGHT_hvacLHVaneActuatorState m2 : 8|2@1+ (1,0) [0|0] "" Vector__XXX
 SG_ VCRIGHT_hvacRHVaneActuatorState m2 : 10|2@1+ (1,0) [0|0] "" Vector__XXX
 SG_ VCRIGHT_hvacRHBleedPosition m1 : 11|8@1+ (0.4,0) [0|0] "" Vector__XXX
 SG_ VCRIGHT_hvacRHBleedTarget m0 : 11|8@1+ (0.4,0) [0|0] "" Vector__XXX
 SG_ VCRIGHT_hvacUpperModeActState m2 : 12|2@1+ (1,0) [0|0] "" Vector__XXX
 SG_ VCRIGHT_hvacLowerModeActState m2 : 14|2@1+ (1,0) [0|0] "" Vector__XXX
 SG_ VCRIGHT_hvacIntakeActuatorState m2 : 16|2@1+ (1,0) [0|0] "" Vector__XXX
 SG_ VCRIGHT_hvacLHVanePosition m1 : 19|8@1+ (0.4,0) [0|0] "" Vector__XXX
 SG_ VCRIGHT_hvacLHVaneTarget m0 : 19|8@1+ (0.4,0) [0|0] "" Vector__XXX
 SG_ VCRIGHT_EvapPulldownBiasActive m2 : 20|1@1+ (1,0) [0|0] "" Vector__XXX
 SG_ VCRIGHT_tempDatLeftEst m2 : 21|9@1+ (0.5,-22) [0|0] "" Vector__XXX
 SG_ VCRIGHT_hvacRHVanePosition m1 : 27|8@1+ (0.4,0) [0|0] "" Vector__XXX
 SG_ VCRIGHT_hvacRHVaneTarget m0 : 27|8@1+ (0.4,0) [0|0] "" Vector__XXX
 SG_ VCRIGHT_tempDatRightEst m2 : 30|9@1+ (0.5,-22) [0|0] "" Vector__XXX
 SG_ VCRIGHT_hvacUpperModePosition m1 : 35|10@1+ (0.1,0) [0|0] "" Vector__XXX
 SG_ VCRIGHT_hvacUpperModeTarget m0 : 35|10@1+ (0.1,0) [0|0] "" Vector__XXX
 SG_ VCRIGHT_frontLeftSeatTempTargetQuasiSS m4 : 36|6@1+ (0.75,20) [0|0] "" Vector__XXX
 SG_ VCRIGHT_tempDuctLeftEst m2 : 40|8@1+ (0.5,-22) [0|0] "" Vector__XXX
 SG_ VCRIGHT_frontRightSeatTempTargetQuasiSS m4 : 42|6@1+ (1,20) [0|0] "" Vector__XXX
 SG_ VCRIGHT_hvacLowerModePosition m1 : 45|8@1+ (0.4,0) [0|0] "" Vector__XXX
 SG_ VCRIGHT_hvacLowerModeTarget m0 : 45|8@1+ (0.4,0) [0|0] "" Vector__XXX
 SG_ VCRIGHT_tempDuctRightEst m2 : 48|8@1+ (0.5,-22) [0|0] "" Vector__XXX
 SG_ VCRIGHT_hvacIntakePosition m1 : 53|8@1+ (0.4,0) [0|0] "" Vector__XXX
 SG_ VCRIGHT_hvacIntakeTarget m0 : 53|8@1+ (0.4,0) [0|0] "" Vector__XXX
 SG_ VCRIGHT_ptcHeaterBadRodDetectionState m2 : 56|4@1+ (1,0) [0|0] "" Vector__XXX
 SG_ VCRIGHT_windshieldRHExteriorSurface m3 : 56|8@1+ (1,0) [0|0] "" Vector__XXX

BO_ 612 PCS_chgLineStatus: 8 Vector__XXX
 SG_ PCS_chgInputVoltage : 0|14@1+ (0.033,0) [0|0] "" Vector__XXX
 SG_ PCS_chgLineCurrent : 14|9@1+ (0.1,0) [0|0] "" Vector__XXX
 SG_ PCS_chgAcVoltagePresent : 23|1@1+ (1,0) [0|0] "" Vector__XXX
 SG_ PCS_chgInputPower : 24|8@1+ (0.1,0) [0|0] "" Vector__XXX
 SG_ PCS_chgAcCurrentLimit : 32|10@1+ (0.1,0) [0|0] "" Vector__XXX

BO_ 614 DIR_power: 8 Vector__XXX
 SG_ DIR_elecPower : 0|11@1- (0.5,0) [0|0] "" Vector__XXX
 SG_ DIR_heatPowerOptimal : 16|8@1+ (0.08,0) [0|0] "" Vector__XXX
 SG_ DIR_heatPowerMax : 24|8@1+ (0.08,0) [0|0] "" Vector__XXX
 SG_ DIR_heatPowerActual : 32|8@1+ (0.08,0) [0|0] "" Vector__XXX
 SG_ DIR_excessHeatCommand : 40|8@1+ (0.08,0) [0|0] "" Vector__XXX
 SG_ DIR_drivePowerMax : 48|9@1+ (1,0) [0|0] "" Vector__XXX

BO_ 615 DIR_powerSlow: 8 Vector__XXX
 SG_ DIR_elecPowerSlow : 0|11@1- (0.5,0) [0|0] "" Vector__XXX
 SG_ DIR_heatPowerOptimalSlow : 16|8@1+ (0.08,0) [0|0] "" Vector__XXX
 SG_ DIR_heatPowerMaxSlow : 24|8@1+ (0.08,0) [0|0] "" Vector__XXX
 SG_ DIR_heatPowerActualSlow : 32|8@1+ (0.08,0) [0|0] "" Vector__XXX
 SG_ DIR_excessHeatCommandSlow : 40|8@1+ (0.08,0) [0|0] "" Vector__XXX
 SG_ DIR_drivePowerMaxSlow : 48|9@1+ (1,0) [0|0] "" Vector__XXX

BO_ 616 DI_systemPower: 8 Vector__XXX
 SG_ DI_sysHeatPowerMax : 0|8@1+ (0.08,0) [0|0] "" Vector__XXX
 SG_ DI_sysHeatPowerActual : 8|8@1+ (0.08,0) [0|0] "" Vector__XXX
 SG_ DI_sysDrivePowerMax : 16|10@1+ (1,0) [0|0] "" Vector__XXX
 SG_ DI_primaryUnitSiliconType : 26|1@1+ (1,0) [0|0] "" Vector__XXX
 SG_ DI_sysRegenPowerMax : 32|8@1+ (1,-100) [0|0] "" Vector__XXX

BO_ 626 VCLEFT_epbmDebug: 8 Vector__XXX
 SG_ VCLEFT_epbmDebugIndex M : 0|1@1+ (1,0) [0|0] "" Vector__XXX
 SG_ VCLEFT_epbmCaliperState m0 : 1|3@1+ (1,0) [0|0] "" Vector__XXX
 SG_ VCLEFT_epbmOpenAllowed m1 : 1|1@1+ (1,0) [0|0] "" Vector__XXX
 SG_ VCLEFT_epbmDynamicAllowed m1 : 2|1@1+ (1,0) [0|0] "" Vector__XXX
 SG_ VCLEFT_epbmParkAllowed m1 : 3|1@1+ (1,0) [0|0] "" Vector__XXX
 SG_ VCLEFT_epbmMotorEnabled m0 : 4|1@1+ (1,0) [0|0] "" Vector__XXX
 SG_ VCLEFT_epbmStartAllowed m1 : 4|1@1+ (1,0) [0|0] "" Vector__XXX
 SG_ VCLEFT_epbMotorCurrent m0 : 5|11@1+ (0.01,0) [0|0] "" Vector__XXX
 SG_ VCLEFT_epbmServiceAllowed m1 : 5|1@1+ (1,0) [0|0] "" Vector__XXX
 SG_ VCLEFT_epbmWinchAllowed m1 : 6|1@1+ (1,0) [0|0] "" Vector__XXX
 SG_ VCLEFT_epbmWinchReleaseAllowed m1 : 7|1@1+ (1,0) [0|0] "" Vector__XXX
 SG_ VCLEFT_epbmParkingAllowed m1 : 8|1@1+ (1,0) [0|0] "" Vector__XXX
 SG_ VCLEFT_epbmDynApplyingAllowed m1 : 9|1@1+ (1,0) [0|0] "" Vector__XXX
 SG_ VCLEFT_epbmReleasingAllowed m1 : 10|1@1+ (1,0) [0|0] "" Vector__XXX
 SG_ VCLEFT_epbmFaultAllowed m1 : 11|1@1+ (1,0) [0|0] "" Vector__XXX
 SG_ VCLEFT_epbmSummonAllowed m1 : 12|1@1+ (1,0) [0|0] "" Vector__XXX
 SG_ VCLEFT_epbmSummonParkAllowed m1 : 13|1@1+ (1,0) [0|0] "" Vector__XXX
 SG_ VCLEFT_epbmSummonReleaseAllowed m1 : 14|1@1+ (1,0) [0|0] "" Vector__XXX
 SG_ VCLEFT_summonInitAllowed m1 : 15|1@1+ (1,0) [0|0] "" Vector__XXX
 SG_ VCLEFT_epbmApplyVoltage m0 : 16|11@1+ (0.01,0) [0|0] "" Vector__XXX
 SG_ VCLEFT_epbmUnknownAllowed m1 : 16|1@1+ (1,0) [0|0] "" Vector__XXX
 SG_ VCLEFT_summonIdleAllowed m1 : 17|1@1+ (1,0) [0|0] "" Vector__XXX
 SG_ VCLEFT_summonArmedAllowed m1 : 18|1@1+ (1,0) [0|0] "" Vector__XXX
 SG_ VCLEFT_summonActiveAllowed m1 : 19|1@1+ (1,0) [0|0] "" Vector__XXX
 SG_ VCLEFT_summonCompleteAllowed m1 : 20|1@1+ (1,0) [0|0] "" Vector__XXX
 SG_ VCLEFT_summonFaultAllowed m1 : 21|1@1+ (1,0) [0|0] "" Vector__XXX
 SG_ VCLEFT_summonUnavailableAllowed m1 : 22|1@1+ (1,0) [0|0] "" Vector__XXX
 SG_ VCLEFT_activeDecelAllowedLatch m1 : 23|1@1+ (1,0) [0|0] "" Vector__XXX
 SG_ VCLEFT_epbmReleaseVoltage m0 : 27|11@1+ (0.01,0) [0|0] "" Vector__XXX
 SG_ VCLEFT_summonFaultReason m0 : 40|5@1+ (1,0) [0|0] "" Vector__XXX
 SG_ VCLEFT_epbSummonState m0 : 45|3@1+ (1,0) [0|0] "" Vector__XXX
 SG_ VCLEFT_epbmSummonState m0 : 48|3@1+ (1,0) [0|0] "" Vector__XXX
 SG_ VCLEFT_epbUnitStatus m0 : 51|5@1+ (1,0) [0|0] "" Vector__XXX
 SG_ VCLEFT_epbmFaultStatus m0 : 56|2@1+ (1,0) [0|0] "" Vector__XXX
 SG_ VCLEFT_epbFaultStatus m0 : 58|2@1+ (1,0) [0|0] "" Vector__XXX
 SG_ VCLEFT_epbmSystemStatus m0 : 60|4@1+ (1,0) [0|0] "" Vector__XXX

BO_ 627 UI_vehicleControl: 8 Vector__XXX
 SG_ UI_powerStateRequest : 0|2@1+ (1,0) [0|0] "" Vector__XXX
 SG_ UI_childDoorLockOnRight : 2|1@1+ (1,0) [0|0] "" Vector__XXX
 SG_ UI_frontFogSwitch : 3|1@1+ (1,0) [0|0] "" Vector__XXX
 SG_ UI_summonActive : 4|1@1+ (1,0) [0|0] "" Vector__XXX
 SG_ UI_frunkRequest : 5|1@1+ (1,0) [0|0] "" Vector__XXX
 SG_ UI_wiperMode : 6|2@1+ (1,0) [0|0] "" Vector__XXX
 SG_ UI_steeringBacklightEnabled : 8|1@1+ (1,0) [0|0] "" Vector__XXX
 SG_ UI_steeringButtonMode : 9|3@1+ (1,0) [0|0] "" Vector__XXX
 SG_ UI_walkUpUnlock : 12|1@1+ (1,0) [0|0] "" Vector__XXX
 SG_ UI_walkAwayLock : 13|1@1+ (1,0) [0|0] "" Vector__XXX
 SG_ UI_unlockOnPark : 14|1@1+ (1,0) [0|0] "" Vector__XXX
 SG_ UI_globalUnlockOn : 15|1@1+ (1,0) [0|0] "" Vector__XXX
 SG_ UI_childDoorLockOnLeft : 16|1@1+ (1,0) [0|0] "" Vector__XXX
 SG_ UI_lockRequest : 17|3@1+ (1,0) [0|0] "" Vector__XXX
 SG_ UI_alarmEnabled : 20|1@1+ (1,0) [0|0] "" Vector__XXX
 SG_ UI_intrusionSensorOn : 21|1@1+ (1,0) [0|0] "" Vector__XXX
 SG_ UI_stop12vSupport : 22|1@1+ (1,0) [0|0] "" Vector__XXX
 SG_ UI_rearFogSwitch : 23|1@1+ (1,0) [0|0] "" Vector__XXX
 SG_ UI_mirrorFoldRequest : 24|2@1+ (1,0) [0|0] "" Vector__XXX
 SG_ UI_mirrorHeatRequest : 26|1@1+ (1,0) [0|0] "" Vector__XXX
 SG_ UI_remoteStartRequest : 27|3@1+ (1,0) [0|0] "" Vector__XXX
 SG_ UI_seeYouHomeLightingOn : 30|1@1+ (1,0) [0|0] "" Vector__XXX
 SG_ UI_powerOff : 31|1@1+ (1,0) [0|0] "" Vector__XXX
 SG_ UI_displayBrightnessLevel : 32|8@1+ (0.5,0) [0|0] "" Vector__XXX
 SG_ UI_ambientLightingEnabled : 40|1@1+ (1,0) [0|0] "" Vector__XXX
 SG_ UI_autoHighBeamEnabled : 41|1@1+ (1,0) [0|0] "" Vector__XXX
 SG_ UI_frontLeftSeatHeatReq : 42|2@1+ (1,0) [0|0] "" Vector__XXX
 SG_ UI_frontRightSeatHeatReq : 44|2@1+ (1,0) [0|0] "" Vector__XXX
 SG_ UI_rearLeftSeatHeatReq : 46|2@1+ (1,0) [0|0] "" Vector__XXX
 SG_ UI_rearCenterSeatHeatReq : 48|2@1+ (1,0) [0|0] "" Vector__XXX
 SG_ UI_rearRightSeatHeatReq : 50|2@1+ (1,0) [0|0] "" Vector__XXX
 SG_ UI_autoFoldMirrorsOn : 52|1@1+ (1,0) [0|0] "" Vector__XXX
 SG_ UI_mirrorDipOnReverse : 53|1@1+ (1,0) [0|0] "" Vector__XXX
 SG_ UI_remoteClosureRequest : 54|2@1+ (1,0) [0|0] "" Vector__XXX
 SG_ UI_wiperRequest : 56|3@1+ (1,0) [0|0] "" Vector__XXX
 SG_ UI_domeLightSwitch : 59|2@1+ (1,0) [0|0] "" Vector__XXX
 SG_ UI_honkHorn : 61|1@1+ (1,0) [0|0] "" Vector__XXX
 SG_ UI_driveStateRequest : 62|1@1+ (1,0) [0|0] "" Vector__XXX
 SG_ UI_rearWindowLockout : 63|1@1+ (1,0) [0|0] "" Vector__XXX

BO_ 630 DI_authenticityMsg: 8 Vector__XXX
 SG_ DI_authenticityCommand : 0|8@1+ (1,0) [0|0] "" Vector__XXX
 SG_ DI_salt1 : 8|8@1+ (1,0) [0|0] "" Vector__XXX
 SG_ DI_salt2 : 16|8@1+ (1,0) [0|0] "" Vector__XXX
 SG_ DI_salt3 : 24|8@1+ (1,0) [0|0] "" Vector__XXX
 SG_ DI_salt4 : 32|8@1+ (1,0) [0|0] "" Vector__XXX
 SG_ DI_salt5 : 40|8@1+ (1,0) [0|0] "" Vector__XXX
 SG_ DI_salt6 : 48|8@1+ (1,0) [0|0] "" Vector__XXX
 SG_ DI_salt7 : 56|8@1+ (1,0) [0|0] "" Vector__XXX

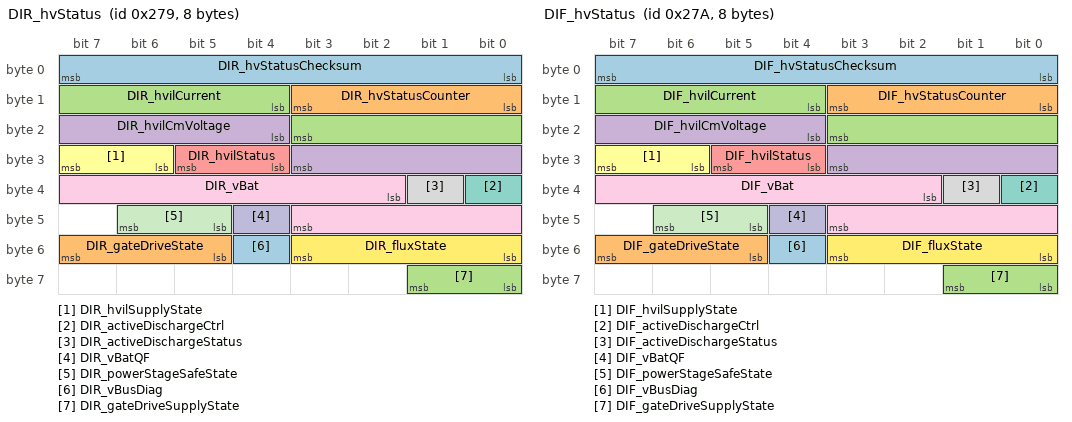
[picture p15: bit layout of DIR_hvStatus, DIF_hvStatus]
BO_ 633 DIR_hvStatus: 8 Vector__XXX
 SG_ DIR_hvStatusChecksum : 0|8@1+ (1,0) [0|0] "" Vector__XXX
 SG_ DIR_hvStatusCounter : 8|4@1+ (1,0) [0|0] "" Vector__XXX
 SG_ DIR_hvilCurrent : 12|8@1+ (0.1,0) [0|0] "" Vector__XXX
 SG_ DIR_hvilCmVoltage : 20|8@1+ (0.08,0) [0|0] "" Vector__XXX
 SG_ DIR_hvilStatus : 28|2@1+ (1,0) [0|0] "" Vector__XXX
 SG_ DIR_hvilSupplyState : 30|2@1+ (1,0) [0|0] "" Vector__XXX
 SG_ DIR_activeDischargeCtrl : 32|1@1+ (1,0) [0|0] "" Vector__XXX
 SG_ DIR_activeDischargeStatus : 33|1@1+ (1,0) [0|0] "" Vector__XXX
 SG_ DIR_vBat : 34|10@1+ (1,0) [0|0] "" Vector__XXX
 SG_ DIR_vBatQF : 44|1@1+ (1,0) [0|0] "" Vector__XXX
 SG_ DIR_powerStageSafeState : 45|2@1+ (1,0) [0|0] "" Vector__XXX
 SG_ DIR_fluxState : 48|4@1+ (1,0) [0|0] "" Vector__XXX
 SG_ DIR_vBusDiag : 52|1@1+ (1,0) [0|0] "" Vector__XXX
 SG_ DIR_gateDriveState : 53|3@1+ (1,0) [0|0] "" Vector__XXX
 SG_ DIR_gateDriveSupplyState : 56|2@1+ (1,0) [0|0] "" Vector__XXX

BO_ 634 DIF_hvStatus: 8 Vector__XXX
 SG_ DIF_hvStatusChecksum : 0|8@1+ (1,0) [0|0] "" Vector__XXX
 SG_ DIF_hvStatusCounter : 8|4@1+ (1,0) [0|0] "" Vector__XXX
 SG_ DIF_hvilCurrent : 12|8@1+ (0.1,0) [0|0] "" Vector__XXX
 SG_ DIF_hvilCmVoltage : 20|8@1+ (0.08,0) [0|0] "" Vector__XXX
 SG_ DIF_hvilStatus : 28|2@1+ (1,0) [0|0] "" Vector__XXX
 SG_ DIF_hvilSupplyState : 30|2@1+ (1,0) [0|0] "" Vector__XXX
 SG_ DIF_activeDischargeCtrl : 32|1@1+ (1,0) [0|0] "" Vector__XXX
 SG_ DIF_activeDischargeStatus : 33|1@1+ (1,0) [0|0] "" Vector__XXX
 SG_ DIF_vBat : 34|10@1+ (1,0) [0|0] "" Vector__XXX
 SG_ DIF_vBatQF : 44|1@1+ (1,0) [0|0] "" Vector__XXX
 SG_ DIF_powerStageSafeState : 45|2@1+ (1,0) [0|0] "" Vector__XXX
 SG_ DIF_fluxState : 48|4@1+ (1,0) [0|0] "" Vector__XXX
 SG_ DIF_vBusDiag : 52|1@1+ (1,0) [0|0] "" Vector__XXX
 SG_ DIF_gateDriveState : 53|3@1+ (1,0) [0|0] "" Vector__XXX
 SG_ DIF_gateDriveSupplyState : 56|2@1+ (1,0) [0|0] "" Vector__XXX

BO_ 637 CP_dcChargeLimits: 8 Vector__XXX
 SG_ CP_evseMaxDcCurrentLimit : 0|13@1+ (0.25,0) [0|0] "" Vector__XXX
 SG_ CP_evseMinDcCurrentLimit : 13|12@1+ (0.5,0) [0|0] "" Vector__XXX
 SG_ CP_evseMaxDcVoltageLimit : 25|13@1+ (0.07324218755,0) [0|0] "" Vector__XXX
 SG_ CP_evseMinDcVoltageLimit : 38|13@1+ (0.07324218755,0) [0|0] "" Vector__XXX
 SG_ CP_evseInstantDcCurrentLimit : 51|12@1+ (0.5,0) [0|0] "" Vector__XXX
 SG_ CP_dcChargeLimitsContentValid : 63|1@1+ (1,0) [0|0] "" Vector__XXX

BO_ 641 VCFRONT_CMPRequest: 8 Vector__XXX
 SG_ VCFRONT_CMPTargetDuty : 0|16@1+ (0.1,0) [0|0] "" Vector__XXX
 SG_ VCFRONT_CMPPowerLimit : 16|16@1+ (1,0) [0|0] "" Vector__XXX
 SG_ VCFRONT_CMPReset : 32|8@1+ (1,0) [0|0] "" Vector__XXX
 SG_ VCFRONT_CMPEnable : 40|1@1+ (1,0) [0|0] "" Vector__XXX

BO_ 642 VCLEFT_hvacBlowerFeedback: 8 Vector__XXX
 SG_ VCLEFT_hvacBlowerFeedbackIndex M : 0|1@1+ (1,0) [0|0] "" Vector__XXX
 SG_ VCLEFT_hvacBlowerEnabled m0 : 2|1@1+ (1,0) [0|0] "" Vector__XXX
 SG_ VCLEFT_hvacBlowerOutputDuty m0 : 3|7@1+ (1,0) [0|0] "" Vector__XXX
 SG_ VCLEFT_hvacBlowerRPMTarget m0 : 10|10@1+ (10,0) [0|0] "" Vector__XXX
 SG_ VCLEFT_hvacBlowerRPMActual m0 : 20|10@1+ (10,0) [0|0] "" Vector__XXX
 SG_ VCLEFT_hvacBlowerTorque m0 : 34|10@1+ (0.006,-1.5) [0|0] "" Vector__XXX
 SG_ VCLEFT_hvacBlowerFETTemp m0 : 44|7@1+ (2,-50) [0|0] "" Vector__XXX
 SG_ VCLEFT_hvacBlowerIDc m0 : 51|7@1+ (0.5,0) [0|0] "" Vector__XXX
 SG_ VCLEFT_hvacBlowerInitd m0 : 58|1@1+ (1,0) [0|0] "" Vector__XXX
 SG_ VCLEFT_hvacBlowerFault m0 : 59|1@1+ (1,0) [0|0] "" Vector__XXX
 SG_ VCLEFT_hvacBlowerLimitFETTemps m0 : 60|1@1+ (1,0) [0|0] "" Vector__XXX
 SG_ VCLEFT_hvacBlowerPowerOn m0 : 61|1@1+ (1,0) [0|0] "" Vector__XXX

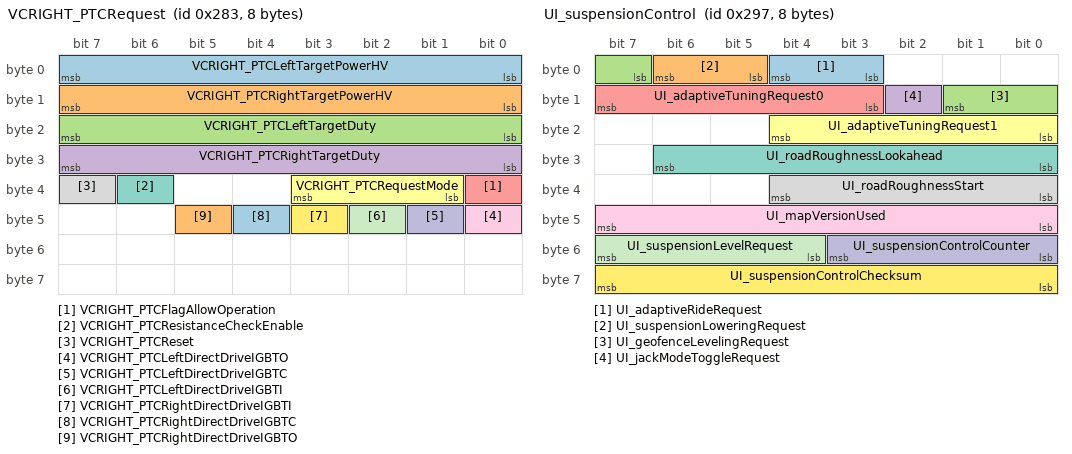
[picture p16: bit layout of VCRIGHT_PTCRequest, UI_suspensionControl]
BO_ 643 VCRIGHT_PTCRequest: 8 Vector__XXX
 SG_ VCRIGHT_PTCLeftTargetPowerHV : 0|8@1+ (30,0) [0|0] "" Vector__XXX
 SG_ VCRIGHT_PTCRightTargetPowerHV : 8|8@1+ (30,0) [0|0] "" Vector__XXX
 SG_ VCRIGHT_PTCLeftTargetDuty : 16|8@1+ (0.5,0) [0|0] "" Vector__XXX
 SG_ VCRIGHT_PTCRightTargetDuty : 24|8@1+ (0.5,0) [0|0] "" Vector__XXX
 SG_ VCRIGHT_PTCFlagAllowOperation : 32|1@1+ (1,0) [0|0] "" Vector__XXX
 SG_ VCRIGHT_PTCRequestMode : 33|3@1+ (1,0) [0|0] "" Vector__XXX
 SG_ VCRIGHT_PTCResistanceCheckEnable : 38|1@1+ (1,0) [0|0] "" Vector__XXX
 SG_ VCRIGHT_PTCReset : 39|1@1+ (1,0) [0|0] "" Vector__XXX
 SG_ VCRIGHT_PTCLeftDirectDriveIGBTO : 40|1@1+ (1,0) [0|0] "" Vector__XXX
 SG_ VCRIGHT_PTCLeftDirectDriveIGBTC : 41|1@1+ (1,0) [0|0] "" Vector__XXX
 SG_ VCRIGHT_PTCLeftDirectDriveIGBTI : 42|1@1+ (1,0) [0|0] "" Vector__XXX
 SG_ VCRIGHT_PTCRightDirectDriveIGBTI : 43|1@1+ (1,0) [0|0] "" Vector__XXX
 SG_ VCRIGHT_PTCRightDirectDriveIGBTC : 44|1@1+ (1,0) [0|0] "" Vector__XXX
 SG_ VCRIGHT_PTCRightDirectDriveIGBTO : 45|1@1+ (1,0) [0|0] "" Vector__XXX

BO_ 644 UI_vehicleModes: 8 Vector__XXX
 SG_ UI_factoryMode : 0|1@1+ (1,0) [0|0] "" Vector__XXX
 SG_ UI_transportMode : 1|1@1+ (1,0) [0|0] "" Vector__XXX
 SG_ UI_showroomMode : 2|1@1+ (1,0) [0|0] "" Vector__XXX
 SG_ UI_serviceMode : 3|1@1+ (1,0) [0|0] "" Vector__XXX
 SG_ UI_isDelivered : 4|1@1+ (1,0) [0|0] "" Vector__XXX
 SG_ UI_hasEverBeenDelivered : 5|1@1+ (1,0) [0|0] "" Vector__XXX
 SG_ UI_homelinkV2Command0 : 8|8@1+ (1,0) [0|0] "" Vector__XXX
 SG_ UI_homelinkV2Command1 : 16|8@1+ (1,0) [0|0] "" Vector__XXX
 SG_ UI_homelinkV2Command2 : 24|8@1+ (1,0) [0|0] "" Vector__XXX
 SG_ UI_carWashMode : 32|1@1+ (1,0) [0|0] "" Vector__XXX
 SG_ UI_valetMode : 33|1@1+ (1,0) [0|0] "" Vector__XXX
 SG_ UI_gameMode : 34|1@1+ (1,0) [0|0] "" Vector__XXX
 SG_ UI_diagnosticsAllowed : 35|1@1+ (1,0) [0|0] "" Vector__XXX
 SG_ UI_serviceModePlus : 36|1@1+ (1,0) [0|0] "" Vector__XXX
 SG_ UI_premiumAmpPowerOff : 37|1@1+ (1,0) [0|0] "" Vector__XXX
 SG_ UI_signedCmdHardLocked : 38|1@1+ (1,0) [0|0] "" Vector__XXX
 SG_ UI_signedCmdServiceMode : 39|1@1+ (1,0) [0|0] "" Vector__XXX
 SG_ UI_closureEasterEggStatus : 40|2@1+ (1,0) [0|0] "" Vector__XXX
 SG_ UI_lightShowType : 42|3@1+ (1,0) [0|0] "" Vector__XXX
 SG_ UI_sohTestRequest : 45|1@1+ (1,0) [0|0] "" Vector__XXX
 SG_ UI_vehicleModesCounter : 52|4@1+ (1,0) [0|0] "" Vector__XXX
 SG_ UI_vehicleModesChecksum : 56|8@1+ (1,0) [0|0] "" Vector__XXX

BO_ 645 UI_driverProfileRecall: 8 Vector__XXX
 SG_ UI_driverProfileRecallIndex M : 0|3@1+ (1,0) [0|0] "" Vector__XXX
 SG_ UI_driverProfileRecallStop : 3|1@1+ (1,0) [0|0] "" Vector__XXX
 SG_ UI_columnAndLumbarRecallActive m2 : 4|1@1+ (1,0) [0|0] "" Vector__XXX
 SG_ UI_frontSeatRecallActive m1 : 4|1@1+ (1,0) [0|0] "" Vector__XXX
 SG_ UI_mirrorRecallActive m4 : 4|1@1+ (1,0) [0|0] "" Vector__XXX
 SG_ UI_customMirrorDipPositionsSet m4 : 5|1@1+ (1,0) [0|0] "" Vector__XXX
 SG_ UI_frontSeatTrackPos m1 : 5|10@1- (4,0) [0|0] "" Vector__XXX
 SG_ UI_leftMirrorDipXPosition m4 : 8|8@1+ (0.02,0) [0|0] "" Vector__XXX
 SG_ UI_leftMirrorTiltXPosition m3 : 8|8@1+ (0.02,0) [0|0] "" Vector__XXX
 SG_ UI_steeringColumnUpDownPos m2 : 8|8@1- (1,103) [0|0] "" Vector__XXX
 SG_ UI_frontSeatBackPos m1 : 16|12@1- (0.1,0) [0|0] "" Vector__XXX
 SG_ UI_leftMirrorDipYPosition m4 : 16|8@1+ (0.02,0) [0|0] "" Vector__XXX
 SG_ UI_leftMirrorTiltYPosition m3 : 16|8@1+ (0.02,0) [0|0] "" Vector__XXX
 SG_ UI_lumbarAPressurePercentage m2 : 16|7@1+ (1,0) [0|0] "" Vector__XXX
 SG_ UI_rightMirrorDipXPosition m4 : 24|8@1+ (0.02,0) [0|0] "" Vector__XXX
 SG_ UI_rightMirrorTiltXPosition m3 : 24|8@1+ (0.02,0) [0|0] "" Vector__XXX
 SG_ UI_frontSeatLiftPos m1 : 32|10@1- (4,0) [0|0] "" Vector__XXX
 SG_ UI_lumbarBPressurePercentage m2 : 32|7@1+ (1,0) [0|0] "" Vector__XXX
 SG_ UI_rightMirrorDipYPosition m4 : 32|8@1+ (0.02,0) [0|0] "" Vector__XXX
 SG_ UI_rightMirrorTiltYPosition m3 : 32|8@1+ (0.02,0) [0|0] "" Vector__XXX
 SG_ UI_modifyMirrorDipRequest m4 : 40|2@1+ (1,0) [0|0] "" Vector__XXX
 SG_ UI_frontSeatTiltPos m1 : 48|12@1- (0.1,0) [0|0] "" Vector__XXX
 SG_ UI_steeringColumnInOutPos m2 : 48|8@1- (1,103) [0|0] "" Vector__XXX

BO_ 646 UI_driverProfileRecall2: 8 Vector__XXX
 SG_ UI_driverProfileLinkedKeySHA1 : 0|32@1+ (1,0) [0|0] "" Vector__XXX
 SG_ UI_driverProfileIndex : 32|4@1+ (1,0) [0|0] "" Vector__XXX
 SG_ UI_driverProfileSelectionType : 36|2@1+ (1,0) [0|0] "" Vector__XXX
 SG_ UI_driverProfilePositionAdjusted : 38|1@1+ (1,0) [0|0] "" Vector__XXX
 SG_ UI_activeKeyRequested : 39|1@1+ (1,0) [0|0] "" Vector__XXX

BO_ 647 PTC_sensorStatus: 8 Vector__XXX
 SG_ PTC_leftTempIGBT : 0|8@1+ (1,-40) [0|0] "" Vector__XXX
 SG_ PTC_tempOCP : 8|8@1+ (1,-40) [0|0] "" Vector__XXX
 SG_ PTC_rightTempIGBT : 16|8@1+ (1,-40) [0|0] "" Vector__XXX
 SG_ PTC_tempPCB : 24|8@1+ (1,-40) [0|0] "" Vector__XXX
 SG_ PTC_voltageHV : 32|10@1+ (0.5,0) [0|0] "" Vector__XXX
 SG_ PTC_leftCurrentHV : 48|8@1+ (0.2,0) [0|0] "" Vector__XXX
 SG_ PTC_rightCurrentHV : 56|8@1+ (0.2,0) [0|0] "" Vector__XXX

BO_ 648 EPBL_internalStatus: 8 Vector__XXX
 SG_ EPBL_unitStatus : 0|5@1+ (1,0) [0|0] "" Vector__XXX
 SG_ EPBL_unitFaultStatus : 5|2@1+ (1,0) [0|0] "" Vector__XXX
 SG_ EPBL_summonState : 8|3@1+ (1,0) [0|0] "" Vector__XXX
 SG_ EPBL_disconnected : 11|1@1+ (1,0) [0|0] "" Vector__XXX
 SG_ EPBL_pistonTouchingRotor : 12|1@1+ (1,0) [0|0] "" Vector__XXX
 SG_ EPBL_csmFaultReason : 13|5@1+ (1,0) [0|0] "" Vector__XXX
 SG_ EPBL_esmOperationTrigger : 18|6@1+ (1,0) [0|0] "" Vector__XXX
 SG_ EPBL_summonFaultReason : 24|5@1+ (1,0) [0|0] "" Vector__XXX
 SG_ EPBL_localServiceModeActive : 29|1@1+ (1,0) [0|0] "" Vector__XXX
 SG_ EPBL_localCdpState : 30|2@1+ (1,0) [0|0] "" Vector__XXX
 SG_ EPBL_chimeRequestLocal : 33|3@1+ (1,0) [0|0] "" Vector__XXX
 SG_ EPBL_telltaleLocal : 39|3@1+ (1,0) [0|0] "" Vector__XXX
 SG_ EPBL_driverIsLeavingLocal : 42|1@1+ (1,0) [0|0] "" Vector__XXX
 SG_ EPBL_driverIsLeavingAnySpeedLocal : 43|1@1+ (1,0) [0|0] "" Vector__XXX
 SG_ EPBL_internalCDPRequest : 44|1@1+ (1,0) [0|0] "" Vector__XXX
 SG_ EPBL_esmSpeedClass : 45|3@1+ (1,0) [0|0] "" Vector__XXX
 SG_ EPBL_learnedEpbConfig : 48|4@1+ (1,0) [0|0] "" Vector__XXX
 SG_ EPBL_internalStatusCounter : 52|4@1+ (1,0) [0|0] "" Vector__XXX
 SG_ EPBL_internalStatusChecksum : 56|8@1+ (1,0) [0|0] "" Vector__XXX

BO_ 649 VCLEFT_logging10Hz: 8 Vector__XXX
 SG_ VCLEFT_logging10HzIndex M : 0|1@1+ (1,0) [0|0] "" Vector__XXX
 SG_ VCLEFT_hvacBlowerRs m0 : 1|8@1+ (0.25,0) [0|0] "" Vector__XXX
 SG_ VCLEFT_hvacBlowerIPhase0 m0 : 9|7@1+ (0.4,0) [0|0] "" Vector__XXX
 SG_ VCLEFT_hvacBlowerIPhase1 m0 : 16|7@1+ (0.4,0) [0|0] "" Vector__XXX
 SG_ VCLEFT_hvacBlowerIPhase2 m0 : 23|7@1+ (0.4,0) [0|0] "" Vector__XXX
 SG_ VCLEFT_hvacBlower_IO_CBC_HEAD m0 : 30|4@1+ (1,0) [0|0] "" Vector__XXX
 SG_ VCLEFT_hvacBlower_IO_CBC_TAIL m0 : 34|4@1+ (1,0) [0|0] "" Vector__XXX
 SG_ VCLEFT_hvacBlower_IO_CBC_TAIL_valid m0 : 38|1@1+ (1,0) [0|0] "" Vector__XXX
 SG_ VCLEFT_hvacBlower_IO_CBC_Status m0 : 39|1@1+ (1,0) [0|0] "" Vector__XXX
 SG_ VCLEFT_hvacBlower_IO_CBC_numUartErr m0 : 40|8@1+ (1,0) [0|0] "" Vector__XXX
 SG_ VCLEFT_hvacBlowerCBCEstState m0 : 48|4@1+ (1,0) [0|0] "" Vector__XXX
 SG_ VCLEFT_hvacBlowerCBCCtrlState m0 : 52|3@1+ (1,0) [0|0] "" Vector__XXX
 SG_ VCLEFT_hvacBlowerITerm m0 : 55|7@1+ (0.05,-1.5) [0|0] "" Vector__XXX
 SG_ VCLEFT_hvacBlowerSpiError m0 : 62|1@1+ (1,0) [0|0] "" Vector__XXX
 SG_ VCLEFT_hvacBlowerRsOnlineActive m0 : 63|1@1+ (1,0) [0|0] "" Vector__XXX

BO_ 658 BMS_socStatus: 8 Vector__XXX
 SG_ BMS_socMin : 0|10@1+ (0.1,0) [0|0] "" Vector__XXX
 SG_ BMS_socUI : 10|10@1+ (0.1,0) [0|0] "" Vector__XXX
 SG_ BMS_socMax : 20|10@1+ (0.1,0) [0|0] "" Vector__XXX
 SG_ BMS_socAvg : 30|10@1+ (0.1,0) [0|0] "" Vector__XXX
 SG_ BMS_enoughEnergyForConvenienceFeatures : 40|1@1+ (1,0) [0|0] "" Vector__XXX
 SG_ BMS_instantChargePowerCapability : 48|16@1+ (0.05,0) [0|0] "" Vector__XXX

BO_ 659 UI_chassisControl: 8 Vector__XXX
 SG_ UI_steeringTuneRequest : 0|2@1+ (1,0) [0|0] "" Vector__XXX
 SG_ UI_tractionControlMode : 2|3@1+ (1,0) [0|0] "" Vector__XXX
 SG_ UI_parkBrakeRequest : 5|2@1+ (1,0) [0|0] "" Vector__XXX
 SG_ UI_narrowGarages : 7|1@1+ (1,0) [0|0] "" Vector__XXX
 SG_ UI_winchModeRequest : 8|2@1+ (1,0) [0|0] "" Vector__XXX
 SG_ UI_zeroSpeedConfirmed : 10|2@1+ (1,0) [0|0] "" Vector__XXX
 SG_ UI_trailerMode : 12|1@1+ (1,0) [0|0] "" Vector__XXX
 SG_ UI_distanceUnits : 13|1@1+ (1,0) [0|0] "" Vector__XXX
 SG_ UI_dasDebugEnable : 14|1@1+ (1,0) [0|0] "" Vector__XXX
 SG_ UI_accOvertakeEnable : 16|2@1+ (1,0) [0|0] "" Vector__XXX
 SG_ UI_aebEnable : 18|2@1+ (1,0) [0|0] "" Vector__XXX
 SG_ UI_aesEnable : 20|2@1+ (1,0) [0|0] "" Vector__XXX
 SG_ UI_ahlbEnable : 22|2@1+ (1,0) [0|0] "" Vector__XXX
 SG_ UI_autoLaneChangeEnable : 24|2@1+ (1,0) [0|0] "" Vector__XXX
 SG_ UI_winchProxUserOverride : 26|1@1+ (1,0) [0|0] "" Vector__XXX
 SG_ UI_rebootAutopilot : 27|1@1+ (1,0) [0|0] "" Vector__XXX
 SG_ UI_autoParkRequest : 28|4@1+ (1,0) [0|0] "" Vector__XXX
 SG_ UI_bsdEnable : 32|2@1+ (1,0) [0|0] "" Vector__XXX
 SG_ UI_fcwEnable : 34|2@1+ (1,0) [0|0] "" Vector__XXX
 SG_ UI_fcwSensitivity : 36|2@1+ (1,0) [0|0] "" Vector__XXX
 SG_ UI_latControlEnable : 38|2@1+ (1,0) [0|0] "" Vector__XXX
 SG_ UI_ldwEnable : 40|2@1+ (1,0) [0|0] "" Vector__XXX
 SG_ UI_pedalSafetyEnable : 42|2@1+ (1,0) [0|0] "" Vector__XXX
 SG_ UI_pedalMap_epas : 44|2@1+ (1,0) [0|0] "" Vector__XXX
 SG_ UI_redLightStopSignEnable : 46|2@1+ (1,0) [0|0] "" Vector__XXX
 SG_ UI_selfParkTune : 48|4@1+ (1,0) [0|0] "" Vector__XXX
 SG_ UI_chassisControlCounter : 52|4@1+ (1,0) [0|0] "" Vector__XXX
 SG_ UI_chassisControlChecksum : 56|8@1+ (1,0) [0|0] "" Vector__XXX

BO_ 660 UI_vehicleControl3: 8 Vector__XXX
 SG_ UI_lightFlashRequest : 0|2@1+ (1,0) [0|0] "" Vector__XXX
 SG_ UI_keylessDrivingEnabled : 2|1@1+ (1,0) [0|0] "" Vector__XXX
 SG_ UI_phoneCallActive : 3|1@1+ (1,0) [0|0] "" Vector__XXX
 SG_ UI_drivingSideVEH : 4|2@1+ (1,0) [0|0] "" Vector__XXX
 SG_ UI_keyPairResponse : 6|2@1+ (1,0) [0|0] "" Vector__XXX
 SG_ UI_lightShowClosuresEnabled : 8|1@1+ (1,0) [0|0] "" Vector__XXX
 SG_ UI_steeringWheelHeatAutoReq : 9|1@1+ (1,0) [0|0] "" Vector__XXX
 SG_ UI_steeringWheelHeatLevelReq : 10|2@1+ (1,0) [0|0] "" Vector__XXX
 SG_ UI_headlightPulseRequest : 12|1@1+ (1,0) [0|0] "" Vector__XXX
 SG_ UI_VCSECFeature2 : 13|1@1+ (1,0) [0|0] "" Vector__XXX
 SG_ UI_VCSECFeature3 : 14|1@1+ (1,0) [0|0] "" Vector__XXX
 SG_ UI_VCSECFeature4 : 15|1@1+ (1,0) [0|0] "" Vector__XXX
 SG_ UI_VCSECFeature5 : 16|1@1+ (1,0) [0|0] "" Vector__XXX
 SG_ UI_shortHornRequest : 17|1@1+ (1,0) [0|0] "" Vector__XXX
 SG_ UI_packTempLoggingRequest : 18|1@1+ (1,0) [0|0] "" Vector__XXX
 SG_ UI_UMC3UpdateInhibit : 22|1@1+ (1,0) [0|0] "" Vector__XXX
 SG_ UI_displayRedShiftActive : 24|1@1+ (1,0) [0|0] "" Vector__XXX
 SG_ UI_blindSpotIndicatorLightRequest : 35|1@1+ (1,0) [0|0] "" Vector__XXX
 SG_ UI_keepOnAccessoryPortsReq : 38|1@1+ (1,0) [0|0] "" Vector__XXX
 SG_ UI_windowPercentageRequest : 42|6@1- (5,0) [0|0] "" Vector__XXX
 SG_ UI_windowRequestedFL : 48|1@1+ (1,0) [0|0] "" Vector__XXX
 SG_ UI_windowRequestedFR : 49|1@1+ (1,0) [0|0] "" Vector__XXX
 SG_ UI_windowRequestedRL : 50|1@1+ (1,0) [0|0] "" Vector__XXX
 SG_ UI_windowRequestedRR : 51|1@1+ (1,0) [0|0] "" Vector__XXX
 SG_ UI_windowRequest : 52|3@1+ (1,0) [0|0] "" Vector__XXX
 SG_ UI_closeTrunkRequest : 55|1@1+ (1,0) [0|0] "" Vector__XXX
 SG_ UI_derivedLoadshedFeature : 59|1@1+ (1,0) [0|0] "" Vector__XXX
 SG_ UI_selfParkStandingBy : 62|1@1+ (1,0) [0|0] "" Vector__XXX

BO_ 661 UI_powerRationalityConfig: 8 Vector__XXX
 SG_ UI_vcleftCfgCutoffDynamicA m8 : 0|16@1+ (50,0) [0|0] "" Vector__XXX
 SG_ UI_vcleftCfgCutoffStaticA m7 : 0|16@1+ (50,0) [0|0] "" Vector__XXX
 SG_ UI_vcleftCfgCutoffThreshold0 m6 : 0|4@1+ (1,0) [0|0] "" Vector__XXX
 SG_ UI_vcleftCfgRationalityDynamicA m2 : 0|16@1+ (50,0) [0|0] "" Vector__XXX
 SG_ UI_vcleftCfgRationalityStaticA m1 : 0|16@1+ (50,0) [0|0] "" Vector__XXX
 SG_ UI_vcleftCfgRationalityThreshold0 m0 : 0|4@1+ (1,0) [0|0] "" Vector__XXX
 SG_ UI_vcrightCfgCutoffDynamicA m11 : 0|16@1+ (50,0) [0|0] "" Vector__XXX
 SG_ UI_vcrightCfgCutoffStaticA m10 : 0|16@1+ (50,0) [0|0] "" Vector__XXX
 SG_ UI_vcrightCfgCutoffThreshold0 m9 : 0|4@1+ (1,0) [0|0] "" Vector__XXX
 SG_ UI_vcrightCfgRationalityDynamicA m5 : 0|16@1+ (50,0) [0|0] "" Vector__XXX
 SG_ UI_vcrightCfgRationalityStaticA m4 : 0|16@1+ (50,0) [0|0] "" Vector__XXX
 SG_ UI_vcrightCfgRationalityThreshold0 m3 : 0|4@1+ (1,0) [0|0] "" Vector__XXX
 SG_ UI_vcleftCfgCutoffTime0 m6 : 4|4@1+ (1,0) [0|0] "" Vector__XXX
 SG_ UI_vcleftCfgRationalityTime0 m0 : 4|4@1+ (1,0) [0|0] "" Vector__XXX
 SG_ UI_vcrightCfgCutoffTime0 m9 : 4|4@1+ (1,0) [0|0] "" Vector__XXX
 SG_ UI_vcrightCfgRationalityTime0 m3 : 4|4@1+ (1,0) [0|0] "" Vector__XXX
 SG_ UI_vcleftCfgCutoffThreshold1 m6 : 8|4@1+ (1,0) [0|0] "" Vector__XXX
 SG_ UI_vcleftCfgRationalityThreshold1 m0 : 8|4@1+ (1,0) [0|0] "" Vector__XXX
 SG_ UI_vcrightCfgCutoffThreshold1 m9 : 8|4@1+ (1,0) [0|0] "" Vector__XXX
 SG_ UI_vcrightCfgRationalityThreshold1 m3 : 8|4@1+ (1,0) [0|0] "" Vector__XXX
 SG_ UI_vcleftCfgCutoffTime1 m6 : 12|4@1+ (1,0) [0|0] "" Vector__XXX
 SG_ UI_vcleftCfgRationalityTime1 m0 : 12|4@1+ (1,0) [0|0] "" Vector__XXX
 SG_ UI_vcrightCfgCutoffTime1 m9 : 12|4@1+ (1,0) [0|0] "" Vector__XXX
 SG_ UI_vcrightCfgRationalityTime1 m3 : 12|4@1+ (1,0) [0|0] "" Vector__XXX
 SG_ UI_vcleftCfgCutoffDynamicB m8 : 16|16@1- (1,0) [0|0] "" Vector__XXX
 SG_ UI_vcleftCfgCutoffStaticB m7 : 16|16@1- (1,0) [0|0] "" Vector__XXX
 SG_ UI_vcleftCfgRationalityDynamicB m2 : 16|16@1- (1,0) [0|0] "" Vector__XXX
 SG_ UI_vcleftCfgRationalityStaticB m1 : 16|16@1- (1,0) [0|0] "" Vector__XXX
 SG_ UI_vcrightCfgCutoffDynamicB m11 : 16|16@1- (1,0) [0|0] "" Vector__XXX
 SG_ UI_vcrightCfgCutoffStaticB m10 : 16|16@1- (1,0) [0|0] "" Vector__XXX
 SG_ UI_vcrightCfgRationalityDynamicB m5 : 16|16@1- (1,0) [0|0] "" Vector__XXX
 SG_ UI_vcrightCfgRationalityStaticB m4 : 16|16@1- (1,0) [0|0] "" Vector__XXX
 SG_ UI_vcleftCfgCutoffDynamicC m8 : 32|16@1- (50,0) [0|0] "" Vector__XXX
 SG_ UI_vcleftCfgCutoffStaticC m7 : 32|16@1- (50,0) [0|0] "" Vector__XXX
 SG_ UI_vcleftCfgRationalityDynamicC m2 : 32|16@1- (50,0) [0|0] "" Vector__XXX
 SG_ UI_vcleftCfgRationalityStaticC m1 : 32|16@1- (50,0) [0|0] "" Vector__XXX
 SG_ UI_vcrightCfgCutoffDynamicC m11 : 32|16@1- (50,0) [0|0] "" Vector__XXX
 SG_ UI_vcrightCfgCutoffStaticC m10 : 32|16@1- (50,0) [0|0] "" Vector__XXX
 SG_ UI_vcrightCfgRationalityDynamicC m5 : 32|16@1- (50,0) [0|0] "" Vector__XXX
 SG_ UI_vcrightCfgRationalityStaticC m4 : 32|16@1- (50,0) [0|0] "" Vector__XXX
 SG_ UI_powerRationalityConfigIndex M : 56|8@1+ (1,0) [0|0] "" Vector__XXX

BO_ 663 UI_suspensionControl: 8 Vector__XXX
 SG_ UI_adaptiveRideRequest : 3|2@1+ (1,0) [0|0] "" Vector__XXX
 SG_ UI_suspensionLoweringRequest : 5|2@1+ (1,0) [0|0] "" Vector__XXX
 SG_ UI_geofenceLevelingRequest : 7|3@1+ (1,0) [0|0] "" Vector__XXX
 SG_ UI_jackModeToggleRequest : 10|1@1+ (1,0) [0|0] "" Vector__XXX
 SG_ UI_adaptiveTuningRequest0 : 11|5@1- (0.1,0) [0|0] "" Vector__XXX
 SG_ UI_adaptiveTuningRequest1 : 16|5@1- (0.1,0) [0|0] "" Vector__XXX
 SG_ UI_roadRoughnessLookahead : 24|7@1+ (0.01,0) [0|0] "" Vector__XXX
 SG_ UI_roadRoughnessStart : 32|5@1+ (10,0) [0|0] "" Vector__XXX
 SG_ UI_mapVersionUsed : 40|8@1+ (1,0) [0|0] "" Vector__XXX
 SG_ UI_suspensionControlCounter : 48|4@1+ (1,0) [0|0] "" Vector__XXX
 SG_ UI_suspensionLevelRequest : 52|4@1+ (1,0) [0|0] "" Vector__XXX
 SG_ UI_suspensionControlChecksum : 56|8@1+ (1,0) [0|0] "" Vector__XXX

BO_ 664 ICR_status: 8 Vector__XXX
 SG_ ICR_sensorMode : 0|4@1+ (1,0) [0|0] "" Vector__XXX
 SG_ ICR_blocked : 4|2@1+ (1,0) [0|0] "" Vector__XXX
 SG_ ICR_booted : 6|1@1+ (1,0) [0|0] "" Vector__XXX
 SG_ ICR_rdMapDumpCompleted : 7|1@1+ (1,0) [0|0] "" Vector__XXX
 SG_ ICR_algoVersion : 8|6@1+ (1,0) [0|0] "" Vector__XXX
 SG_ ICR_l2HeapUsage : 14|7@1+ (1,0) [0|0] "" Vector__XXX
 SG_ ICR_intrusionStatus : 21|2@1+ (1,0) [0|0] "" Vector__XXX

BO_ 667 ICR_nonLocalizedOccupancy: 8 Vector__XXX
 SG_ ICR_lifePresenceMLOutput : 0|8@1+ (0.004,0) [0|0] "" Vector__XXX
 SG_ ICR_userPresenceMLOutput : 8|8@1+ (0.004,0) [0|0] "" Vector__XXX
 SG_ ICR_lifePresenceRaw : 16|2@1+ (1,0) [0|0] "" Vector__XXX
 SG_ ICR_lifePresenceFilt : 18|2@1+ (1,0) [0|0] "" Vector__XXX
 SG_ ICR_userPresenceRaw : 20|2@1+ (1,0) [0|0] "" Vector__XXX
 SG_ ICR_userPresenceFilt : 22|2@1+ (1,0) [0|0] "" Vector__XXX
 SG_ ICR_childPresenceFunctionality : 24|2@1+ (1,0) [0|0] "" Vector__XXX

BO_ 669 CP_dcChargeStatus: 8 Vector__XXX
 SG_ CP_evseOutputDcCurrent : 0|15@1- (0.125,0) [0|0] "" Vector__XXX
 SG_ CP_evseOutputDcVoltage : 16|13@1+ (0.07324218755,0) [0|0] "" Vector__XXX
 SG_ CP_evseOutputDcCurrentStale : 29|1@1+ (1,0) [0|0] "" Vector__XXX

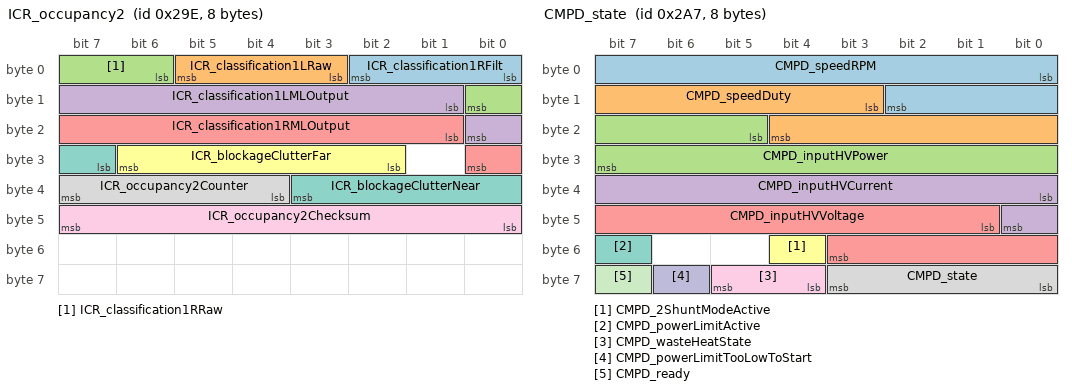
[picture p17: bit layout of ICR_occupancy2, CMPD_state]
BO_ 670 ICR_occupancy2: 8 Vector__XXX
 SG_ ICR_classification1RFilt : 0|3@1+ (1,0) [0|0] "" Vector__XXX
 SG_ ICR_classification1LRaw : 3|3@1+ (1,0) [0|0] "" Vector__XXX
 SG_ ICR_classification1RRaw : 6|3@1+ (1,0) [0|0] "" Vector__XXX
 SG_ ICR_classification1LMLOutput : 9|8@1+ (0.004,0) [0|0] "" Vector__XXX
 SG_ ICR_classification1RMLOutput : 17|8@1+ (0.004,0) [0|0] "" Vector__XXX
 SG_ ICR_blockageClutterFar : 26|5@1- (0.5,-1.5) [0|0] "" Vector__XXX
 SG_ ICR_blockageClutterNear : 31|5@1- (0.5,-1.5) [0|0] "" Vector__XXX
 SG_ ICR_occupancy2Counter : 36|4@1+ (1,0) [0|0] "" Vector__XXX
 SG_ ICR_occupancy2Checksum : 40|8@1+ (1,0) [0|0] "" Vector__XXX

BO_ 673 VCFRONT_CMPDRequest: 8 Vector__XXX
 SG_ VCFRONT_CMPDTargetDuty : 0|16@1+ (0.1,0) [0|0] "" Vector__XXX
 SG_ VCFRONT_CMPDPowerLimit : 16|16@1+ (1,0) [0|0] "" Vector__XXX
 SG_ VCFRONT_CMPDReset : 32|1@1+ (1,0) [0|0] "" Vector__XXX
 SG_ VCFRONT_CMPDEnable : 40|1@1+ (1,0) [0|0] "" Vector__XXX
 SG_ VCFRONT_CMPDWasteHeatRequest : 41|2@1+ (1,0) [0|0] "" Vector__XXX
 SG_ VCFRONT_CMPDWriteFlash : 43|1@1+ (1,0) [0|0] "" Vector__XXX
 SG_ VCFRONT_CMPDSoftStartEnable : 44|1@1+ (1,0) [0|0] "" Vector__XXX

BO_ 674 BMS_rippleRequest: 8 Vector__XXX
 SG_ BMS_acRippleCurrentAmplitudeLimit : 0|10@1+ (1,0) [0|0] "" Vector__XXX
 SG_ BMS_acRippleMaxVoltageLimit : 10|10@1+ (1,0) [0|0] "" Vector__XXX
 SG_ BMS_acRippleMinVoltageLimit : 20|10@1+ (1,0) [0|0] "" Vector__XXX
 SG_ BMS_acRippleFrequencyRequest : 30|10@1+ (1,0) [0|0] "" Vector__XXX
 SG_ BMS_acRippleCurrentAmplitudeRequest : 40|10@1+ (1,0) [0|0] "" Vector__XXX
 SG_ BMS_acRippleRequest : 50|3@1+ (1,0) [0|0] "" Vector__XXX

BO_ 675 BMS_rippleDiagnostics: 8 Vector__XXX
 SG_ BMS_acRippleStateInternal : 0|3@1+ (1,0) [0|0] "" Vector__XXX
 SG_ BMS_acRippleMeasuredFrequency : 8|6@1+ (1,80) [0|0] "" Vector__XXX
 SG_ BMS_acRippleMeasuredCurrentAmplitude : 14|9@1+ (1,0) [0|0] "" Vector__XXX
 SG_ BMS_acRippleMeasuredVoltageAmplitude : 23|9@1+ (1,0) [0|0] "" Vector__XXX
 SG_ BMS_acRippleMeasuredRmsCurrent : 32|9@1+ (1,0) [0|0] "" Vector__XXX
 SG_ BMS_acRippleCurrentAmplitudeTarget : 41|9@1+ (1,0) [0|0] "" Vector__XXX

BO_ 676 PCS_thermalStatus: 8 Vector__XXX
 SG_ PCS_chgPhATemp : 0|11@1- (0.1,40) [0|0] "" Vector__XXX
 SG_ PCS_chgPhBTemp : 11|11@1- (0.1,40) [0|0] "" Vector__XXX
 SG_ PCS_chgPhCTemp : 22|11@1- (0.1,40) [0|0] "" Vector__XXX
 SG_ PCS_dcdcTemp : 33|11@1- (0.1,40) [0|0] "" Vector__XXX
 SG_ PCS_ambientTemp : 44|11@1- (0.1,40) [0|0] "" Vector__XXX
 SG_ PCS_dcdcBusbarTemp : 55|9@1+ (0.29354207436399216,0) [0|0] "" Vector__XXX

BO_ 678 CMPD_motorState: 8 Vector__XXX
 SG_ CMPD_motorCurrent : 0|16@1+ (0.1,0) [0|0] "" Vector__XXX
 SG_ CMPD_motorOverloadCountdown : 16|13@1+ (1,0) [0|0] "" Vector__XXX

BO_ 679 CMPD_state: 8 Vector__XXX
 SG_ CMPD_speedRPM : 0|11@1+ (10,0) [0|0] "" Vector__XXX
 SG_ CMPD_speedDuty : 11|10@1+ (0.1,0) [0|0] "" Vector__XXX
 SG_ CMPD_inputHVPower : 21|11@1+ (10,0) [0|0] "" Vector__XXX
 SG_ CMPD_inputHVCurrent : 32|9@1+ (0.1,0) [0|0] "" Vector__XXX
 SG_ CMPD_inputHVVoltage : 41|11@1+ (0.5,0) [0|0] "" Vector__XXX
 SG_ CMPD_2ShuntModeActive : 52|1@1+ (1,0) [0|0] "" Vector__XXX
 SG_ CMPD_powerLimitActive : 55|1@1+ (1,0) [0|0] "" Vector__XXX
 SG_ CMPD_state : 56|4@1+ (1,0) [0|0] "" Vector__XXX
 SG_ CMPD_wasteHeatState : 60|2@1+ (1,0) [0|0] "" Vector__XXX
 SG_ CMPD_powerLimitTooLowToStart : 62|1@1+ (1,0) [0|0] "" Vector__XXX
 SG_ CMPD_ready : 63|1@1+ (1,0) [0|0] "" Vector__XXX

BO_ 680 EPBL_status: 8 Vector__XXX
 SG_ EPBL_systemStatus : 0|4@1+ (1,0) [0|0] "" Vector__XXX
 SG_ EPBL_freeRollModeStatus : 4|2@1+ (1,0) [0|0] "" Vector__XXX
 SG_ EPBL_driverIsLeaving : 6|1@1+ (1,0) [0|0] "" Vector__XXX
 SG_ EPBL_driverIsLeavingAnySpeed : 7|1@1+ (1,0) [0|0] "" Vector__XXX
 SG_ EPBL_systemCdpAvailable : 8|1@1+ (1,0) [0|0] "" Vector__XXX
 SG_ EPBL_chimeRequest : 9|3@1+ (1,0) [0|0] "" Vector__XXX
 SG_ EPBL_telltale : 12|3@1+ (1,0) [0|0] "" Vector__XXX
 SG_ EPBL_contactorCycleNotNeededForWinchEntry : 15|1@1+ (1,0) [0|0] "" Vector__XXX
 SG_ EPBL_redundantBrakingEnabled : 16|1@1+ (1,0) [0|0] "" Vector__XXX
 SG_ EPBL_summonEnabled : 17|1@1+ (1,0) [0|0] "" Vector__XXX
 SG_ EPBL_brakeLight : 18|1@1+ (1,0) [0|0] "" Vector__XXX
 SG_ EPBL_epbConfigMismatch : 19|1@1+ (1,0) [0|0] "" Vector__XXX
 SG_ EPBL_brakeConfirmedPressed : 20|1@1+ (1,0) [0|0] "" Vector__XXX
 SG_ EPBL_requestUserConfirmation : 21|1@1+ (1,0) [0|0] "" Vector__XXX
 SG_ EPBL_uiWinchModeMiscBlocking : 22|1@1+ (1,0) [0|0] "" Vector__XXX
 SG_ EPBL_winchModeActive : 23|1@1+ (1,0) [0|0] "" Vector__XXX
 SG_ EPBL_updateMode : 24|1@1+ (1,0) [0|0] "" Vector__XXX
 SG_ EPBL_winchModePermissive : 25|1@1+ (1,0) [0|0] "" Vector__XXX
 SG_ EPBL_winchModePending : 26|1@1+ (1,0) [0|0] "" Vector__XXX
 SG_ EPBL_cdpRequest : 27|1@1+ (1,0) [0|0] "" Vector__XXX
 SG_ EPBL_uiParkAvailable : 28|2@1+ (1,0) [0|0] "" Vector__XXX
 SG_ EPBL_brakeDiscWipeRequest : 30|2@1+ (1,0) [0|0] "" Vector__XXX
 SG_ EPBL_showUiGearShifter : 32|1@1+ (1,0) [0|0] "" Vector__XXX
 SG_ EPBL_uiWinchModeLvStatus : 33|2@1+ (1,0) [0|0] "" Vector__XXX
 SG_ EPBL_showStalkFaultedOnUi : 45|1@1+ (1,0) [0|0] "" Vector__XXX
 SG_ EPBL_espPowerRequest : 46|1@1+ (1,0) [0|0] "" Vector__XXX
 SG_ EPBL_okToPark : 47|1@1+ (1,0) [0|0] "" Vector__XXX
 SG_ EPBL_hornRequest : 48|1@1+ (1,0) [0|0] "" Vector__XXX
 SG_ EPBL_winchModeAvailable : 49|1@1+ (1,0) [0|0] "" Vector__XXX
 SG_ EPBL_bothDisconnected : 50|1@1+ (1,0) [0|0] "" Vector__XXX
 SG_ EPBL_blockDrive : 51|1@1+ (1,0) [0|0] "" Vector__XXX
 SG_ EPBL_statusCounter : 52|4@1+ (1,0) [0|0] "" Vector__XXX
 SG_ EPBL_statusChecksum : 56|8@1+ (1,0) [0|0] "" Vector__XXX

BO_ 691 VCRIGHT_logging1Hz: 8 Vector__XXX
 SG_ VCRIGHT_logging1HzIndex M : 0|5@1+ (1,0) [0|0] "" Vector__XXX
 SG_ VCRIGHT_cabinOverheatProtectNotRunningReasonRaw m15 : 5|14@1+ (1,0) [0|0] "" Vector__XXX
 SG_ VCRIGHT_convectionTargetLeft m4 : 5|9@1+ (4,-1000) [0|0] "" Vector__XXX
 SG_ VCRIGHT_hvacCabOvrheatProtActive m8 : 5|1@1+ (1,0) [0|0] "" Vector__XXX
 SG_ VCRIGHT_hvacFoggingRiskLevelFeedforwardConservativeEst m5 : 5|6@1+ (1.6,0) [0|0] "" Vector__XXX
 SG_ VCRIGHT_hvacMassflowTargetLeft m12 : 5|8@1+ (1,0) [0|0] "" Vector__XXX
 SG_ VCRIGHT_leftHeatOvertempProtect m9 : 5|1@1+ (1,0) [0|0] "" Vector__XXX
 SG_ VCRIGHT_lumbarCurrent m10 : 5|4@1+ (0.2,0) [0|0] "" Vector__XXX
 SG_ VCRIGHT_maxMassflowScalar m13 : 5|6@1+ (1,60) [0|0] "" Vector__XXX
 SG_ VCRIGHT_pcbaTemperature m2 : 5|11@1+ (0.125,-40) [0|0] "" Vector__XXX
 SG_ VCRIGHT_steeringWheelSurfaceTempEst m14 : 5|10@1+ (0.1,-35) [0|0] "" Vector__XXX
 SG_ VCRIGHT_hvacCabinPurgeAllowed m8 : 6|1@1+ (1,0) [0|0] "" Vector__XXX
 SG_ VCRIGHT_rightHeatOvertempProtect m9 : 6|1@1+ (1,0) [0|0] "" Vector__XXX
 SG_ VCRIGHT_CO2ppm m9 : 7|10@1+ (5,0) [0|0] "" Vector__XXX
 SG_ VCRIGHT_hvacCabOvrheatProtAllowed m8 : 7|1@1+ (1,0) [0|0] "" Vector__XXX
 SG_ VCRIGHT_cabinTempBreathLevelFHeating m7 : 8|8@1+ (0.5,-40) [0|0] "" Vector__XXX
 SG_ VCRIGHT_cabinTempGlassRoof m1 : 8|8@1+ (0.5,-40) [0|0] "" Vector__XXX
 SG_ VCRIGHT_filterLifeBlowerTorque m8 : 8|10@1+ (0.006,-1.5) [0|0] "" Vector__XXX
 SG_ VCRIGHT_hvacEstimatedCameraWindshieldRH m16 : 8|8@1+ (1,0) [0|0] "" Vector__XXX
 SG_ VCRIGHT_hvacLHBleedVoltage m6 : 8|8@1+ (0.02,0) [0|0] "" Vector__XXX
 SG_ VCRIGHT_hvacSetTempActualLeft m3 : 8|8@1+ (0.1,15) [0|0] "" Vector__XXX
 SG_ VCRIGHT_tempIncarCabinProbe m0 : 8|8@1+ (0.5,-40) [0|0] "" Vector__XXX
 SG_ VCRIGHT_trunkInteriorLEDCurrent m11 : 8|4@1+ (5,0) [0|0] "" Vector__XXX
 SG_ VCRIGHT_ocsCurrent m10 : 9|3@1+ (0.01,0) [0|0] "" Vector__XXX
 SG_ VCRIGHT_hvacFoggingRiskLevelFeedforwardConservativeTar m5 : 11|6@1+ (1.6,0) [0|0] "" Vector__XXX
 SG_ VCRIGHT_massflowTargetAutoInManualMode m13 : 11|8@1+ (1,0) [0|0] "" Vector__XXX
 SG_ VCRIGHT_mapPocketLEDsCurrent m11 : 12|4@1+ (5,0) [0|0] "" Vector__XXX
 SG_ VCRIGHT_rcmCurrent m10 : 12|5@1+ (0.1,0) [0|0] "" Vector__XXX
 SG_ VCRIGHT_hvacMassflowTargetRight m12 : 13|8@1+ (1,0) [0|0] "" Vector__XXX
 SG_ VCRIGHT_convectionTargetRight m4 : 14|9@1+ (4,-1000) [0|0] "" Vector__XXX
 SG_ VCRIGHT_cabinTempBreathLevelFCooling m7 : 16|8@1+ (0.5,-40) [0|0] "" Vector__XXX
 SG_ VCRIGHT_cabinTempInteriorL2 m0 : 16|8@1+ (0.5,-40) [0|0] "" Vector__XXX
 SG_ VCRIGHT_cabinTempWindshield m1 : 16|8@1+ (0.5,-40) [0|0] "" Vector__XXX
 SG_ VCRIGHT_hvacRHBleedVoltage m6 : 16|8@1+ (0.02,0) [0|0] "" Vector__XXX
 SG_ VCRIGHT_hvacSetTempActualRight m3 : 16|8@1+ (0.1,15) [0|0] "" Vector__XXX
 SG_ VCRIGHT_miscEFuseCurrent m11 : 16|5@1+ (0.05,0) [0|0] "" Vector__XXX
 SG_ VCRIGHT_steeringWheelSurfaceTempTgt m14 : 16|10@1+ (0.1,-35) [0|0] "" Vector__XXX
 SG_ VCRIGHT_wattsHeaterLeftTotal m2 : 16|10@1+ (5,0) [0|0] "" Vector__XXX
 SG_ VCRIGHT_hvacFoggingRiskLevelConservativeTar m5 : 17|6@1+ (1.6,0) [0|0] "" Vector__XXX
 SG_ VCRIGHT_radioTunerCurrent m10 : 17|4@1+ (0.1,0) [0|0] "" Vector__XXX
 SG_ VCRIGHT_timeLeftToCabinModelInit m9 : 17|7@1+ (1,0) [0|0] "" Vector__XXX
 SG_ VCRIGHT_cabinTempFanCurrent m8 : 18|6@1+ (0.001,-0.01) [0|0] "" Vector__XXX
 SG_ VCRIGHT_airflowReasonAutoInManualMode m13 : 19|5@1+ (1,0) [0|0] "" Vector__XXX
 SG_ VCRIGHT_hvacIntakeReason m15 : 19|5@1+ (1,0) [0|0] "" Vector__XXX
 SG_ VCRIGHT_interiorHandleLEDCurrent m11 : 21|4@1+ (2,0) [0|0] "" Vector__XXX
 SG_ VCRIGHT_rearOilPumpCurrent m10 : 21|5@1+ (0.5,0) [0|0] "" Vector__XXX
 SG_ VCRIGHT_solarLoadLeftOccupantFilt m12 : 21|7@1+ (2,0) [0|0] "" Vector__XXX
 SG_ VCRIGHT_convectionDeliveredLeft m4 : 23|9@1+ (4,-1000) [0|0] "" Vector__XXX
 SG_ VCRIGHT_ptcHeaterTempDuctHigh m5 : 23|1@1+ (1,0) [0|0] "" Vector__XXX
 SG_ VCRIGHT_airflowReasonAutoInManualModeLeft m13 : 24|5@1+ (1,0) [0|0] "" Vector__XXX
 SG_ VCRIGHT_cabinTempFanOutput m8 : 24|1@1+ (1,0) [0|0] "" Vector__XXX
 SG_ VCRIGHT_cabinTempInterior m1 : 24|8@1+ (0.5,-40) [0|0] "" Vector__XXX
 SG_ VCRIGHT_cabinTempInteriorFHeating m7 : 24|8@1+ (0.5,-40) [0|0] "" Vector__XXX
 SG_ VCRIGHT_cabinTempInteriorSunnyL2 m0 : 24|8@1+ (0.6,-40) [0|0] "" Vector__XXX
 SG_ VCRIGHT_cabinTempRoofL2 m16 : 24|8@1+ (0.5,-40) [0|0] "" Vector__XXX
 SG_ VCRIGHT_hvacAutoTransitionReason m3 : 24|5@1+ (1,0) [0|0] "" Vector__XXX
 SG_ VCRIGHT_hvacCabinPurgeActive m15 : 24|1@1+ (1,0) [0|0] "" Vector__XXX
 SG_ VCRIGHT_hvacEstimateWindshieldRH m9 : 24|8@1+ (1,0) [0|0] "" Vector__XXX
 SG_ VCRIGHT_hvacLHVaneVoltage m6 : 24|8@1+ (0.02,0) [0|0] "" Vector__XXX
 SG_ VCRIGHT_ptcHeaterTempDuctFault m5 : 24|1@1+ (1,0) [0|0] "" Vector__XXX
 SG_ VCRIGHT_cloudinessEstimatedPct m8 : 25|7@1+ (1,0) [0|0] "" Vector__XXX
 SG_ VCRIGHT_miscInteriorLightsCurrent m11 : 25|3@1+ (5,0) [0|0] "" Vector__XXX
 SG_ VCRIGHT_ptcHeaterNoAirflow m5 : 25|1@1+ (1,0) [0|0] "" Vector__XXX
 SG_ VCRIGHT_solarAzimuthCarRef m15 : 25|11@1- (0.5,0) [0|0] "" Vector__XXX
 SG_ VCRIGHT_ptcHeaterHvacActNotReady m5 : 26|1@1+ (1,0) [0|0] "" Vector__XXX
 SG_ VCRIGHT_rearDefrostCurrent m10 : 26|5@1+ (2,0) [0|0] "" Vector__XXX
 SG_ VCRIGHT_timeToComfortHeating m14 : 26|6@1+ (15,-15) [0|0] "" Vector__XXX
 SG_ VCRIGHT_wattsHeaterRightTotal m2 : 26|10@1+ (5,0) [0|0] "" Vector__XXX
 SG_ VCRIGHT_ptcHeaterNoUiRequest m5 : 27|1@1+ (1,0) [0|0] "" Vector__XXX
 SG_ VCRIGHT_frontPuddleLEDCurrent m11 : 28|3@1+ (0.05,0) [0|0] "" Vector__XXX
 SG_ VCRIGHT_ptcHeaterNoHighVoltage m5 : 28|1@1+ (1,0) [0|0] "" Vector__XXX
 SG_ VCRIGHT_solarLoadRightOccupantFilt m12 : 28|7@1+ (2,0) [0|0] "" Vector__XXX
 SG_ VCRIGHT_airflowReasonAutoInManualModeRight m13 : 29|5@1+ (1,0) [0|0] "" Vector__XXX
 SG_ VCRIGHT_hvacMassflowTarget m3 : 29|8@1+ (1,0) [0|0] "" Vector__XXX
 SG_ VCRIGHT_ptcHeaterLAirPathBlocked m5 : 29|1@1+ (1,0) [0|0] "" Vector__XXX
 SG_ VCRIGHT_ptcHeaterRAirPathBlocked m5 : 30|1@1+ (1,0) [0|0] "" Vector__XXX
 SG_ VCRIGHT_ptcHeaterReqAirpathBlocked m5 : 31|1@1+ (1,0) [0|0] "" Vector__XXX
 SG_ VCRIGHT_rearPuddleLEDCurrent m11 : 31|3@1+ (0.05,0) [0|0] "" Vector__XXX
 SG_ VCRIGHT_tailLightCurrent m10 : 31|4@1+ (0.1,0) [0|0] "" Vector__XXX
 SG_ VCRIGHT_cabinTempInteriorSunny m1 : 32|8@1+ (0.6,-40) [0|0] "" Vector__XXX
 SG_ VCRIGHT_cabinTempRoofL3 m16 : 32|8@1+ (0.5,-40) [0|0] "" Vector__XXX
 SG_ VCRIGHT_convectionDeliveredRight m4 : 32|9@1+ (4,-1000) [0|0] "" Vector__XXX
 SG_ VCRIGHT_hvacFoggingRiskLevel m9 : 32|7@1+ (1,0) [0|0] "" Vector__XXX
 SG_ VCRIGHT_hvacFoggingRiskLevelConservativeEst m7 : 32|6@1+ (1.6,0) [0|0] "" Vector__XXX
 SG_ VCRIGHT_hvacQdotFeedforward m5 : 32|16@1+ (1,-32767) [0|0] "" Vector__XXX
 SG_ VCRIGHT_hvacRHVaneVoltage m6 : 32|8@1+ (0.02,0) [0|0] "" Vector__XXX
 SG_ VCRIGHT_solarLoadOnVehFiltered m8 : 32|8@1+ (4,0) [0|0] "" Vector__XXX
 SG_ VCRIGHT_tempIncarCabinMid m0 : 32|8@1+ (0.5,-40) [0|0] "" Vector__XXX
 SG_ VCRIGHT_timeToComfortCooling m14 : 32|6@1+ (15,-15) [0|0] "" Vector__XXX
 SG_ VCRIGHT_cabinTempInteriorFCooling m13 : 34|8@1+ (0.5,-40) [0|0] "" Vector__XXX
 SG_ VCRIGHT_liftgateShutfaceLEDCurrent m11 : 34|3@1+ (5,0) [0|0] "" Vector__XXX
 SG_ VCRIGHT_turnTailStopLightCurrent m10 : 35|4@1+ (0.1,0) [0|0] "" Vector__XXX
 SG_ VCRIGHT_windshieldRHCapped m12 : 35|8@1+ (1,0) [0|0] "" Vector__XXX
 SG_ VCRIGHT_massflowPulldownBias m15 : 36|4@1+ (7,0) [0|0] "" Vector__XXX
 SG_ VCRIGHT_qdotLeftFFUnsat m2 : 36|9@1- (10,0) [0|0] "" Vector__XXX
 SG_ VCRIGHT_3rSeatTOSCurrent m11 : 37|4@1+ (5,0) [0|0] "" Vector__XXX
 SG_ VCRIGHT_hvacQdotLimitedLeft m3 : 37|1@1+ (1,0) [0|0] "" Vector__XXX
 SG_ VCRIGHT_hvacQdotLimitedRight m3 : 38|1@1+ (1,0) [0|0] "" Vector__XXX
 SG_ VCRIGHT_hvacWindshieldRHConservativeEst m7 : 38|6@1+ (2,0) [0|0] "" Vector__XXX
 SG_ VCRIGHT_LHPanelAirflowBlocked m3 : 39|1@1+ (1,0) [0|0] "" Vector__XXX
 SG_ VCRIGHT_hvacCabinHumidityLevel m9 : 39|7@1+ (1,0) [0|0] "" Vector__XXX
 SG_ VCRIGHT_reverseFogLightsCurrent m10 : 39|4@1+ (0.1,0) [0|0] "" Vector__XXX
 SG_ VCRIGHT_RHPanelAirflowBlocked m3 : 40|1@1+ (1,0) [0|0] "" Vector__XXX
 SG_ VCRIGHT_cabinTempInteriorL3 m0 : 40|8@1+ (0.5,-40) [0|0] "" Vector__XXX
 SG_ VCRIGHT_cabinTempProbeEstimate m8 : 40|8@1+ (0.5,-40) [0|0] "" Vector__XXX
 SG_ VCRIGHT_cabinTempSideGlassLeft m1 : 40|8@1+ (0.5,-40) [0|0] "" Vector__XXX
 SG_ VCRIGHT_cabinWaterMassRaw m14 : 40|8@1+ (0.1,0) [0|0] "" Vector__XXX
 SG_ VCRIGHT_evapPulldownBias m15 : 40|4@1+ (7,0) [0|0] "" Vector__XXX
 SG_ VCRIGHT_hvacUpperModeVoltage m6 : 40|8@1+ (0.02,0) [0|0] "" Vector__XXX
 SG_ VCRIGHT_floorAirflowBlocked m3 : 41|1@1+ (1,0) [0|0] "" Vector__XXX
 SG_ VCRIGHT_solarLoadRightOccupant m4 : 41|7@1+ (2,0) [0|0] "" Vector__XXX
 SG_ VCRIGHT_vbatFusedCurrent m11 : 41|4@1+ (0.1,0) [0|0] "" Vector__XXX
 SG_ VCRIGHT_averageDuctTempFHeating m13 : 42|8@1+ (0.5,-40) [0|0] "" Vector__XXX
 SG_ VCRIGHT_defrostAirflowBlocked m3 : 42|1@1+ (1,0) [0|0] "" Vector__XXX
 SG_ VCRIGHT_feedbackWarmUpScalar m12 : 43|2@1+ (16,84) [0|0] "" Vector__XXX
 SG_ VCRIGHT_hvacFilterLifeDetectActive m3 : 43|1@1+ (1,0) [0|0] "" Vector__XXX
 SG_ VCRIGHT_stopReverseTurnLightCurrent m10 : 43|4@1+ (0.1,0) [0|0] "" Vector__XXX
 SG_ VCRIGHT_hvacFoggingRiskLevelFeedback m7 : 44|7@1- (1.6,0) [0|0] "" Vector__XXX
 SG_ VCRIGHT_hvacLHBleedOperationMode m3 : 44|1@1+ (1,0) [0|0] "" Vector__XXX
 SG_ VCRIGHT_modeledMassflowFresh m15 : 44|8@1+ (1,0) [0|0] "" Vector__XXX
 SG_ VCRIGHT_cabinTempGlassGridHeater m11 : 45|8@1+ (0.5,-40) [0|0] "" Vector__XXX
 SG_ VCRIGHT_hvacRHBleedOperationMode m3 : 45|1@1+ (1,0) [0|0] "" Vector__XXX
 SG_ VCRIGHT_maxMassflowScalarWarmUp m12 : 45|5@1+ (1,74) [0|0] "" Vector__XXX
 SG_ VCRIGHT_qdotRightFFUnsat m2 : 45|9@1- (10,0) [0|0] "" Vector__XXX
 SG_ VCRIGHT_hvacLHVaneOperationMode m3 : 46|1@1+ (1,0) [0|0] "" Vector__XXX
 SG_ VCRIGHT_hvacFlashFoggingDetected m9 : 47|1@1+ (1,0) [0|0] "" Vector__XXX
 SG_ VCRIGHT_hvacRHVaneOperationMode m3 : 47|1@1+ (1,0) [0|0] "" Vector__XXX
 SG_ VCRIGHT_sideMirrorCurrent m10 : 47|5@1+ (0.2,0) [0|0] "" Vector__XXX
 SG_ VCRIGHT_cabinTempInteriorSunnyL3 m0 : 48|8@1+ (0.6,-40) [0|0] "" Vector__XXX
 SG_ VCRIGHT_cabinTempSideGlassRight m1 : 48|8@1+ (0.5,-40) [0|0] "" Vector__XXX
 SG_ VCRIGHT_cabinTempThs m8 : 48|8@1+ (0.5,-40) [0|0] "" Vector__XXX
 SG_ VCRIGHT_cabinTempWshldDefog m5 : 48|8@1+ (0.5,-40) [0|0] "" Vector__XXX
 SG_ VCRIGHT_hvacLowerModeVoltage m6 : 48|8@1+ (0.02,0) [0|0] "" Vector__XXX
 SG_ VCRIGHT_hvacUpperModeOpMode m3 : 48|1@1+ (1,0) [0|0] "" Vector__XXX
 SG_ VCRIGHT_massflowSingleZoneSplit m14 : 48|7@1+ (1,0) [0|0] "" Vector__XXX
 SG_ VCRIGHT_solarLoadLeftOccupant m4 : 48|7@1+ (2,0) [0|0] "" Vector__XXX
 SG_ VCRIGHT_solarSensitivityInfr m9 : 48|7@1+ (1,0) [0|0] "" Vector__XXX
 SG_ VCRIGHT_hvacLowerModeOpMode m3 : 49|1@1+ (1,0) [0|0] "" Vector__XXX
 SG_ VCRIGHT_averageDuctTempFCooling m13 : 50|8@1+ (0.5,-40) [0|0] "" Vector__XXX
 SG_ VCRIGHT_feedforwardWarmUpScalar m12 : 50|6@1+ (1,80) [0|0] "" Vector__XXX
 SG_ VCRIGHT_hvacIntakeOperationMode m3 : 50|1@1+ (1,0) [0|0] "" Vector__XXX
 SG_ VCRIGHT_hvacFoggingRiskLevelIntegral m7 : 51|7@1- (1.6,0) [0|0] "" Vector__XXX
 SG_ VCRIGHT_isProbeFeedbackApplied m3 : 52|3@1+ (1,0) [0|0] "" Vector__XXX
 SG_ VCRIGHT_modeledMassflowRecirc m15 : 52|8@1+ (1,0) [0|0] "" Vector__XXX
 SG_ VCRIGHT_sideMirrorHeaterCurrent m10 : 52|5@1+ (0.2,0) [0|0] "" Vector__XXX
 SG_ VCRIGHT_hvacAirflowReasonRight m11 : 53|5@1+ (1,0) [0|0] "" Vector__XXX
 SG_ VCRIGHT_nvhLevelDb m2 : 54|9@1+ (0.1,30) [0|0] "" Vector__XXX
 SG_ VCRIGHT_feedbackPullDownScalar m3 : 55|2@1+ (30,70) [0|0] "" Vector__XXX
 SG_ VCRIGHT_ptcShutOutletMitigationActive m4 : 55|1@1+ (1,0) [0|0] "" Vector__XXX
 SG_ VCRIGHT_solarSensitivityInfrCorr m9 : 55|7@1+ (1,0) [0|0] "" Vector__XXX
 SG_ VCRIGHT_VOCPurgeState m14 : 56|3@1+ (1,0) [0|0] "" Vector__XXX
 SG_ VCRIGHT_cabinTempBreathLevel m1 : 56|8@1+ (0.5,-40) [0|0] "" Vector__XXX
 SG_ VCRIGHT_cabinTempThsBracket m8 : 56|8@1+ (0.5,-40) [0|0] "" Vector__XXX
 SG_ VCRIGHT_cabinTempWshldDefogTop m5 : 56|8@1+ (0.5,-40) [0|0] "" Vector__XXX
 SG_ VCRIGHT_frontSeatHeatBackrestPwr m12 : 56|7@1+ (1,0) [0|0] "" Vector__XXX
 SG_ VCRIGHT_hvacIntakeVoltage m6 : 56|8@1+ (0.02,0) [0|0] "" Vector__XXX
 SG_ VCRIGHT_solarLoadFromThsTemp m4 : 56|8@1+ (8,-1020) [0|0] "" Vector__XXX
 SG_ VCRIGHT_feedForwardPullDownScalar m3 : 57|6@1+ (1,70) [0|0] "" Vector__XXX
 SG_ VCRIGHT_frontSeatHeatCushionPwr m10 : 57|7@1+ (1,0) [0|0] "" Vector__XXX
 SG_ VCRIGHT_hvacAirflowReasonLeft m11 : 58|5@1+ (1,0) [0|0] "" Vector__XXX
 SG_ VCRIGHT_hvacBiLevelWhsldRhEst m13 : 58|6@1+ (2,20) [0|0] "" Vector__XXX
 SG_ VCRIGHT_hvacFoggingRiskLevelFeedforward m7 : 58|6@1+ (1.6,0) [0|0] "" Vector__XXX
 SG_ VCRIGHT_cameraFoggingMonitorState m14 : 59|3@1+ (1,0) [0|0] "" Vector__XXX
 SG_ VCRIGHT_hvacLimpModeStatus m15 : 60|3@1+ (1,0) [0|0] "" Vector__XXX

BO_ 692 PCS_dcdcRailStatus: 8 Vector__XXX
 SG_ PCS_dcdcLvBusVolt : 0|13@1+ (0.01,0) [0|0] "" Vector__XXX
 SG_ PCS_dcdcHvBusVolt : 16|14@1+ (0.1,0) [0|0] "" Vector__XXX
 SG_ PCS_dcdcLvOutputCurrent : 32|13@1- (0.1,0) [0|0] "" Vector__XXX

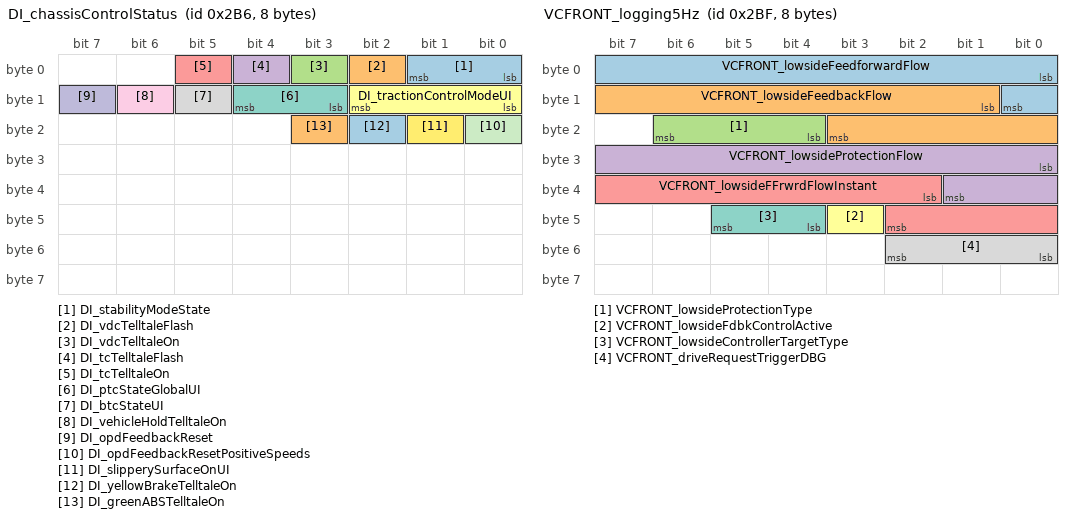
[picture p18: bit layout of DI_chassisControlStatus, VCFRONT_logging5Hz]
BO_ 694 DI_chassisControlStatus: 8 Vector__XXX
 SG_ DI_stabilityModeState : 0|2@1+ (1,0) [0|0] "" Vector__XXX
 SG_ DI_vdcTelltaleFlash : 2|1@1+ (1,0) [0|0] "" Vector__XXX
 SG_ DI_vdcTelltaleOn : 3|1@1+ (1,0) [0|0] "" Vector__XXX
 SG_ DI_tcTelltaleFlash : 4|1@1+ (1,0) [0|0] "" Vector__XXX
 SG_ DI_tcTelltaleOn : 5|1@1+ (1,0) [0|0] "" Vector__XXX
 SG_ DI_tractionControlModeUI : 8|3@1+ (1,0) [0|0] "" Vector__XXX
 SG_ DI_ptcStateGlobalUI : 11|2@1+ (1,0) [0|0] "" Vector__XXX
 SG_ DI_btcStateUI : 13|1@1+ (1,0) [0|0] "" Vector__XXX
 SG_ DI_vehicleHoldTelltaleOn : 14|1@1+ (1,0) [0|0] "" Vector__XXX
 SG_ DI_opdFeedbackReset : 15|1@1+ (1,0) [0|0] "" Vector__XXX
 SG_ DI_opdFeedbackResetPositiveSpeeds : 16|1@1+ (1,0) [0|0] "" Vector__XXX
 SG_ DI_slipperySurfaceOnUI : 17|1@1+ (1,0) [0|0] "" Vector__XXX
 SG_ DI_yellowBrakeTelltaleOn : 18|1@1+ (1,0) [0|0] "" Vector__XXX
 SG_ DI_greenABSTelltaleOn : 19|1@1+ (1,0) [0|0] "" Vector__XXX

BO_ 701 CP_dcPowerLimits: 8 Vector__XXX
 SG_ CP_evseInstantDcPowerLimit : 0|13@1+ (0.25,0) [0|0] "" Vector__XXX
 SG_ CP_evseMaxDcPowerLimit : 16|13@1+ (0.25,0) [0|0] "" Vector__XXX
 SG_ CP_evseInstantDcPowerLimitValid : 29|1@1+ (1,0) [0|0] "" Vector__XXX
 SG_ CP_evseMaxDcPowerLimitValid : 30|1@1+ (1,0) [0|0] "" Vector__XXX

BO_ 702 FC_limitsHighPower: 8 Vector__XXX
 SG_ FC_powerLimit_value : 0|16@1- (1,0) [0|0] "" Vector__XXX
 SG_ FC_currentLimit_value : 16|16@1- (1,0) [0|0] "" Vector__XXX
 SG_ FC_minVoltageLimit_value : 32|16@1- (1,0) [0|0] "" Vector__XXX
 SG_ FC_powerLimit_exp : 48|3@1- (1,0) [0|0] "" Vector__XXX
 SG_ FC_currentLimit_exp : 51|3@1- (1,0) [0|0] "" Vector__XXX
 SG_ FC_minVoltageLimit_exp : 54|3@1- (1,0) [0|0] "" Vector__XXX

BO_ 703 VCFRONT_logging5Hz: 8 Vector__XXX
 SG_ VCFRONT_lowsideFeedforwardFlow : 0|9@1+ (0.2,0) [0|0] "" Vector__XXX
 SG_ VCFRONT_lowsideFeedbackFlow : 9|11@1- (0.1,0) [0|0] "" Vector__XXX
 SG_ VCFRONT_lowsideProtectionType : 20|3@1+ (1,0) [0|0] "" Vector__XXX
 SG_ VCFRONT_lowsideProtectionFlow : 24|10@1+ (0.1,0) [0|0] "" Vector__XXX
 SG_ VCFRONT_lowsideFFrwrdFlowInstant : 34|9@1+ (0.2,0) [0|0] "" Vector__XXX
 SG_ VCFRONT_lowsideFdbkControlActive : 43|1@1+ (1,0) [0|0] "" Vector__XXX
 SG_ VCFRONT_lowsideControllerTargetType : 44|2@1+ (1,0) [0|0] "" Vector__XXX
 SG_ VCFRONT_driveRequestTriggerDBG : 48|3@1+ (1,0) [0|0] "" Vector__XXX

BO_ 705 VCFRONT_logging10Hz: 8 Vector__XXX
 SG_ VCFRONT_logging10HzIndex M : 0|3@1+ (1,0) [0|0] "" Vector__XXX
 SG_ VCFRONT_activeLouverMotorCounts m3 : 3|11@1+ (1,-100) [0|0] "" Vector__XXX
 SG_ VCFRONT_chillerExvTorqueCountAvailable m4 : 3|1@1+ (1,0) [0|0] "" Vector__XXX
 SG_ VCFRONT_pumpBatteryOutVoltage m0 : 3|7@1+ (0.2,0) [0|0] "" Vector__XXX
 SG_ VCFRONT_radiatorFanDemandLimit m1 : 3|7@1+ (1,0) [0|0] "" Vector__XXX
 SG_ VCFRONT_evapExvTorqueCountAvailable m4 : 4|1@1+ (1,0) [0|0] "" Vector__XXX
 SG_ VCFRONT_recircExvTorqueCountAvailable m4 : 5|1@1+ (1,0) [0|0] "" Vector__XXX
 SG_ VCFRONT_lccExvTorqueCountAvailable m4 : 6|1@1+ (1,0) [0|0] "" Vector__XXX
 SG_ VCFRONT_ccLeftExvTorqueCountAvailable m4 : 7|1@1+ (1,0) [0|0] "" Vector__XXX
 SG_ VCFRONT_ccRightExvTorqueCountAvailable m4 : 8|1@1+ (1,0) [0|0] "" Vector__XXX
 SG_ VCFRONT_compRampRateUpMax m2 : 8|7@1+ (0.2,0) [0|0] "" Vector__XXX
 SG_ VCFRONT_pumpPowertrainOutVoltage m0 : 10|7@1+ (0.2,0) [0|0] "" Vector__XXX
 SG_ VCFRONT_radiatorFanDemandLimited m1 : 10|1@1+ (1,0) [0|0] "" Vector__XXX
 SG_ VCFRONT_coolantValveAngleActual m1 : 11|11@1+ (0.25,-100) [0|0] "" Vector__XXX
 SG_ VCFRONT_refrigerantValvesClosed m2 : 15|1@1+ (1,0) [0|0] "" Vector__XXX
 SG_ VCFRONT_activeLouverCalibRange m3 : 16|8@1+ (1,630) [0|0] "" Vector__XXX
 SG_ VCFRONT_chillerExvTorqueCount m4 : 16|8@1+ (1,0) [0|0] "" Vector__XXX
 SG_ VCFRONT_exvMotorState m2 : 16|4@1+ (1,0) [0|0] "" Vector__XXX
 SG_ VCFRONT_pumpBatteryInitd m0 : 17|1@1+ (1,0) [0|0] "" Vector__XXX
 SG_ VCFRONT_pumpPowertrainInitd m0 : 18|1@1+ (1,0) [0|0] "" Vector__XXX
 SG_ VCFRONT_pumpBatteryEnabled m0 : 19|1@1+ (1,0) [0|0] "" Vector__XXX
 SG_ VCFRONT_exvFlow m2 : 20|8@1+ (0.5,0) [0|0] "" Vector__XXX
 SG_ VCFRONT_pumpPowertrainEnabled m0 : 20|1@1+ (1,0) [0|0] "" Vector__XXX
 SG_ VCFRONT_pumpBatteryPowerOn m0 : 21|1@1+ (1,0) [0|0] "" Vector__XXX
 SG_ VCFRONT_coolantValveAngleTarget m1 : 22|10@1+ (0.25,-5) [0|0] "" Vector__XXX
 SG_ VCFRONT_pumpPowertrainPowerOn m0 : 22|1@1+ (1,0) [0|0] "" Vector__XXX
 SG_ VCFRONT_pumpsWake m0 : 23|1@1+ (1,0) [0|0] "" Vector__XXX
 SG_ VCFRONT_evapExvTorqueCount m4 : 24|8@1+ (1,0) [0|0] "" Vector__XXX
 SG_ VCFRONT_pumpBatSpiError m0 : 24|1@1+ (1,0) [0|0] "" Vector__XXX
 SG_ VCFRONT_radarHeaterCurrent m3 : 24|8@1+ (0.1,0) [0|0] "" Vector__XXX
 SG_ VCFRONT_pumpPtSpiError m0 : 25|1@1+ (1,0) [0|0] "" Vector__XXX
 SG_ VCFRONT_coolantFlowChillerActual m0 : 26|8@1+ (0.1,0) [0|0] "" Vector__XXX
 SG_ VCFRONT_exvIsFlooding m2 : 28|1@1+ (1,0) [0|0] "" Vector__XXX
 SG_ VCFRONT_exvPrechillActive m2 : 29|1@1+ (1,0) [0|0] "" Vector__XXX
 SG_ VCFRONT_usingSimulatedSuctTemp m2 : 30|1@1+ (1,0) [0|0] "" Vector__XXX
 SG_ VCFRONT_usingSimulatedDischTemp m2 : 31|1@1+ (1,0) [0|0] "" Vector__XXX
 SG_ VCFRONT_coolantValveState m1 : 32|2@1+ (1,0) [0|0] "" Vector__XXX
 SG_ VCFRONT_radarHeaterDuty m3 : 32|7@1+ (1,0) [0|0] "" Vector__XXX
 SG_ VCFRONT_recircExvTorqueCount m4 : 32|8@1+ (1,0) [0|0] "" Vector__XXX
 SG_ VCFRONT_usingSimulatedAmbTemp m2 : 32|1@1+ (1,0) [0|0] "" Vector__XXX
 SG_ VCFRONT_solenoidEvapCurrent m2 : 33|6@1+ (0.04,0) [0|0] "" Vector__XXX
 SG_ VCFRONT_coolantValveDuty m1 : 34|8@1- (1,0) [0|0] "" Vector__XXX
 SG_ VCFRONT_radiatorFanOutVoltage m0 : 34|7@1+ (0.2,0) [0|0] "" Vector__XXX
 SG_ VCFRONT_activeLouverAbnormalKT m2 : 39|1@1+ (1,0) [0|0] "" Vector__XXX
 SG_ VCFRONT_activeLouverOverCurrent m2 : 40|1@1+ (1,0) [0|0] "" Vector__XXX
 SG_ VCFRONT_lccExvTorqueCount m4 : 40|8@1+ (1,0) [0|0] "" Vector__XXX
 SG_ VCFRONT_radarHeaterTargetVoltage m3 : 40|8@1+ (0.1,0) [0|0] "" Vector__XXX
 SG_ VCFRONT_activeLouverOverTemp m2 : 41|1@1+ (1,0) [0|0] "" Vector__XXX
 SG_ VCFRONT_radiatorFanInitd m0 : 41|1@1+ (1,0) [0|0] "" Vector__XXX
 SG_ VCFRONT_activeLouverDisconnect m2 : 42|1@1+ (1,0) [0|0] "" Vector__XXX
 SG_ VCFRONT_coolantValveISense m1 : 42|5@1+ (0.05,0) [0|0] "" Vector__XXX
 SG_ VCFRONT_radiatorFanEnabled m0 : 42|1@1+ (1,0) [0|0] "" Vector__XXX
 SG_ VCFRONT_activeLouverStalled m2 : 43|1@1+ (1,0) [0|0] "" Vector__XXX
 SG_ VCFRONT_radiatorFanPowerOn m0 : 43|1@1+ (1,0) [0|0] "" Vector__XXX
 SG_ VCFRONT_activeLouverMotorState m2 : 44|3@1+ (1,0) [0|0] "" Vector__XXX
 SG_ VCFRONT_radiatorFanPhaseCurrent m0 : 44|8@1+ (0.25,-10) [0|0] "" Vector__XXX
 SG_ VCFRONT_activeLouverCommSuccess m2 : 47|1@1+ (1,0) [0|0] "" Vector__XXX
 SG_ VCFRONT_compLimitPresDischargeHi m1 : 47|1@1+ (1,0) [0|0] "" Vector__XXX
 SG_ VCFRONT_COP1PdOscillationDetected m3 : 48|1@1+ (1,0) [0|0] "" Vector__XXX
 SG_ VCFRONT_activeLouverStallOL m2 : 48|1@1+ (1,0) [0|0] "" Vector__XXX
 SG_ VCFRONT_ccLeftExvTorqueCount m4 : 48|8@1+ (1,0) [0|0] "" Vector__XXX
 SG_ VCFRONT_compLimitTempDischargeHi m1 : 48|1@1+ (1,0) [0|0] "" Vector__XXX
 SG_ VCFRONT_COP1PdOscillationPurge m3 : 49|1@1+ (1,0) [0|0] "" Vector__XXX
 SG_ VCFRONT_activeLouverIsCalibrated m2 : 49|1@1+ (1,0) [0|0] "" Vector__XXX
 SG_ VCFRONT_compLimitScrollSepRegion m1 : 49|1@1+ (1,0) [0|0] "" Vector__XXX
 SG_ VCFRONT_activeLouverDemand m2 : 50|7@1+ (1,0) [0|0] "" Vector__XXX
 SG_ VCFRONT_compLimitNvh m1 : 50|1@1+ (1,0) [0|0] "" Vector__XXX
 SG_ VCFRONT_wiperHeaterCurrent m3 : 50|9@1+ (0.032,0) [0|0] "" Vector__XXX
 SG_ VCFRONT_compLimitScrollSepRamp m1 : 51|1@1+ (1,0) [0|0] "" Vector__XXX
 SG_ VCFRONT_compLimitDeadband m1 : 52|1@1+ (1,0) [0|0] "" Vector__XXX
 SG_ VCFRONT_radiatorFanPhaseIMax m0 : 52|7@1+ (0.25,5) [0|0] "" Vector__XXX
 SG_ VCFRONT_compStandbySelfNotReady m1 : 53|1@1+ (1,0) [0|0] "" Vector__XXX
 SG_ VCFRONT_compStandbyCommunication m1 : 54|1@1+ (1,0) [0|0] "" Vector__XXX
 SG_ VCFRONT_compStandbyHVNotReady m1 : 55|1@1+ (1,0) [0|0] "" Vector__XXX
 SG_ VCFRONT_ccRightExvTorqueCount m4 : 56|8@1+ (1,0) [0|0] "" Vector__XXX
 SG_ VCFRONT_compStandbyLowAmbient m1 : 56|1@1+ (1,0) [0|0] "" Vector__XXX
 SG_ VCFRONT_activeLouverFalsStallRun m2 : 57|1@1+ (1,0) [0|0] "" Vector__XXX
 SG_ VCFRONT_compStandbyLowDischPress m1 : 57|1@1+ (1,0) [0|0] "" Vector__XXX
 SG_ VCFRONT_activeLouverFalsStallCal m2 : 58|1@1+ (1,0) [0|0] "" Vector__XXX
 SG_ VCFRONT_compStandbyRefrigNotOk m1 : 58|1@1+ (1,0) [0|0] "" Vector__XXX
 SG_ VCFRONT_activeLouverStallCounter m2 : 59|3@1+ (1,0) [0|0] "" Vector__XXX
 SG_ VCFRONT_compStandbyMultiplePdCutouts m1 : 59|1@1+ (1,0) [0|0] "" Vector__XXX
 SG_ VCFRONT_thmlFanSpiError m0 : 59|1@1+ (1,0) [0|0] "" Vector__XXX
 SG_ VCFRONT_chargeTrapNominalCOP1BattHeat m0 : 60|1@1+ (1,0) [0|0] "" Vector__XXX
 SG_ VCFRONT_compStandbyMultipleTdCutouts m1 : 60|1@1+ (1,0) [0|0] "" Vector__XXX
 SG_ VCFRONT_chargeTrapNominalCOP1ChillerBattHeat m0 : 61|1@1+ (1,0) [0|0] "" Vector__XXX
 SG_ VCFRONT_compLimitTempDischargeSim m1 : 61|1@1+ (1,0) [0|0] "" Vector__XXX
 SG_ VCFRONT_COP1OilWarmingActive m1 : 62|1@1+ (1,0) [0|0] "" Vector__XXX
 SG_ VCFRONT_COP1OilWarmingNeeded m0 : 62|1@1+ (1,0) [0|0] "" Vector__XXX
 SG_ VCFRONT_compressorDelayEnabled m2 : 62|1@1+ (1,0) [0|0] "" Vector__XXX
 SG_ VCFRONT_compLimitHvPowerBudget m1 : 63|1@1+ (1,0) [0|0] "" Vector__XXX
 SG_ VCFRONT_compressorDwellEnabled m2 : 63|1@1+ (1,0) [0|0] "" Vector__XXX

BO_ 706 VCLEFT_windowStatus: 8 Vector__XXX
 SG_ VCLEFT_windowStatusIndex M : 0|1@1+ (1,0) [0|0] "" Vector__XXX
 SG_ VCLEFT_windowStateLF m0 : 1|4@1+ (1,0) [0|0] "" Vector__XXX
 SG_ VCLEFT_windowThermalTCLF m1 : 1|8@1+ (1,0) [0|0] "" Vector__XXX
 SG_ VCLEFT_windowTrimClearMoveRequest m0 : 5|2@1+ (1,0) [0|0] "" Vector__XXX
 SG_ VCLEFT_windowDutyLF m0 : 8|6@1- (5,0) [0|0] "" Vector__XXX
 SG_ VCLEFT_windowThermalModeLF m1 : 9|2@1+ (1,0) [0|0] "" Vector__XXX
 SG_ VCLEFT_windowStopReasonLF m1 : 11|3@1+ (1,0) [0|0] "" Vector__XXX
 SG_ VCLEFT_windowStopReqReasonLF m1 : 14|4@1+ (1,0) [0|0] "" Vector__XXX
 SG_ VCLEFT_windowTrimClearActiveRequest m0 : 14|2@1+ (1,0) [0|0] "" Vector__XXX
 SG_ VCLEFT_windowCurrentLF m0 : 16|6@1- (0.5,0) [0|0] "" Vector__XXX
 SG_ VCLEFT_windowThermalTCLR m1 : 18|8@1+ (1,0) [0|0] "" Vector__XXX
 SG_ VCLEFT_windowPositionLF m0 : 22|9@1- (1.25,265) [0|0] "" Vector__XXX
 SG_ VCLEFT_windowThermalModeLR m1 : 26|2@1+ (1,0) [0|0] "" Vector__XXX
 SG_ VCLEFT_windowStopReasonLR m1 : 28|3@1+ (1,0) [0|0] "" Vector__XXX
 SG_ VCLEFT_windowStopReqReasonLR m1 : 31|4@1+ (1,0) [0|0] "" Vector__XXX
 SG_ VCLEFT_windowCalibratedLF m0 : 32|1@1+ (1,0) [0|0] "" Vector__XXX
 SG_ VCLEFT_windowStateLR m0 : 33|4@1+ (1,0) [0|0] "" Vector__XXX
 SG_ VCLEFT_windowControlStateLF m1 : 35|2@1+ (1,0) [0|0] "" Vector__XXX
 SG_ VCLEFT_windowCtrlUnavailableLF m1 : 38|3@1+ (1,0) [0|0] "" Vector__XXX
 SG_ VCLEFT_windowDutyLR m0 : 40|6@1- (5,0) [0|0] "" Vector__XXX
 SG_ VCLEFT_windowControlStateLR m1 : 42|2@1+ (1,0) [0|0] "" Vector__XXX
 SG_ VCLEFT_windowCtrlUnavailableLR m1 : 45|3@1+ (1,0) [0|0] "" Vector__XXX
 SG_ VCLEFT_windowCurrentLR m0 : 48|6@1- (0.5,0) [0|0] "" Vector__XXX
 SG_ VCLEFT_windowPositionStateLF m1 : 49|3@1+ (1,0) [0|0] "" Vector__XXX
 SG_ VCLEFT_windowPositionStateLR m1 : 52|3@1+ (1,0) [0|0] "" Vector__XXX
 SG_ VCLEFT_windowPositionLR m0 : 54|9@1- (1.25,265) [0|0] "" Vector__XXX
 SG_ VCLEFT_windowVehGearStateLF m1 : 56|2@1+ (1,0) [0|0] "" Vector__XXX
 SG_ VCLEFT_windowVehGearStateLR m1 : 58|2@1+ (1,0) [0|0] "" Vector__XXX
 SG_ VCLEFT_windowSpeedTableStatusLF m1 : 60|2@1+ (1,0) [0|0] "" Vector__XXX
 SG_ VCLEFT_windowSpeedTableStatusLR m1 : 62|2@1+ (1,0) [0|0] "" Vector__XXX
 SG_ VCLEFT_windowCalibratedLR m0 : 63|1@1+ (1,0) [0|0] "" Vector__XXX

BO_ 707 VCRIGHT_windowStatus: 8 Vector__XXX
 SG_ VCRIGHT_windowStatusIndex M : 0|1@1+ (1,0) [0|0] "" Vector__XXX
 SG_ VCRIGHT_windowStateRF m0 : 1|4@1+ (1,0) [0|0] "" Vector__XXX
 SG_ VCRIGHT_windowThermalTCRF m1 : 1|8@1+ (1,0) [0|0] "" Vector__XXX
 SG_ VCRIGHT_windowTrimClearMoveRequest m0 : 5|2@1+ (1,0) [0|0] "" Vector__XXX
 SG_ VCRIGHT_windowDutyRF m0 : 8|6@1- (5,0) [0|0] "" Vector__XXX
 SG_ VCRIGHT_windowThermalModeRF m1 : 9|2@1+ (1,0) [0|0] "" Vector__XXX
 SG_ VCRIGHT_windowStopReasonRF m1 : 11|3@1+ (1,0) [0|0] "" Vector__XXX
 SG_ VCRIGHT_windowStopReqReasonRF m1 : 14|4@1+ (1,0) [0|0] "" Vector__XXX
 SG_ VCRIGHT_windowTrimClearActiveRequest m0 : 14|2@1+ (1,0) [0|0] "" Vector__XXX
 SG_ VCRIGHT_windowCurrentRF m0 : 16|6@1- (0.5,0) [0|0] "" Vector__XXX
 SG_ VCRIGHT_windowThermalTCRR m1 : 18|8@1+ (1,0) [0|0] "" Vector__XXX
 SG_ VCRIGHT_windowPositionRF m0 : 22|9@1- (1.25,265) [0|0] "" Vector__XXX
 SG_ VCRIGHT_windowThermalModeRR m1 : 26|2@1+ (1,0) [0|0] "" Vector__XXX
 SG_ VCRIGHT_windowStopReasonRR m1 : 28|3@1+ (1,0) [0|0] "" Vector__XXX
 SG_ VCRIGHT_windowStopReqReasonRR m1 : 31|4@1+ (1,0) [0|0] "" Vector__XXX
 SG_ VCRIGHT_windowCalibratedRF m0 : 32|1@1+ (1,0) [0|0] "" Vector__XXX
 SG_ VCRIGHT_windowStateRR m0 : 33|4@1+ (1,0) [0|0] "" Vector__XXX
 SG_ VCRIGHT_windowControlStateRF m1 : 35|2@1+ (1,0) [0|0] "" Vector__XXX
 SG_ VCRIGHT_windowCtrlUnavailableRF m1 : 38|3@1+ (1,0) [0|0] "" Vector__XXX
 SG_ VCRIGHT_windowDutyRR m0 : 40|6@1- (5,0) [0|0] "" Vector__XXX
 SG_ VCRIGHT_windowControlStateRR m1 : 42|2@1+ (1,0) [0|0] "" Vector__XXX
 SG_ VCRIGHT_windowCtrlUnavailableRR m1 : 45|3@1+ (1,0) [0|0] "" Vector__XXX
 SG_ VCRIGHT_windowCurrentRR m0 : 48|6@1- (0.5,0) [0|0] "" Vector__XXX
 SG_ VCRIGHT_windowPositionStateRF m1 : 49|3@1+ (1,0) [0|0] "" Vector__XXX
 SG_ VCRIGHT_windowPositionStateRR m1 : 52|3@1+ (1,0) [0|0] "" Vector__XXX
 SG_ VCRIGHT_windowPositionRR m0 : 54|9@1- (1.25,265) [0|0] "" Vector__XXX
 SG_ VCRIGHT_windowVehGearStateRF m1 : 56|2@1+ (1,0) [0|0] "" Vector__XXX
 SG_ VCRIGHT_windowVehGearStateRR m1 : 58|2@1+ (1,0) [0|0] "" Vector__XXX
 SG_ VCRIGHT_windowSpeedTableStatusRF m1 : 60|2@1+ (1,0) [0|0] "" Vector__XXX
 SG_ VCRIGHT_windowSpeedTableStatusRR m1 : 62|2@1+ (1,0) [0|0] "" Vector__XXX
 SG_ VCRIGHT_windowCalibratedRR m0 : 63|1@1+ (1,0) [0|0] "" Vector__XXX

BO_ 708 PCS_logging: 8 Vector__XXX
 SG_ PCS_logMessageSelect M : 0|5@1+ (1,0) [0|0] "" Vector__XXX
 SG_ PCS_chgInputFrequencyL1N m4 : 5|12@1+ (0.01,40) [0|0] "" Vector__XXX
 SG_ PCS_chgInputL1NVdc m21 : 5|10@1- (1,0) [0|0] "" Vector__XXX
 SG_ PCS_chgInputL1NVrms m3 : 5|12@1+ (0.2,0) [0|0] "" Vector__XXX
 SG_ PCS_chgPHAInputVPeak10s m13 : 5|9@1+ (1,0) [0|0] "" Vector__XXX
 SG_ PCS_chgPhAInputIrms m0 : 5|9@1+ (0.1,0) [0|0] "" Vector__XXX
 SG_ PCS_chgPhAIntBusVMin10s m10 : 5|9@1+ (1,0) [0|0] "" Vector__XXX
 SG_ PCS_chgPhAMachineEnabled m23 : 5|1@1+ (1,0) [0|0] "" Vector__XXX
 SG_ PCS_chgPhANoFlowBucket m20 : 5|9@1+ (0.01,0) [0|0] "" Vector__XXX
 SG_ PCS_chgPhAState m5 : 5|4@1+ (1,0) [0|0] "" Vector__XXX
 SG_ PCS_chgPhBInputIrms m1 : 5|9@1+ (0.1,0) [0|0] "" Vector__XXX
 SG_ PCS_chgPhBIntBusVMin10s m11 : 5|9@1+ (1,0) [0|0] "" Vector__XXX
 SG_ PCS_chgPhCInputIrms m2 : 5|9@1+ (0.1,0) [0|0] "" Vector__XXX
 SG_ PCS_chgPhCIntBusVMin10s m12 : 5|9@1+ (1,0) [0|0] "" Vector__XXX
 SG_ PCS_cpu2BootState m9 : 5|2@1+ (1,0) [0|0] "" Vector__XXX
 SG_ PCS_dLogPhAChannel1Content m14 : 5|2@1+ (1,0) [0|0] "" Vector__XXX
 SG_ PCS_dLogPhAChannel2Content m15 : 5|2@1+ (1,0) [0|0] "" Vector__XXX
 SG_ PCS_dLogPhAChannel3Content m16 : 5|2@1+ (1,0) [0|0] "" Vector__XXX
 SG_ PCS_dLogPhAChannel4Content m17 : 5|2@1+ (1,0) [0|0] "" Vector__XXX
 SG_ PCS_dcdcPchgStartLvBusVolt m24 : 5|10@1+ (0.0390625,0) [0|0] "" Vector__XXX
 SG_ PCS_dcdcTCommMeasured m8 : 5|16@1- (0.001953125,0) [0|0] "" Vector__XXX
 SG_ PCS_dcdcUnifiedCommand m7 : 5|10@1+ (0.001,0) [0|0] "" Vector__XXX
 SG_ PCS_chgPhAMachineRotorFreqDroop m23 : 6|10@1- (0.01,0) [0|0] "" Vector__XXX
 SG_ PCS_acChargeSelfTestState m9 : 7|1@1+ (1,0) [0|0] "" Vector__XXX
 SG_ PCS_1V5Min10s m9 : 8|11@1+ (0.001,0) [0|0] "" Vector__XXX
 SG_ PCS_dLogPhBChannel1Content m14 : 8|2@1+ (1,0) [0|0] "" Vector__XXX
 SG_ PCS_dLogPhBChannel2Content m15 : 8|2@1+ (1,0) [0|0] "" Vector__XXX
 SG_ PCS_dLogPhBChannel3Content m16 : 8|2@1+ (1,0) [0|0] "" Vector__XXX
 SG_ PCS_dLogPhBChannel4Content m17 : 8|2@1+ (1,0) [0|0] "" Vector__XXX
 SG_ PCS_dcdcIntervalMaxFrequency m18 : 8|12@1+ (1,0) [0|0] "" Vector__XXX
 SG_ PCS_dcdcIntervalMinFrequency m19 : 8|12@1+ (1,0) [0|0] "" Vector__XXX
 SG_ PCS_dcdcLvSupportLifetimekWh m22 : 8|24@1+ (0.01,0) [0|0] "" Vector__XXX
 SG_ PCS_dcdcMaxLvOutputCurrent m6 : 8|12@1+ (0.1,0) [0|0] "" Vector__XXX
 SG_ PCS_processorDieIdLot m25 : 8|24@1+ (1,0) [0|0] "" Vector__XXX
 SG_ PCS_chgPhBState m5 : 9|4@1+ (1,0) [0|0] "" Vector__XXX
 SG_ PCS_dLogPhCChannel1Content m14 : 10|2@1+ (1,0) [0|0] "" Vector__XXX
 SG_ PCS_dLogPhCChannel2Content m15 : 10|2@1+ (1,0) [0|0] "" Vector__XXX
 SG_ PCS_dLogPhCChannel3Content m16 : 10|2@1+ (1,0) [0|0] "" Vector__XXX
 SG_ PCS_dLogPhCChannel4Content m17 : 10|2@1+ (1,0) [0|0] "" Vector__XXX
 SG_ PCS_chgPhCState m5 : 13|4@1+ (1,0) [0|0] "" Vector__XXX
 SG_ PCS_chgPHBInputVPeak10s m13 : 14|9@1+ (1,0) [0|0] "" Vector__XXX
 SG_ PCS_chgPhAIntBusV m0 : 14|9@1+ (1,0) [0|0] "" Vector__XXX
 SG_ PCS_chgPhAIntBusVMax10s m10 : 14|9@1+ (1,0) [0|0] "" Vector__XXX
 SG_ PCS_chgPhBIntBusV m1 : 14|9@1+ (1,0) [0|0] "" Vector__XXX
 SG_ PCS_chgPhBIntBusVMax10s m11 : 14|9@1+ (1,0) [0|0] "" Vector__XXX
 SG_ PCS_chgPhBNoFlowBucket m20 : 14|9@1+ (0.01,0) [0|0] "" Vector__XXX
 SG_ PCS_chgPhCIntBusV m2 : 14|9@1+ (1,0) [0|0] "" Vector__XXX
 SG_ PCS_chgPhCIntBusVMax10s m12 : 14|9@1+ (1,0) [0|0] "" Vector__XXX
 SG_ PCS_chgInputL2NVdc m21 : 16|10@1- (1,0) [0|0] "" Vector__XXX
 SG_ PCS_chgPhAMachineStatorCurrent m23 : 16|8@1- (0.2,0) [0|0] "" Vector__XXX
 SG_ PCS_dLogPhAChannel1Data m14 : 16|16@1- (0.02,0) [0|0] "" Vector__XXX
 SG_ PCS_dLogPhAChannel2Data m15 : 16|16@1- (0.02,0) [0|0] "" Vector__XXX
 SG_ PCS_dLogPhAChannel3Data m16 : 16|16@1- (0.02,0) [0|0] "" Vector__XXX
 SG_ PCS_dLogPhAChannel4Data m17 : 16|16@1- (0.02,0) [0|0] "" Vector__XXX
 SG_ PCS_dcdcCLAControllerOutput m7 : 16|10@1+ (0.001,0) [0|0] "" Vector__XXX
 SG_ PCS_dcdcPchgStartHvBusVolt m24 : 16|12@1+ (0.146484375,0) [0|0] "" Vector__XXX
 SG_ PCS_chgInputFrequencyL2N m4 : 17|12@1+ (0.01,40) [0|0] "" Vector__XXX
 SG_ PCS_chgInputL2NVrms m3 : 17|12@1+ (0.2,0) [0|0] "" Vector__XXX
 SG_ PCS_chgPhALastShutdownReason m5 : 17|5@1+ (1,0) [0|0] "" Vector__XXX
 SG_ PCS_1V5Max10s m9 : 19|11@1+ (0.001,0) [0|0] "" Vector__XXX
 SG_ PCS_dcdcCurrentLimit m6 : 20|12@1+ (0.1,0) [0|0] "" Vector__XXX
 SG_ PCS_dcdcShortTimeUs m8 : 21|16@1+ (0.00048828125,0) [0|0] "" Vector__XXX
 SG_ PCS_chgPhBLastShutdownReason m5 : 22|5@1+ (1,0) [0|0] "" Vector__XXX
 SG_ PCS_chgPHCInputVPeak10s m13 : 23|9@1+ (1,0) [0|0] "" Vector__XXX
 SG_ PCS_chgPhAIntBusVTarget m0 : 23|9@1+ (1,0) [0|0] "" Vector__XXX
 SG_ PCS_chgPhAPchgVoltDeltaMax10s m10 : 23|8@1+ (0.5,0) [0|0] "" Vector__XXX
 SG_ PCS_chgPhBIntBusVTarget m1 : 23|9@1+ (1,0) [0|0] "" Vector__XXX
 SG_ PCS_chgPhBPchgVoltDeltaMax10s m11 : 23|8@1+ (0.5,0) [0|0] "" Vector__XXX
 SG_ PCS_chgPhCIntBusVTarget m2 : 23|9@1+ (1,0) [0|0] "" Vector__XXX
 SG_ PCS_chgPhCNoFlowBucket m20 : 23|9@1+ (0.01,0) [0|0] "" Vector__XXX
 SG_ PCS_chgPhCPchgVoltDeltaMax10s m12 : 23|8@1+ (0.5,0) [0|0] "" Vector__XXX
 SG_ PCS_chgPhBMachineEnabled m23 : 24|1@1+ (1,0) [0|0] "" Vector__XXX
 SG_ PCS_dcdcIntervalMaxHvBusVolt m18 : 24|13@1+ (0.1,0) [0|0] "" Vector__XXX
 SG_ PCS_dcdcIntervalMinHvBusVolt m19 : 24|13@1+ (0.1,0) [0|0] "" Vector__XXX
 SG_ PCS_chgPhBMachineRotorFreqDroop m23 : 25|10@1- (0.01,0) [0|0] "" Vector__XXX
 SG_ PCS_chgInputL3NVdc m21 : 26|10@1- (1,0) [0|0] "" Vector__XXX
 SG_ PCS_dcdcTankVoltage m7 : 26|11@1- (1,0) [0|0] "" Vector__XXX
 SG_ PCS_chgPhCLastShutdownReason m5 : 27|5@1+ (1,0) [0|0] "" Vector__XXX
 SG_ PCS_dcdcHvBusEstimated_C_uF m24 : 28|10@1+ (7.820136852394917,0) [0|0] "" Vector__XXX
 SG_ PCS_chgInputFrequencyL3N m4 : 29|12@1+ (0.01,40) [0|0] "" Vector__XXX
 SG_ PCS_chgInputL3NVrms m3 : 29|12@1+ (0.2,0) [0|0] "" Vector__XXX
 SG_ PCS_chgPhALifetimekWh m10 : 31|24@1+ (0.01,0) [0|0] "" Vector__XXX
 SG_ PCS_chgPhBLifetimekWh m11 : 31|24@1+ (0.01,0) [0|0] "" Vector__XXX
 SG_ PCS_chgPhCLifetimekWh m12 : 31|24@1+ (0.01,0) [0|0] "" Vector__XXX
 SG_ PCS_1V2Min10s m9 : 32|11@1+ (0.001,0) [0|0] "" Vector__XXX
 SG_ PCS_chgCurrentSensorOutOfBandUs m20 : 32|10@1+ (0.01,0) [0|0] "" Vector__XXX
 SG_ PCS_chgPhAInputFreqWobbleCnt m13 : 32|7@1- (1,0) [0|0] "" Vector__XXX
 SG_ PCS_chgPhAOutputI m0 : 32|8@1+ (0.1,0) [0|0] "" Vector__XXX
 SG_ PCS_chgPhARetryCount m5 : 32|3@1+ (1,0) [0|0] "" Vector__XXX
 SG_ PCS_chgPhBOutputI m1 : 32|8@1+ (0.1,0) [0|0] "" Vector__XXX
 SG_ PCS_chgPhCOutputI m2 : 32|8@1+ (0.1,0) [0|0] "" Vector__XXX
 SG_ PCS_chgPwmEnableLineErrorCount m22 : 32|10@1+ (1,0) [0|0] "" Vector__XXX
 SG_ PCS_dLogPhBChannel1Data m14 : 32|16@1- (0.02,0) [0|0] "" Vector__XXX
 SG_ PCS_dLogPhBChannel2Data m15 : 32|16@1- (0.02,0) [0|0] "" Vector__XXX
 SG_ PCS_dLogPhBChannel3Data m16 : 32|16@1- (0.02,0) [0|0] "" Vector__XXX
 SG_ PCS_dLogPhBChannel4Data m17 : 32|16@1- (0.02,0) [0|0] "" Vector__XXX
 SG_ PCS_dcdcLvOutputCurrentTempLimit m6 : 32|12@1+ (0.1,0) [0|0] "" Vector__XXX
 SG_ PCS_processorDieIdWafer m25 : 32|8@1+ (1,0) [0|0] "" Vector__XXX
 SG_ PCS_chgPhBMachineStatorCurrent m23 : 35|8@1- (0.2,0) [0|0] "" Vector__XXX
 SG_ PCS_chgPhBRetryCount m5 : 35|3@1+ (1,0) [0|0] "" Vector__XXX
 SG_ PCS_chgInputL1L2Vdc m21 : 36|10@1- (1,0) [0|0] "" Vector__XXX
 SG_ PCS_dcdcHalfPeriodUs m8 : 37|16@1+ (0.00048828125,0) [0|0] "" Vector__XXX
 SG_ PCS_dcdcTankVoltageTarget m7 : 37|10@1+ (1,0) [0|0] "" Vector__XXX
 SG_ PCS_chgPhCRetryCount m5 : 38|3@1+ (1,0) [0|0] "" Vector__XXX
 SG_ PCS_dcdcHvBusEstimated_R_kOhm m24 : 38|10@1+ (0.04887585532746823,0) [0|0] "" Vector__XXX
 SG_ PCS_chgPhBInputFreqWobbleCnt m13 : 39|7@1- (1,0) [0|0] "" Vector__XXX
 SG_ PCS_chgPhAInputCurrentLimitReason m0 : 40|3@1+ (1,0) [0|0] "" Vector__XXX
 SG_ PCS_chgPhBInputCurrentLimitReason m1 : 40|3@1+ (1,0) [0|0] "" Vector__XXX
 SG_ PCS_chgPhCInputCurrentLimitReason m2 : 40|3@1+ (1,0) [0|0] "" Vector__XXX
 SG_ PCS_dcdcIntervalMaxLvBusVolt m18 : 40|12@1+ (0.01,0) [0|0] "" Vector__XXX
 SG_ PCS_dcdcIntervalMinLvBusVolt m19 : 40|12@1+ (0.01,0) [0|0] "" Vector__XXX
 SG_ PCS_processorDieIdX m25 : 40|12@1+ (1,0) [0|0] "" Vector__XXX
 SG_ PCS_chgInputL1L2Vrms m3 : 41|12@1+ (0.2,0) [0|0] "" Vector__XXX
 SG_ PCS_chgInternalPhaseConfig m4 : 41|4@1+ (1,0) [0|0] "" Vector__XXX
 SG_ PCS_chgRetryCount m5 : 41|3@1+ (1,0) [0|0] "" Vector__XXX
 SG_ PCS_chgAcpwHeartbeatState m20 : 42|3@1+ (1,0) [0|0] "" Vector__XXX
 SG_ PCS_dcdcPwmEnableLineErrorCount m22 : 42|10@1+ (1,0) [0|0] "" Vector__XXX
 SG_ PCS_1V2Max10s m9 : 43|11@1+ (0.001,0) [0|0] "" Vector__XXX
 SG_ PCS_chgPhCMachineEnabled m23 : 43|1@1+ (1,0) [0|0] "" Vector__XXX
 SG_ PCS_chgPhCMachineRotorFreqDroop m23 : 44|10@1- (0.01,0) [0|0] "" Vector__XXX
 SG_ PCS_chgPhManCurrentToDist m5 : 44|10@1+ (0.1,0) [0|0] "" Vector__XXX
 SG_ PCS_dcdcLvOutputCurrentFiltered m6 : 44|12@1+ (0.1,0) [0|0] "" Vector__XXX
 SG_ PCS_chgPhasesPriority m4 : 45|6@1+ (1,0) [0|0] "" Vector__XXX
 SG_ PCS_chgInputNGVdc m21 : 46|10@1- (1,0) [0|0] "" Vector__XXX
 SG_ PCS_chgPhCInputFreqWobbleCnt m13 : 46|7@1- (1,0) [0|0] "" Vector__XXX
 SG_ PCS_chgKwhLostByFreqDroop m20 : 48|8@1+ (0.1,0) [0|0] "" Vector__XXX
 SG_ PCS_dLogPhCChannel1Data m14 : 48|16@1- (0.02,0) [0|0] "" Vector__XXX
 SG_ PCS_dLogPhCChannel2Data m15 : 48|16@1- (0.02,0) [0|0] "" Vector__XXX
 SG_ PCS_dLogPhCChannel3Data m16 : 48|16@1- (0.02,0) [0|0] "" Vector__XXX
 SG_ PCS_dLogPhCChannel4Data m17 : 48|16@1- (0.02,0) [0|0] "" Vector__XXX
 SG_ PCS_dcdcClaCurrentFreq m7 : 48|12@1+ (0.09765625,0) [0|0] "" Vector__XXX
 SG_ PCS_chgOutputV m4 : 51|12@1+ (0.146484375,0) [0|0] "" Vector__XXX
 SG_ PCS_dcdcIntervalMaxLvOutputCurr m18 : 52|12@1+ (1,0) [0|0] "" Vector__XXX
 SG_ PCS_dcdcIntervalMinLvOutputCurr m19 : 52|12@1+ (1,0) [0|0] "" Vector__XXX
 SG_ PCS_processorDieIdY m25 : 52|12@1+ (1,0) [0|0] "" Vector__XXX
 SG_ PCS_chgInputNGVrms m3 : 53|9@1+ (1,0) [0|0] "" Vector__XXX
 SG_ PCS_chgLineVoltagePresenceDelay m13 : 53|11@1+ (20,0) [0|0] "" Vector__XXX
 SG_ PCS_dcdcLvBusVoltTargetWithOffset m8 : 53|11@1+ (0.01,0) [0|0] "" Vector__XXX
 SG_ PCS_5VNMax10s m9 : 54|10@1+ (0.01,0) [0|0] "" Vector__XXX
 SG_ PCS_chgL1NPllLocked m5 : 54|1@1+ (1,0) [0|0] "" Vector__XXX
 SG_ PCS_chgPhCMachineStatorCurrent m23 : 54|8@1- (0.2,0) [0|0] "" Vector__XXX
 SG_ PCS_chgL2NPllLocked m5 : 55|1@1+ (1,0) [0|0] "" Vector__XXX
 SG_ PCS_chgPhATransientRetryCount m10 : 55|9@1+ (0.1,0) [0|0] "" Vector__XXX
 SG_ PCS_chgPhBTransientRetryCount m11 : 55|9@1+ (0.1,0) [0|0] "" Vector__XXX
 SG_ PCS_chgPhCTransientRetryCount m12 : 55|9@1+ (0.1,0) [0|0] "" Vector__XXX
 SG_ PCS_chgL3NPllLocked m5 : 56|1@1+ (1,0) [0|0] "" Vector__XXX
 SG_ PCS_chgReqKwhLostByFreqDroop m20 : 56|8@1+ (0.1,0) [0|0] "" Vector__XXX
 SG_ PCS_numAlertsSet m22 : 56|7@1+ (1,0) [0|0] "" Vector__XXX
 SG_ PCS_chgL1L2PllLocked m5 : 57|1@1+ (1,0) [0|0] "" Vector__XXX
 SG_ PCS_chgNgPllLocked m5 : 58|1@1+ (1,0) [0|0] "" Vector__XXX
 SG_ PCS_chgPhManOptimalPhsToUse m5 : 59|2@1+ (1,0) [0|0] "" Vector__XXX
 SG_ PCS_chg5VL1Enable m5 : 61|1@1+ (1,0) [0|0] "" Vector__XXX

BO_ 711 CMPD_faultsAndExtras: 8 Vector__XXX
 SG_ CMPD_limitUnderVoltage : 0|1@1+ (1,0) [0|0] "" Vector__XXX
 SG_ CMPD_limitOverCurrentPhase : 1|1@1+ (1,0) [0|0] "" Vector__XXX
 SG_ CMPD_limitOverCurrentHVDC : 2|1@1+ (1,0) [0|0] "" Vector__XXX
 SG_ CMPD_VCFRONTCANTimeout : 8|1@1+ (1,0) [0|0] "" Vector__XXX
 SG_ CMPD_LVUnderVoltage : 9|1@1+ (1,0) [0|0] "" Vector__XXX
 SG_ CMPD_LVOverVoltage : 10|1@1+ (1,0) [0|0] "" Vector__XXX
 SG_ CMPD_HVOverVoltage : 11|1@1+ (1,0) [0|0] "" Vector__XXX
 SG_ CMPD_HVUnderVoltage : 12|1@1+ (1,0) [0|0] "" Vector__XXX
 SG_ CMPD_tempSnsFaultIPM1 : 13|1@1+ (1,0) [0|0] "" Vector__XXX
 SG_ CMPD_tempSnsFaultIPM2 : 14|1@1+ (1,0) [0|0] "" Vector__XXX
 SG_ CMPD_tempSnsFaultCPU : 15|1@1+ (1,0) [0|0] "" Vector__XXX
 SG_ CMPD_currentSnsError : 16|1@1+ (1,0) [0|0] "" Vector__XXX
 SG_ CMPD_selfTestFailCPU : 17|1@1+ (1,0) [0|0] "" Vector__XXX
 SG_ CMPD_internalPowerSupplyFault : 18|1@1+ (1,0) [0|0] "" Vector__XXX
 SG_ CMPD_inverterOpenCircuit : 19|1@1+ (1,0) [0|0] "" Vector__XXX
 SG_ CMPD_shortCircuit : 20|1@1+ (1,0) [0|0] "" Vector__XXX
 SG_ CMPD_warnOverTemperature : 21|1@1+ (1,0) [0|0] "" Vector__XXX
 SG_ CMPD_overTemperature : 22|1@1+ (1,0) [0|0] "" Vector__XXX
 SG_ CMPD_underTemperature : 23|1@1+ (1,0) [0|0] "" Vector__XXX
 SG_ CMPD_failedStart : 24|1@1+ (1,0) [0|0] "" Vector__XXX
 SG_ CMPD_failedStartRepeated : 25|1@1+ (1,0) [0|0] "" Vector__XXX
 SG_ CMPD_overCurrent : 26|1@1+ (1,0) [0|0] "" Vector__XXX
 SG_ CMPD_overloadStatus : 27|2@1+ (1,0) [0|0] "" Vector__XXX
 SG_ CMPD_overloadStartFaultDetection : 29|1@1+ (1,0) [0|0] "" Vector__XXX
 SG_ CMPD_overloadLossOfSync : 30|1@1+ (1,0) [0|0] "" Vector__XXX
 SG_ CMPD_overloadRestrictionCurrent : 31|1@1+ (1,0) [0|0] "" Vector__XXX
 SG_ CMPD_overloadDetectionOfSpeed : 32|1@1+ (1,0) [0|0] "" Vector__XXX
 SG_ CMPD_IGBTTemperature : 40|8@1+ (1,-40) [0|0] "" Vector__XXX
 SG_ CMPD_inverterTemperature : 48|8@1+ (1,-40) [0|0] "" Vector__XXX
 SG_ CMPD_inputLVVoltage : 56|8@1+ (0.1,0) [0|0] "" Vector__XXX

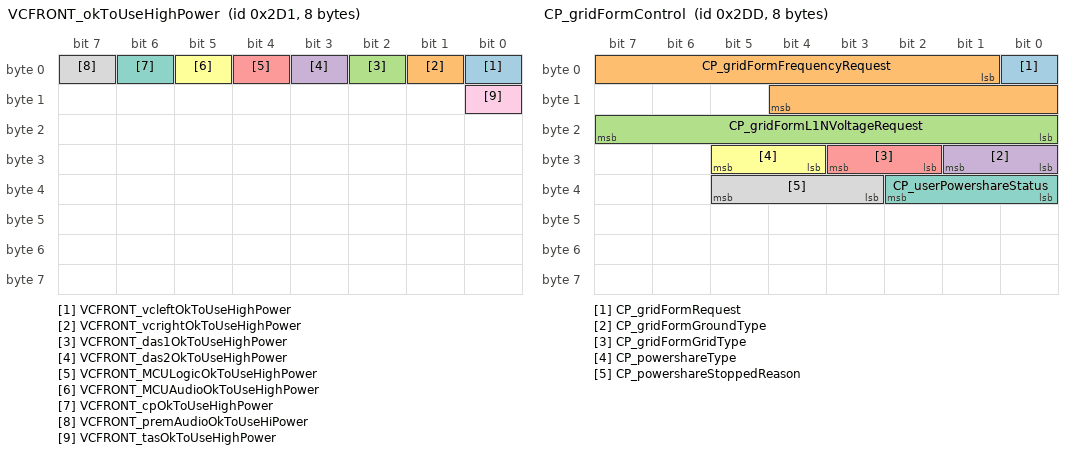
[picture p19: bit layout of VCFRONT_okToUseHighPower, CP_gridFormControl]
BO_ 721 VCFRONT_okToUseHighPower: 8 Vector__XXX
 SG_ VCFRONT_vcleftOkToUseHighPower : 0|1@1+ (1,0) [0|0] "" Vector__XXX
 SG_ VCFRONT_vcrightOkToUseHighPower : 1|1@1+ (1,0) [0|0] "" Vector__XXX
 SG_ VCFRONT_das1OkToUseHighPower : 2|1@1+ (1,0) [0|0] "" Vector__XXX
 SG_ VCFRONT_das2OkToUseHighPower : 3|1@1+ (1,0) [0|0] "" Vector__XXX
 SG_ VCFRONT_MCULogicOkToUseHighPower : 4|1@1+ (1,0) [0|0] "" Vector__XXX
 SG_ VCFRONT_MCUAudioOkToUseHighPower : 5|1@1+ (1,0) [0|0] "" Vector__XXX
 SG_ VCFRONT_cpOkToUseHighPower : 6|1@1+ (1,0) [0|0] "" Vector__XXX
 SG_ VCFRONT_premAudioOkToUseHiPower : 7|1@1+ (1,0) [0|0] "" Vector__XXX
 SG_ VCFRONT_tasOkToUseHighPower : 8|1@1+ (1,0) [0|0] "" Vector__XXX

BO_ 722 BMS_driveLimits: 8 Vector__XXX
 SG_ BMS_minBusVoltage : 0|16@1+ (0.02,0) [0|0] "" Vector__XXX
 SG_ BMS_maxBusVoltage : 16|16@1+ (0.02,0) [0|0] "" Vector__XXX
 SG_ BMS_maxChargeCurrent : 32|14@1+ (0.1,0) [0|0] "" Vector__XXX
 SG_ BMS_maxDischargeCurrent : 48|14@1+ (0.15,0) [0|0] "" Vector__XXX

BO_ 723 UI_solarData: 8 Vector__XXX
 SG_ UI_solarAzimuthAngle : 0|16@1- (1,0) [0|0] "" Vector__XXX
 SG_ UI_solarAzimuthAngleCarRef : 16|9@1- (1,0) [0|0] "" Vector__XXX
 SG_ UI_isSunUp : 25|2@1+ (1,0) [0|0] "" Vector__XXX
 SG_ UI_solarElevationAngle : 32|8@1- (1,0) [0|0] "" Vector__XXX
 SG_ UI_screenPCBTemperature : 40|8@1- (0.5,40) [0|0] "" Vector__XXX
 SG_ UI_minsToSunset : 48|8@1+ (10,0) [0|0] "" Vector__XXX
 SG_ UI_minsToSunrise : 56|8@1+ (10,0) [0|0] "" Vector__XXX

BO_ 727 VCLEFT_pitchEstimation: 8 Vector__XXX
 SG_ VCLEFT_pitchEstimateFusionState : 0|3@1+ (1,0) [0|0] "" Vector__XXX
 SG_ VCLEFT_pitchEstimateStateTransitionID : 3|5@1+ (1,0) [0|0] "" Vector__XXX
 SG_ VCLEFT_pitchEstimateArbitratedState : 8|3@1+ (1,0) [0|0] "" Vector__XXX
 SG_ VCLEFT_pitchEstimateOKForAiming : 11|1@1+ (1,0) [0|0] "" Vector__XXX
 SG_ VCLEFT_pitchEstimateFusionRaw : 12|10@1- (0.0002,0) [0|0] "" Vector__XXX
 SG_ VCLEFT_pitchEstimate : 22|10@1- (0.0002,0) [0|0] "" Vector__XXX

BO_ 728 ICR_vehNm: 8 Vector__XXX
 SG_ ICR_nmGoingToSleep : 0|1@1+ (1,0) [0|0] "" Vector__XXX
 SG_ ICR_nmWakeUpBus : 1|1@1+ (1,0) [0|0] "" Vector__XXX
 SG_ ICR_nmKeepAwakeReason : 4|1@1+ (1,0) [0|0] "" Vector__XXX
 SG_ ICR_nmWakeUpReason : 8|3@1+ (1,0) [0|0] "" Vector__XXX

BO_ 733 CP_gridFormControl: 8 Vector__XXX
 SG_ CP_gridFormRequest : 0|1@1+ (1,0) [0|0] "" Vector__XXX
 SG_ CP_gridFormFrequencyRequest : 1|12@1+ (0.01,40) [0|0] "" Vector__XXX
 SG_ CP_gridFormL1NVoltageRequest : 16|8@1+ (1,40) [0|0] "" Vector__XXX
 SG_ CP_gridFormGroundType : 24|2@1+ (1,0) [0|0] "" Vector__XXX
 SG_ CP_gridFormGridType : 26|2@1+ (1,0) [0|0] "" Vector__XXX
 SG_ CP_powershareType : 28|2@1+ (1,0) [0|0] "" Vector__XXX
 SG_ CP_userPowershareStatus : 32|3@1+ (1,0) [0|0] "" Vector__XXX
 SG_ CP_powershareStoppedReason : 35|3@1+ (1,0) [0|0] "" Vector__XXX

BO_ 735 PCS2_v2xInfo: 8 Vector__XXX
 SG_ PCS2_v2xDispatchableRealPowerMin : 0|9@1- (0.05,-9.95) [0|0] "" Vector__XXX
 SG_ PCS2_v2xDispatchableRealPowerMax : 9|9@1+ (0.05,0) [0|0] "" Vector__XXX
 SG_ PCS2_v2xVoltage : 18|11@1+ (0.2,0) [0|0] "" Vector__XXX
 SG_ PCS2_v2xFrequency : 32|12@1+ (0.01,40) [0|0] "" Vector__XXX
 SG_ PCS2_v2xRealPower : 44|10@1- (0.05,0) [0|0] "" Vector__XXX
 SG_ PCS2_v2xReactivePower : 54|10@1- (0.05,0) [0|0] "" Vector__XXX

BO_ 737 VCFRONT_status: 8 Vector__XXX
 SG_ VCFRONT_statusIndex M : 0|3@1+ (1,0) [0|0] "" Vector__XXX
 SG_ VCFRONT_5VARailStable m3 : 3|1@1+ (1,0) [0|0] "" Vector__XXX
 SG_ VCFRONT_frunkLatchStatus m0 : 3|4@1+ (1,0) [0|0] "" Vector__XXX
 SG_ VCFRONT_iBoosterWakeLine m1 : 3|1@1+ (1,0) [0|0] "" Vector__XXX
 SG_ VCFRONT_5VBRailStable m3 : 4|1@1+ (1,0) [0|0] "" Vector__XXX
 SG_ VCFRONT_epasWakeLine m1 : 4|1@1+ (1,0) [0|0] "" Vector__XXX
 SG_ VCFRONT_12VARailStable m3 : 5|1@1+ (1,0) [0|0] "" Vector__XXX
 SG_ VCFRONT_UP_inDriveState m5 : 5|1@1+ (1,0) [0|0] "" Vector__XXX
 SG_ VCFRONT_iBoosterStateDBG m1 : 5|3@1+ (1,0) [0|0] "" Vector__XXX
 SG_ VCFRONT_12VBRailStable m3 : 6|1@1+ (1,0) [0|0] "" Vector__XXX
 SG_ VCFRONT_UP_UIDisplayOnForUser m5 : 6|1@1+ (1,0) [0|0] "" Vector__XXX
 SG_ VCFRONT_cabinCoolingCapacityLimited m4 : 6|1@1+ (1,0) [0|0] "" Vector__XXX
 SG_ VCFRONT_UP_steeringWheelButtonInteraction m5 : 7|1@1+ (1,0) [0|0] "" Vector__XXX
 SG_ VCFRONT_cabinHeatingCapacityLimited m4 : 7|1@1+ (1,0) [0|0] "" Vector__XXX
 SG_ VCFRONT_railAState m3 : 7|1@1+ (1,0) [0|0] "" Vector__XXX
 SG_ VCFRONT_UP_frontDriverDoorOpen m5 : 8|1@1+ (1,0) [0|0] "" Vector__XXX
 SG_ VCFRONT_compPowerSupportingHvac m4 : 8|11@1+ (10,0) [0|0] "" Vector__XXX
 SG_ VCFRONT_maxEvapHeatRejection m2 : 8|8@1+ (65,0) [0|0] "" Vector__XXX
 SG_ VCFRONT_railBState m3 : 8|1@1+ (1,0) [0|0] "" Vector__XXX
 SG_ VCFRONT_vehicleStatusDBG m1 : 8|5@1+ (1,0) [0|0] "" Vector__XXX
 SG_ VCFRONT_wiperSpeed m0 : 8|4@1+ (1,0) [0|0] "" Vector__XXX
 SG_ VCFRONT_ChargePumpVoltageStable m3 : 9|1@1+ (1,0) [0|0] "" Vector__XXX
 SG_ VCFRONT_UP_frontPassengerDoorOpen m5 : 9|1@1+ (1,0) [0|0] "" Vector__XXX
 SG_ VCFRONT_PEResetLineState m3 : 10|1@1+ (1,0) [0|0] "" Vector__XXX
 SG_ VCFRONT_UP_rearDriverDoorOpen m5 : 10|1@1+ (1,0) [0|0] "" Vector__XXX
 SG_ VCFRONT_HSDInitCompleteU13 m3 : 11|1@1+ (1,0) [0|0] "" Vector__XXX
 SG_ VCFRONT_UP_rearPassengerDoorOpen m5 : 11|1@1+ (1,0) [0|0] "" Vector__XXX
 SG_ VCFRONT_HSDInitCompleteU16 m3 : 12|1@1+ (1,0) [0|0] "" Vector__XXX
 SG_ VCFRONT_UP_trunkOpen m5 : 12|1@1+ (1,0) [0|0] "" Vector__XXX
 SG_ VCFRONT_wiperPosition m0 : 12|3@1+ (1,0) [0|0] "" Vector__XXX
 SG_ VCFRONT_UP_inTransportMode m5 : 13|1@1+ (1,0) [0|0] "" Vector__XXX
 SG_ VCFRONT_timeSpentSleeping m1 : 13|10@1+ (1,0) [0|0] "" Vector__XXX
 SG_ VCFRONT_UP_anyClosureIsOpen m5 : 14|1@1+ (1,0) [0|0] "" Vector__XXX
 SG_ VCFRONT_UP_driverPresent m5 : 15|1@1+ (1,0) [0|0] "" Vector__XXX
 SG_ VCFRONT_wiperBlocked m0 : 15|1@1+ (1,0) [0|0] "" Vector__XXX
 SG_ VCFRONT_UP_brakePressed m5 : 16|1@1+ (1,0) [0|0] "" Vector__XXX
 SG_ VCFRONT_minEvapHeatRejection m2 : 16|8@1+ (15,0) [0|0] "" Vector__XXX
 SG_ VCFRONT_vbatMonitorVoltage m3 : 16|12@1+ (0.005443676098,0) [0|0] "" Vector__XXX
 SG_ VCFRONT_wiperState m0 : 16|4@1+ (1,0) [0|0] "" Vector__XXX
 SG_ VCFRONT_UP_chargePortDoorOpen m5 : 17|1@1+ (1,0) [0|0] "" Vector__XXX
 SG_ VCFRONT_UP_UIChargePortDoorRequest m5 : 18|1@1+ (1,0) [0|0] "" Vector__XXX
 SG_ VCFRONT_UP_UIUserActivity m5 : 19|1@1+ (1,0) [0|0] "" Vector__XXX
 SG_ VCFRONT_compPowerSupportingPT m4 : 19|11@1+ (10,0) [0|0] "" Vector__XXX
 SG_ VCFRONT_UP_passengerPresent m5 : 20|1@1+ (1,0) [0|0] "" Vector__XXX
 SG_ VCFRONT_crashDetectedType m0 : 20|2@1+ (1,0) [0|0] "" Vector__XXX
 SG_ VCFRONT_UP_chargeStateTransitioned m5 : 21|1@1+ (1,0) [0|0] "" Vector__XXX
 SG_ VCFRONT_crashState m0 : 22|2@1+ (1,0) [0|0] "" Vector__XXX
 SG_ VCFRONT_crashUnlockOverrideSet m0 : 24|1@1+ (1,0) [0|0] "" Vector__XXX
 SG_ VCFRONT_freezeEvapITerm m2 : 24|1@1+ (1,0) [0|0] "" Vector__XXX
 SG_ VCFRONT_sleepCurrent m1 : 24|12@1+ (0.125,-511.875) [0|0] "" Vector__XXX
 SG_ VCFRONT_isEvapOperationAllowed m2 : 25|1@1+ (1,0) [0|0] "" Vector__XXX
 SG_ VCFRONT_chillerDemandActive m2 : 26|1@1+ (1,0) [0|0] "" Vector__XXX
 SG_ VCFRONT_compPerfRecoveryLimited m2 : 27|1@1+ (1,0) [0|0] "" Vector__XXX
 SG_ VCFRONT_AS8510Voltage m3 : 28|12@1+ (0.005443676098,0) [0|0] "" Vector__XXX
 SG_ VCFRONT_hvacModeNotAttainable m2 : 28|1@1+ (1,0) [0|0] "" Vector__XXX
 SG_ VCFRONT_hasLowRefrigerant m2 : 29|1@1+ (1,0) [0|0] "" Vector__XXX
 SG_ VCFRONT_isColdStartRunning m2 : 30|1@1+ (1,0) [0|0] "" Vector__XXX
 SG_ VCFRONT_maxHeatingPowerLeftCC m4 : 30|7@1+ (100,0) [0|0] "" Vector__XXX
 SG_ VCFRONT_isHeatPumpOilPurgeActive m2 : 31|1@1+ (1,0) [0|0] "" Vector__XXX
 SG_ VCFRONT_lastUserPresenceUpdateEpochTime m5 : 32|32@1+ (1,0) [0|0] "" Vector__XXX
 SG_ VCFRONT_pressureRefrigSuction m2 : 32|7@1+ (0.125,0) [0|0] "" Vector__XXX
 SG_ VCFRONT_wiperHealth m0 : 32|3@1+ (1,0) [0|0] "" Vector__XXX
 SG_ VCFRONT_wiperLINHealth m0 : 35|3@1+ (1,0) [0|0] "" Vector__XXX
 SG_ VCFRONT_hibernationState m1 : 36|3@1+ (1,0) [0|0] "" Vector__XXX
 SG_ VCFRONT_maxHeatingPowerRightCC m4 : 37|7@1+ (100,0) [0|0] "" Vector__XXX
 SG_ VCFRONT_frunkLatchCurrent m0 : 40|8@1- (0.15748031496062992,0) [0|0] "" Vector__XXX
 SG_ VCFRONT_pressureRefrigDischarge m2 : 40|9@1+ (0.08,0) [0|0] "" Vector__XXX
 SG_ VCFRONT_vbatProt m3 : 40|12@1+ (0.005443676098,0) [0|0] "" Vector__XXX
 SG_ VCFRONT_wiperECUType m1 : 40|2@1+ (1,0) [0|0] "" Vector__XXX
 SG_ VCFRONT_wiperHeaterState m1 : 42|3@1+ (1,0) [0|0] "" Vector__XXX
 SG_ VCFRONT_activeLouverOpenPos m4 : 44|7@1+ (1,0) [0|0] "" Vector__XXX
 SG_ VCFRONT_occupantCount m1 : 45|3@1+ (1,0) [0|0] "" Vector__XXX
 SG_ VCFRONT_closureEasterEggState m1 : 48|3@1+ (1,0) [0|0] "" Vector__XXX
 SG_ VCFRONT_frunkInteriorRelSwitch m0 : 48|1@1+ (1,0) [0|0] "" Vector__XXX
 SG_ VCFRONT_anyClosureOpen m0 : 49|1@1+ (1,0) [0|0] "" Vector__XXX
 SG_ VCFRONT_hvacPerfTestCommand m2 : 49|3@1+ (1,0) [0|0] "" Vector__XXX
 SG_ VCFRONT_anyDoorOpen m0 : 50|1@1+ (1,0) [0|0] "" Vector__XXX
 SG_ VCFRONT_activeLouverState m4 : 51|5@1+ (1,0) [0|0] "" Vector__XXX
 SG_ VCFRONT_espWakeLine m1 : 51|1@1+ (1,0) [0|0] "" Vector__XXX
 SG_ VCFRONT_hornOn m0 : 51|1@1+ (1,0) [0|0] "" Vector__XXX
 SG_ VCFRONT_allowEvapInLowAmbient m1 : 52|1@1+ (1,0) [0|0] "" Vector__XXX
 SG_ VCFRONT_coolantFillRoutineStatus m2 : 52|2@1+ (1,0) [0|0] "" Vector__XXX
 SG_ VCFRONT_logVerbosity m3 : 52|3@1+ (1,0) [0|0] "" Vector__XXX
 SG_ VCFRONT_radarHeaterState m0 : 52|3@1+ (1,0) [0|0] "" Vector__XXX
 SG_ VCFRONT_potentialRadiatorSteam m1 : 53|1@1+ (1,0) [0|0] "" Vector__XXX
 SG_ VCFRONT_potentialRadiatorSteamUI m1 : 54|1@1+ (1,0) [0|0] "" Vector__XXX
 SG_ VCFRONT_refrigFillRoutineStatus m2 : 54|2@1+ (1,0) [0|0] "" Vector__XXX
 SG_ VCFRONT_hvacReqOffForFasterCharge m1 : 55|1@1+ (1,0) [0|0] "" Vector__XXX
 SG_ VCFRONT_trunkExteriorWakeSwitch m0 : 55|1@1+ (1,0) [0|0] "" Vector__XXX
 SG_ VCFRONT_isCOP1Running m2 : 56|1@1+ (1,0) [0|0] "" Vector__XXX
 SG_ VCFRONT_limitedSplitTempDeltaEnforced m1 : 56|1@1+ (1,0) [0|0] "" Vector__XXX
 SG_ VCFRONT_windshieldCameraHeaterPower m4 : 56|6@1+ (2.5,0) [0|0] "" Vector__XXX
 SG_ VCFRONT_closeValvesRoutineStatus m2 : 57|2@1+ (1,0) [0|0] "" Vector__XXX
 SG_ VCFRONT_passengerBuckleStatus m0 : 57|1@1+ (1,0) [0|0] "" Vector__XXX
 SG_ VCFRONT_frunkLatchType m0 : 58|2@1+ (1,0) [0|0] "" Vector__XXX
 SG_ VCFRONT_thermalPerfTestRunning m2 : 59|1@1+ (1,0) [0|0] "" Vector__XXX
 SG_ VCFRONT_headlampLeftFanStatus m0 : 60|1@1+ (1,0) [0|0] "" Vector__XXX
 SG_ VCFRONT_headlampRightFanStatus m0 : 61|1@1+ (1,0) [0|0] "" Vector__XXX
 SG_ VCFRONT_frunkAccessPost m0 : 62|1@1+ (1,0) [0|0] "" Vector__XXX
 SG_ VCFRONT_isActiveHeatingBattery m0 : 63|1@1+ (1,0) [0|0] "" Vector__XXX
